VERSION ""

NS_ :

BS_:

BU_: WCM4 WCM3 WCM2 WCM VPM VLM VKM VICM VECM VDM VCU_RTOS_ETH VCU_ENTRY_ETH VCU_AGVM_ETH VCU UVM UPM TIM TEST_TOOL_1 TCP_ETH TCP TCM TCCM SRR_SRR_ETH SRR_SRR SRR_SLR_ETH SRR_SLR SRR_RR SRR_RF_ETH SRR_RF SRR_LR_CR SRR_LF_ETH SRR_LF SIB SDM SCL SBZA_R SBZA_L SBM SAM_RR SAM_RF SAM_LR SAM_LF SAM_BH SADS RadioLow_ETH RadioLow RSI_RTOS_ETH RSI RDCM PTM PLCM PFCM PDR_ETH PDR PCM PA ODS2 ODS NVM MTCM_R MTCM_L MSM_RR MSM_P MSM_LR MSM_D MSB2 MSB1 MRCM_R MRCM_L MFC LRR_RR_ETH LRR_LR_ETH LRR_CF_ETH LRR LRL_CF_ETH LIB_48V LIB1 IPC_INT IPC_GP IPC ICS_Info ICCM HVAC_FP_R HVAC_FP_F HUD_CAN HDLM FPI_RTOS_ETH FPI FOPM FCM_LC FCM EPSb EPS_1 EPSRAb EPSRAa EPS EOCM_HC_Superset EOCM_HCP2 EOCM ELM ECP_X1 ECP_S2 ECP_S ECP_MC ECP_H3 ECP_H2 ECP_H1 ECP_E ECM EBCM DMS DEFC DCM CSM_ETH CSM_AV CSM CGM_OTA_ETH CGM BSM_MH BSM_HEV BSM BCM ARS ARB APA AOS AMP ALC AHS AHL_AFL ADIMb ADIMa ACP2_MCU

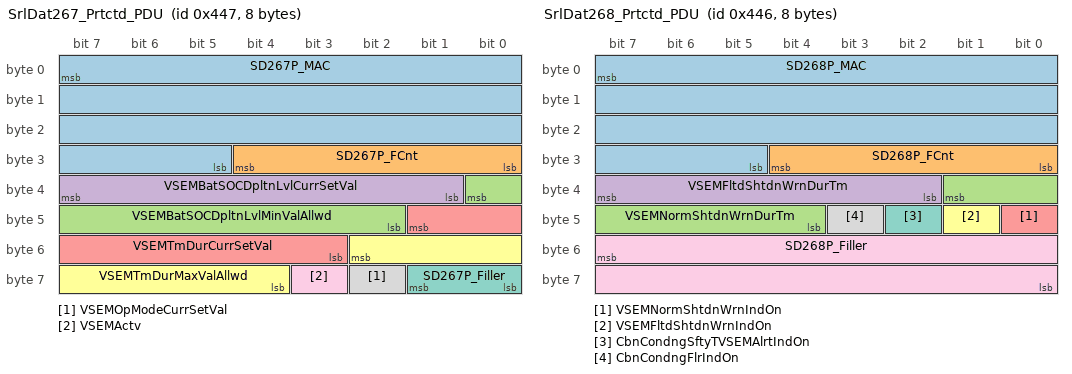
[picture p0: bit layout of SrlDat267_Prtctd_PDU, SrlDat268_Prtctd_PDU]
BO_ 1095 SrlDat267_Prtctd_PDU: 8 CGM
 SG_ SD267P_MAC : 7|27@0+ (1,0) [0|1.34218e+008] "" TCP
 SG_ SD267P_FCnt : 28|5@0+ (1,0) [0|31] "" TCP
 SG_ VSEMBatSOCDpltnLvlMinValAllwd : 32|7@0+ (1,0) [0|127] "%" TCP,VCU
 SG_ VSEMBatSOCDpltnLvlCurrSetVal : 39|7@0+ (1,0) [0|127] "%" TCP,VCU
 SG_ VSEMTmDurCurrSetVal : 41|7@0+ (15,0) [0|1905] "min" TCP,VCU
 SG_ VSEMTmDurMaxValAllwd : 50|7@0+ (15,0) [0|1905] "min" TCP,VCU
 SG_ SD267P_Filler : 57|2@0+ (1,0) [0|3] "" TCP
 SG_ VSEMOpModeCurrSetVal : 58|1@0+ (1,0) [0|1] "" TCP,VCU
 SG_ VSEMActv : 59|1@0+ (1,0) [0|1] "" TCP,VCU

BO_ 1092 SrlDat268_PCSM_PDU: 8 CGM
 SG_ SrlDat268_PCSM : 0|64@1+ (1,0) [0|1.84467e+019] "" TCP

BO_ 1094 SrlDat268_Prtctd_PDU: 8 CGM
 SG_ SD268P_MAC : 7|27@0+ (1,0) [0|1.34218e+008] "" TCP
 SG_ SD268P_FCnt : 28|5@0+ (1,0) [0|31] "" TCP
 SG_ VSEMNormShtdnWrnDurTm : 33|6@0+ (1,0) [0|63] "min" TCP,VCU
 SG_ VSEMFltdShtdnWrnDurTm : 39|6@0+ (1,0) [0|63] "min" TCP,VCU
 SG_ VSEMNormShtdnWrnIndOn : 40|1@0+ (1,0) [0|1] "" TCP,VCU
 SG_ VSEMFltdShtdnWrnIndOn : 41|1@0+ (1,0) [0|1] "" TCP,VCU
 SG_ CbnCondngSftyTVSEMAlrtIndOn : 42|1@0+ (1,0) [0|1] "" TCP,VCU
 SG_ CbnCondngFlrIndOn : 43|1@0+ (1,0) [0|1] "" TCP,VCU
 SG_ SD268P_Filler : 55|16@0+ (1,0) [0|65535] "" TCP

BO_ 1096 SrlDat269_PCSM_PDU: 8 VCU
 SG_ SrlDat269_PCSM : 0|64@1+ (1,0) [0|1.84467e+019] "" PLCM,TCP

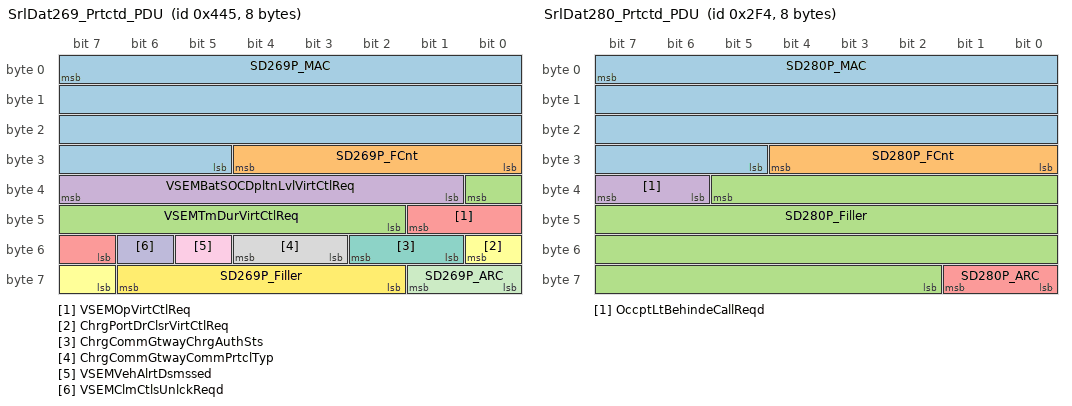
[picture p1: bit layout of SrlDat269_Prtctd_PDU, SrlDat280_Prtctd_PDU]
BO_ 1093 SrlDat269_Prtctd_PDU: 8 VCU
 SG_ SD269P_MAC : 7|27@0+ (1,0) [0|1.34218e+008] "" PLCM,TCP
 SG_ SD269P_FCnt : 28|5@0+ (1,0) [0|31] "" PLCM,TCP
 SG_ VSEMTmDurVirtCtlReq : 32|7@0+ (15,0) [0|1905] "min" PLCM,TCP
 SG_ VSEMBatSOCDpltnLvlVirtCtlReq : 39|7@0+ (1,0) [0|127] "%" PLCM,TCP
 SG_ VSEMOpVirtCtlReq : 41|3@0+ (1,0) [0|5] "" PLCM,TCP
 SG_ ChrgPortDrClsrVirtCtlReq : 48|2@0+ (1,0) [0|2] "" PLCM,TCP
 SG_ ChrgCommGtwayChrgAuthSts : 50|2@0+ (1,0) [0|3] "" PLCM,TCP
 SG_ ChrgCommGtwayCommPrtclTyp : 52|2@0+ (1,0) [0|3] "" PLCM,TCP
 SG_ VSEMVehAlrtDsmssed : 53|1@0+ (1,0) [0|1] "" PLCM,TCP
 SG_ VSEMClmCtlsUnlckReqd : 54|1@0+ (1,0) [0|1] "" PLCM,TCP
 SG_ SD269P_ARC : 57|2@0+ (1,0) [0|3] "" PLCM,TCP
 SG_ SD269P_Filler : 62|5@0+ (1,0) [0|31] "" PLCM,TCP

BO_ 976 SrlDat280_PCSM_PDU: 8 CGM
 SG_ SrlDat280_PCSM : 0|64@1+ (1,0) [0|1.84467e+019] "" TCP

BO_ 756 SrlDat280_Prtctd_PDU: 8 CGM
 SG_ SD280P_MAC : 7|27@0+ (1,0) [0|1.34218e+008] "" TCP
 SG_ SD280P_FCnt : 28|5@0+ (1,0) [0|31] "" TCP
 SG_ SD280P_Filler : 37|28@0+ (1,0) [0|2.68435e+008] "" TCP
 SG_ OccptLtBehindeCallReqd : 39|2@0+ (1,0) [0|3] "" TCP
 SG_ SD280P_ARC : 57|2@0+ (1,0) [0|3] "" TCP

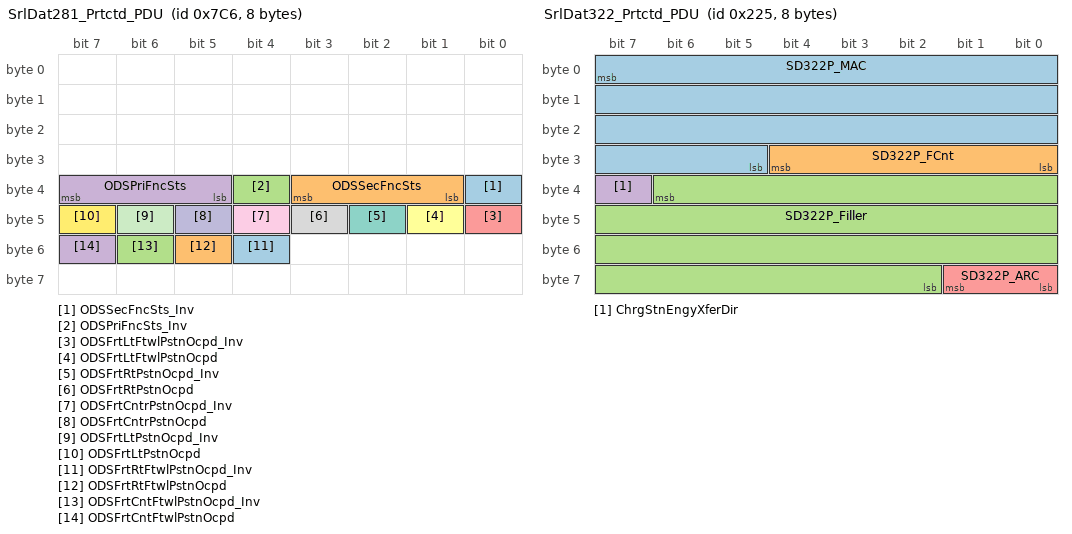
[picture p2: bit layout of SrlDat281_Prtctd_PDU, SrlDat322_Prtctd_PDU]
BO_ 1990 SrlDat281_Prtctd_PDU: 8 CGM
 SG_ ODSSecFncSts_Inv : 32|1@0+ (1,0) [0|1] "" TCP
 SG_ ODSSecFncSts : 35|3@0+ (1,0) [0|7] "" TCP
 SG_ ODSPriFncSts_Inv : 36|1@0+ (1,0) [0|1] "" TCP
 SG_ ODSPriFncSts : 39|3@0+ (1,0) [0|7] "" TCP
 SG_ ODSFrtLtFtwlPstnOcpd_Inv : 40|1@0+ (1,0) [0|1] "" TCP
 SG_ ODSFrtLtFtwlPstnOcpd : 41|1@0+ (1,0) [0|1] "" TCP
 SG_ ODSFrtRtPstnOcpd_Inv : 42|1@0+ (1,0) [0|1] "" TCP
 SG_ ODSFrtRtPstnOcpd : 43|1@0+ (1,0) [0|1] "" TCP
 SG_ ODSFrtCntrPstnOcpd_Inv : 44|1@0+ (1,0) [0|1] "" TCP
 SG_ ODSFrtCntrPstnOcpd : 45|1@0+ (1,0) [0|1] "" TCP
 SG_ ODSFrtLtPstnOcpd_Inv : 46|1@0+ (1,0) [0|1] "" TCP
 SG_ ODSFrtLtPstnOcpd : 47|1@0+ (1,0) [0|1] "" TCP
 SG_ ODSFrtRtFtwlPstnOcpd_Inv : 52|1@0+ (1,0) [0|1] "" TCP
 SG_ ODSFrtRtFtwlPstnOcpd : 53|1@0+ (1,0) [0|1] "" TCP
 SG_ ODSFrtCntFtwlPstnOcpd_Inv : 54|1@0+ (1,0) [0|1] "" TCP
 SG_ ODSFrtCntFtwlPstnOcpd : 55|1@0+ (1,0) [0|1] "" TCP

BO_ 1081 SrlDat282_Prtctd_PDU: 8 CGM
 SG_ ODSSecRwLtFtwlPstOcpd_Inv : 32|1@0+ (1,0) [0|1] "" TCP
 SG_ ODSSecRwLtFtwlPstOcpd : 33|1@0+ (1,0) [0|1] "" TCP
 SG_ ODSSecRowRtPstnOcpd_Inv : 34|1@0+ (1,0) [0|1] "" TCP
 SG_ ODSSecRowRtPstnOcpd : 35|1@0+ (1,0) [0|1] "" TCP
 SG_ ODSSecRowCntPstnOcpd_Inv : 36|1@0+ (1,0) [0|1] "" TCP
 SG_ ODSSecRowCntPstnOcpd : 37|1@0+ (1,0) [0|1] "" TCP
 SG_ ODSSecRowLtPstnOcpd_Inv : 38|1@0+ (1,0) [0|1] "" TCP
 SG_ ODSSecRowLtPstnOcpd : 39|1@0+ (1,0) [0|1] "" TCP
 SG_ ODSThrdRwCntrPstnOcpd_Inv : 40|1@0+ (1,0) [0|1] "" TCP
 SG_ ODSThrdRwCntrPstnOcpd : 41|1@0+ (1,0) [0|1] "" TCP
 SG_ ODSThrdRowLtPstnOcpd_Inv : 42|1@0+ (1,0) [0|1] "" TCP
 SG_ ODSThrdRowLtPstnOcpd : 43|1@0+ (1,0) [0|1] "" TCP
 SG_ ODSSecRwRtFtwlPstOcpd_Inv : 44|1@0+ (1,0) [0|1] "" TCP
 SG_ ODSSecRwRtFtwlPstOcpd : 45|1@0+ (1,0) [0|1] "" TCP
 SG_ ODSSecRwCntFtwlPstOcpd_Inv : 46|1@0+ (1,0) [0|1] "" TCP
 SG_ ODSSecRwCntFtwlPstOcpd : 47|1@0+ (1,0) [0|1] "" TCP
 SG_ ODSThrdRwRtFtwlPstOcpd_Inv : 48|1@0+ (1,0) [0|1] "" TCP
 SG_ ODSThrdRwRtFtwlPstOcpd : 49|1@0+ (1,0) [0|1] "" TCP
 SG_ ODSThrdRwCntFtlPstOcpd_Inv : 50|1@0+ (1,0) [0|1] "" TCP
 SG_ ODSThrdRwCntFtlPstOcpd : 51|1@0+ (1,0) [0|1] "" TCP
 SG_ ODSThrdRwLtFtwlPstOcpd_Inv : 52|1@0+ (1,0) [0|1] "" TCP
 SG_ ODSThrdRwLtFtwlPstOcpd : 53|1@0+ (1,0) [0|1] "" TCP
 SG_ ODSThrdRowRtPstnOcpd_Inv : 54|1@0+ (1,0) [0|1] "" TCP
 SG_ ODSThrdRowRtPstnOcpd : 55|1@0+ (1,0) [0|1] "" TCP
 SG_ ODSCrgRtPstnOcpd_Inv : 58|1@0+ (1,0) [0|1] "" TCP
 SG_ ODSCrgRtPstnOcpd : 59|1@0+ (1,0) [0|1] "" TCP
 SG_ ODSCrgCntrPstnOcpd_Inv : 60|1@0+ (1,0) [0|1] "" TCP
 SG_ ODSCrgCntrPstnOcpd : 61|1@0+ (1,0) [0|1] "" TCP
 SG_ ODSCrgLtPstnOcpd_Inv : 62|1@0+ (1,0) [0|1] "" TCP
 SG_ ODSCrgLtPstnOcpd : 63|1@0+ (1,0) [0|1] "" TCP

BO_ 981 SrlDat322_PCSM_PDU: 8 VCU
 SG_ SrlDat322_PCSM : 0|64@1+ (1,0) [0|1.84467e+019] "" Vector__XXX

BO_ 549 SrlDat322_Prtctd_PDU: 8 VCU
 SG_ SD322P_MAC : 7|27@0+ (1,0) [0|1.34218e+008] "" Vector__XXX
 SG_ SD322P_FCnt : 28|5@0+ (1,0) [0|31] "" Vector__XXX
 SG_ SD322P_Filler : 38|29@0+ (1,0) [0|5.36871e+008] "" Vector__XXX
 SG_ ChrgStnEngyXferDir : 39|1@0+ (1,0) [0|1] "" Vector__XXX
 SG_ SD322P_ARC : 57|2@0+ (1,0) [0|3] "" Vector__XXX

BO_ 1397 SrlDat34_PCSM_PDU: 8 CGM
 SG_ SrlDat34_PCSM : 0|64@1+ (1,0) [0|1.84467e+019] "" TCP,IPC,IPC_INT,VCU

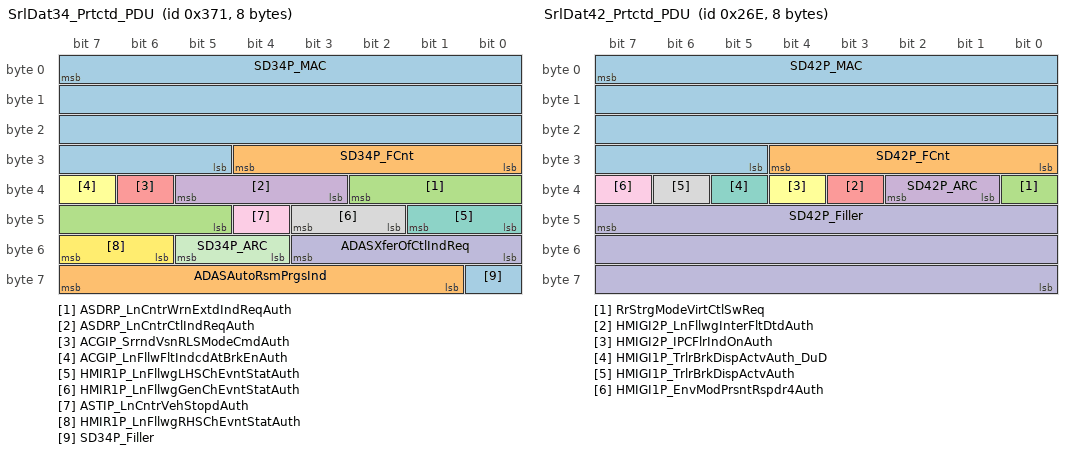
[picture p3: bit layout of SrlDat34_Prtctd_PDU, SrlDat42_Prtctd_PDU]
BO_ 881 SrlDat34_Prtctd_PDU: 8 CGM
 SG_ SD34P_MAC : 7|27@0+ (1,0) [0|1.34218e+008] "" TCP,IPC,IPC_INT,VCU
 SG_ SD34P_FCnt : 28|5@0+ (1,0) [0|31] "" TCP,IPC,IPC_INT,VCU
 SG_ ASDRP_LnCntrWrnExtdIndReqAuth : 34|6@0+ (1,0) [0|63] "" TCP,IPC,IPC_INT,VCU
 SG_ ASDRP_LnCntrCtlIndReqAuth : 37|3@0+ (1,0) [0|5] "" TCP,CSM,CSM_AV,IPC,IPC_INT,VCU
 SG_ ACGIP_SrrndVsnRLSModeCmdAuth : 38|1@0+ (1,0) [0|1] "" TCP,IPC,IPC_INT,VCU
 SG_ ACGIP_LnFllwFltIndcdAtBrkEnAuth : 39|1@0+ (1,0) [0|1] "" TCP,IPC,IPC_INT,VCU
 SG_ HMIR1P_LnFllwgLHSChEvntStatAuth : 41|2@0+ (1,0) [0|2] "" AMP,TCP,CSM,CSM_AV,IPC,IPC_INT,VCU
 SG_ HMIR1P_LnFllwgGenChEvntStatAuth : 43|2@0+ (1,0) [0|2] "" AMP,TCP,CSM,CSM_AV,IPC,IPC_INT,VCU
 SG_ ASTIP_LnCntrVehStopdAuth : 44|1@0+ (1,0) [0|1] "" TCP,IPC,IPC_INT,VCU
 SG_ ADASXferOfCtlIndReq : 51|4@0+ (1,0) [0|7] "" TCP,IPC,IPC_INT,VCU
 SG_ SD34P_ARC : 53|2@0+ (1,0) [0|3] "" TCP,IPC,IPC_INT,VCU
 SG_ HMIR1P_LnFllwgRHSChEvntStatAuth : 55|2@0+ (1,0) [0|2] "" AMP,TCP,CSM,CSM_AV,IPC,IPC_INT,VCU
 SG_ SD34P_Filler : 56|1@0+ (1,0) [0|1] "" TCP,IPC,IPC_INT,VCU
 SG_ ADASAutoRsmPrgsInd : 63|7@0+ (1,0) [0|127] "%" TCP,IPC,IPC_INT,VCU

BO_ 898 SrlDat42_PCSM_PDU: 8 IPC
 SG_ SrlDat42_PCSM : 0|64@1+ (1,0) [0|1.84467e+019] "" Vector__XXX

BO_ 622 SrlDat42_Prtctd_PDU: 8 IPC
 SG_ SD42P_MAC : 7|27@0+ (1,0) [0|1.34218e+008] "" Vector__XXX
 SG_ SD42P_FCnt : 28|5@0+ (1,0) [0|31] "" Vector__XXX
 SG_ RrStrgModeVirtCtlSwReq : 32|1@0+ (1,0) [0|1] "" Vector__XXX
 SG_ SD42P_ARC : 34|2@0+ (1,0) [0|3] "" Vector__XXX
 SG_ HMIGI2P_LnFllwgInterFltDtdAuth : 35|1@0+ (1,0) [0|1] "" Vector__XXX
 SG_ HMIGI2P_IPCFlrIndOnAuth : 36|1@0+ (1,0) [0|1] "" Vector__XXX
 SG_ HMIGI1P_TrlrBrkDispActvAuth_DuD : 37|1@0+ (1,0) [0|1] "" Vector__XXX
 SG_ HMIGI1P_TrlrBrkDispActvAuth : 38|1@0+ (1,0) [0|1] "" Vector__XXX
 SG_ HMIGI1P_EnvModPrsntRspdr4Auth : 39|1@0+ (1,0) [0|1] "" Vector__XXX
 SG_ SD42P_Filler : 47|24@0+ (1,0) [0|1.67772e+007] "" Vector__XXX

BO_ 1359 SrlDat49_PCSM_PDU: 8 TCP
 SG_ SrlDat49_PCSM : 0|64@1+ (1,0) [0|1.84467e+019] "" VKM,VCU

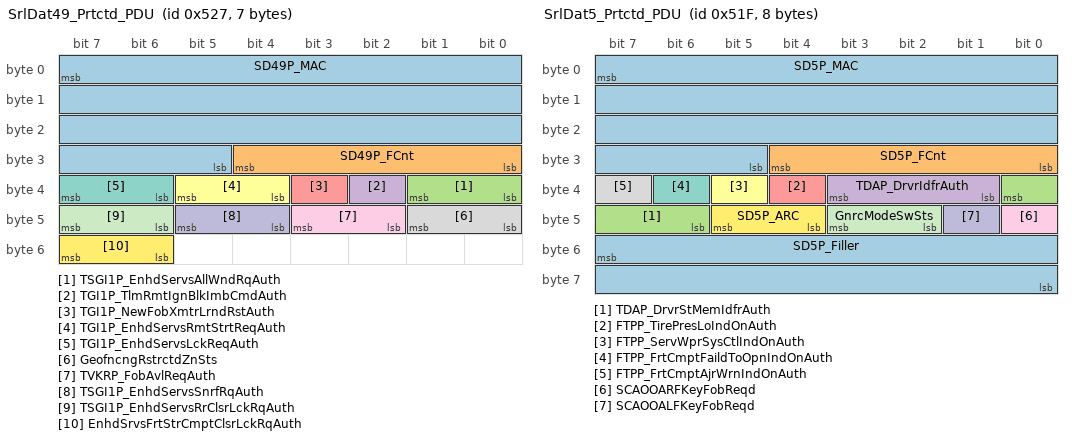
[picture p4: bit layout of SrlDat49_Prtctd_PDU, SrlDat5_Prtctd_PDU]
BO_ 1319 SrlDat49_Prtctd_PDU: 7 TCP
 SG_ SD49P_MAC : 7|27@0+ (1,0) [0|1.34218e+008] "" VKM,VCU
 SG_ SD49P_FCnt : 28|5@0+ (1,0) [0|31] "" VKM,VCU
 SG_ TSGI1P_EnhdServsAllWndRqAuth : 33|2@0+ (1,0) [0|3] "" VKM,VCU
 SG_ TGI1P_TlmRmtIgnBlkImbCmdAuth : 34|1@0+ (1,0) [0|1] "" VKM,VCU
 SG_ TGI1P_NewFobXmtrLrndRstAuth : 35|1@0+ (1,0) [0|1] "" VKM,VCU
 SG_ TGI1P_EnhdServsRmtStrtReqAuth : 37|2@0+ (1,0) [0|2] "" RadioLow,VKM,CSM,CSM_AV,VCU
 SG_ TGI1P_EnhdServsLckReqAuth : 39|2@0+ (1,0) [0|2] "" VKM,VCU
 SG_ GeofncngRstrctdZnSts : 41|2@0+ (1,0) [0|2] "" VKM,VCU
 SG_ TVKRP_FobAvlReqAuth : 43|2@0+ (1,0) [0|3] "" VKM,VCU
 SG_ TSGI1P_EnhdServsSnrfRqAuth : 45|2@0+ (1,0) [0|3] "" VKM,VCU
 SG_ TSGI1P_EnhdServsRrClsrLckRqAuth : 47|2@0+ (1,0) [0|2] "" VKM,VCU
 SG_ EnhdSrvsFrtStrCmptClsrLckRqAuth : 55|2@0+ (1,0) [0|2] "" VKM,VCU

BO_ 1361 SrlDat5_PCSM_PDU: 8 CGM
 SG_ SrlDat5_PCSM : 0|64@1+ (1,0) [0|1.84467e+019] "" IPC,IPC_INT,VCU

BO_ 1311 SrlDat5_Prtctd_PDU: 8 CGM
 SG_ SD5P_MAC : 7|27@0+ (1,0) [0|1.34218e+008] "" IPC,IPC_INT,VCU
 SG_ SD5P_FCnt : 28|5@0+ (1,0) [0|31] "" IPC,IPC_INT,VCU
 SG_ TDAP_DrvrStMemIdfrAuth : 32|3@0+ (1,0) [0|7] "" CSM,CSM_AV,IPC,IPC_INT,VCU
 SG_ TDAP_DrvrIdfrAuth : 35|3@0+ (1,0) [0|7] "" TCP,CSM,CSM_AV,IPC,IPC_INT,VCU,WCM
 SG_ FTPP_TirePresLoIndOnAuth : 36|1@0+ (1,0) [0|1] "" VKM,CSM,CSM_AV,IPC,IPC_INT,VCU
 SG_ FTPP_ServWprSysCtlIndOnAuth : 37|1@0+ (1,0) [0|1] "" TCP,IPC,IPC_INT,VCU
 SG_ FTPP_FrtCmptFaildToOpnIndOnAuth : 38|1@0+ (1,0) [0|1] "" IPC,IPC_INT,VCU
 SG_ FTPP_FrtCmptAjrWrnIndOnAuth : 39|1@0+ (1,0) [0|1] "" IPC,IPC_INT,VCU
 SG_ SCAOOARFKeyFobReqd : 40|1@0+ (1,0) [0|1] "" IPC,IPC_INT,VCU
 SG_ SCAOOALFKeyFobReqd : 41|1@0+ (1,0) [0|1] "" IPC,IPC_INT,VCU
 SG_ GnrcModeSwSts : 43|2@0+ (1,0) [0|3] "" IPC,IPC_INT,VCU
 SG_ SD5P_ARC : 45|2@0+ (1,0) [0|3] "" IPC,IPC_INT,VCU
 SG_ SD5P_Filler : 55|16@0+ (1,0) [0|65535] "" IPC,IPC_INT,VCU

BO_ 1396 SrlDat6_PCSM_PDU: 8 CGM
 SG_ SrlDat6_PCSM : 0|64@1+ (1,0) [0|1.84467e+019] "" PLCM,TCP,VCU

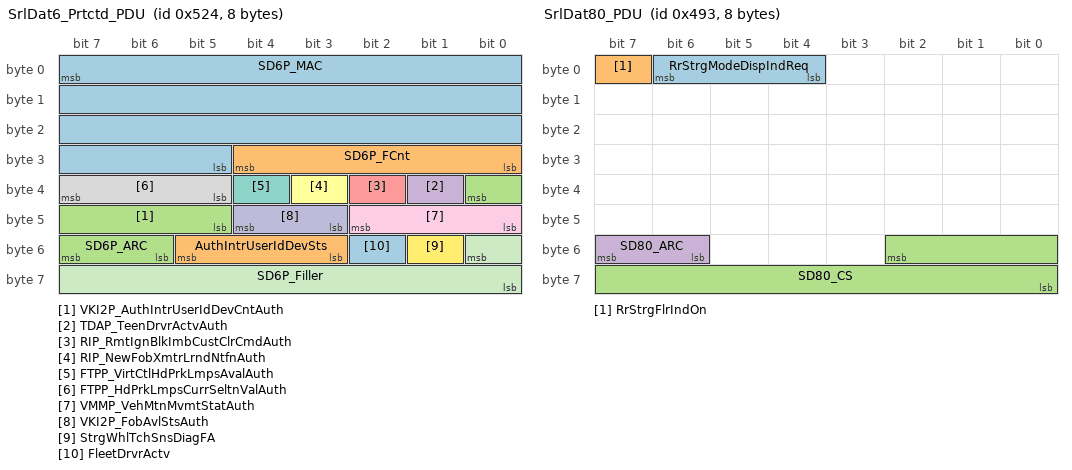
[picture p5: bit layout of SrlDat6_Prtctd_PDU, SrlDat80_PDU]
BO_ 1316 SrlDat6_Prtctd_PDU: 8 CGM
 SG_ SD6P_MAC : 7|27@0+ (1,0) [0|1.34218e+008] "" PLCM,TCP,VCU
 SG_ SD6P_FCnt : 28|5@0+ (1,0) [0|31] "" PLCM,TCP,VCU
 SG_ VKI2P_AuthIntrUserIdDevCntAuth : 32|4@0+ (1,0) [0|15] "Count" PLCM,TCP,VKM,VCU
 SG_ TDAP_TeenDrvrActvAuth : 33|1@0+ (1,0) [0|1] "" PDR,PLCM,RadioLow,TCP,CSM,CSM_AV,IPC,IPC_INT,VCU
 SG_ RIP_RmtIgnBlkImbCustClrCmdAuth : 34|1@0+ (1,0) [0|1] "" PLCM,TCP,VCU
 SG_ RIP_NewFobXmtrLrndNtfnAuth : 35|1@0+ (1,0) [0|1] "" PLCM,TCP,VCU
 SG_ FTPP_VirtCtlHdPrkLmpsAvalAuth : 36|1@0+ (1,0) [0|1] "" PLCM,TCP,VCU
 SG_ FTPP_HdPrkLmpsCurrSeltnValAuth : 39|3@0+ (1,0) [0|4] "" PLCM,TCP,VCU
 SG_ VMMP_VehMtnMvmtStatAuth : 42|3@0+ (1,0) [0|4] "" ICS_Info,PLCM,RadioLow,TCP,VKM,CSM,CSM_AV,VCU
 SG_ VKI2P_FobAvlStsAuth : 44|2@0+ (1,0) [0|3] "" PLCM,TCP,VKM,VCU
 SG_ SD6P_Filler : 48|9@0+ (1,0) [0|511] "" PLCM,TCP,VCU
 SG_ StrgWhlTchSnsDiagFA : 49|1@0+ (1,0) [0|1] "" PLCM,TCP,VCU
 SG_ FleetDrvrActv : 50|1@0+ (1,0) [0|1] "" PLCM,TCP,IPC,IPC_INT,VCU
 SG_ AuthIntrUserIdDevSts : 53|3@0+ (1,0) [0|5] "" PLCM,TCP,VKM,VCU
 SG_ SD6P_ARC : 55|2@0+ (1,0) [0|3] "" PLCM,TCP,VCU

BO_ 713 SrlDat7_PDU: 8 CGM
 SG_ KMORAI_AllwdTm : 7|8@0+ (1,0) [0|255] "Min" IPC,IPC_INT,VCU
 SG_ RestrtVehIndOn : 8|1@0+ (1,0) [0|1] "" IPC,IPC_INT,VCU
 SG_ PrtctdIdlUnvIndOn : 9|1@0+ (1,0) [0|1] "" IPC,IPC_INT,VCU
 SG_ PrtctdIdlIndOn : 10|1@0+ (1,0) [0|1] "" IPC,IPC_INT,VCU
 SG_ NoKeyFndTryAgnIndOn : 11|1@0+ (1,0) [0|1] "" IPC,IPC_INT,VCU
 SG_ NoKeyDtdMechShfDndIndOn : 12|1@0+ (1,0) [0|1] "" IPC,IPC_INT,VCU
 SG_ KyIdDevNotPrIO : 13|1@0+ (1,0) [0|1] "" VKM,IPC,IPC_INT,VCU
 SG_ KeyMisgCkForKeyIndOn : 14|1@0+ (1,0) [0|1] "" IPC,IPC_INT,VCU
 SG_ KMORAI_IndOn : 15|1@0+ (1,0) [0|1] "" IPC,IPC_INT,VCU
 SG_ SSVI_AutoShtdnTmr : 18|8@0+ (1,0) [0|255] "Min" IPC,IPC_INT,VCU
 SG_ SSVI_AutoShtdnIO : 19|1@0+ (1,0) [0|1] "" IPC,IPC_INT,VCU
 SG_ SSVI_AutoShtdnDsbldIO : 20|1@0+ (1,0) [0|1] "" IPC,IPC_INT,VCU
 SG_ SSVI_AppPrkBrkIO : 21|1@0+ (1,0) [0|1] "" IPC,IPC_INT,VCU
 SG_ SSVI_AppClchPedIO : 22|1@0+ (1,0) [0|1] "" TCP,IPC,IPC_INT,VCU
 SG_ SSVI_AppBrkPedIO : 23|1@0+ (1,0) [0|1] "" TCP,IPC,IPC_INT,VCU
 SG_ SSVI_KylsStrtUseXmtrPcktIO : 24|1@0+ (1,0) [0|1] "" IPC,IPC_INT,VCU
 SG_ SSVI_KeyMvmtRqrdIndOn : 25|1@0+ (1,0) [0|1] "" IPC,IPC_INT,VCU
 SG_ SSVI_ClsEngCmptToStrtVehIO : 26|1@0+ (1,0) [0|1] "" IPC,IPC_INT,VCU
 SG_ SSVI_ShfToNeutPrssStrtAgnIO : 32|1@0+ (1,0) [0|1] "" IPC,IPC_INT,VCU
 SG_ SSVI_PrssStrtAgnIO : 33|1@0+ (1,0) [0|1] "" IPC,IPC_INT,VCU
 SG_ SSVI_PrssClchPrssStrtAgnIO : 34|1@0+ (1,0) [0|1] "" IPC,IPC_INT,VCU
 SG_ SSVI_PrssClchBrkForStrtIO : 35|1@0+ (1,0) [0|1] "" IPC,IPC_INT,VCU
 SG_ SSVI_PrssBtnAgnToTrnEngOffIO : 36|1@0+ (1,0) [0|1] "" IPC,IPC_INT,VCU
 SG_ SSVI_NoRmtDtdPrssClchToRestrtIO : 37|1@0+ (1,0) [0|1] "" IPC,IPC_INT,VCU
 SG_ SSVI_NoRmtDtdPrssBrkToRestrtIO : 38|1@0+ (1,0) [0|1] "" IPC,IPC_INT,VCU
 SG_ SSVI_NoRmtDtdIO : 39|1@0+ (1,0) [0|1] "" TCP,IPC,IPC_INT,VCU
 SG_ VhOpgStatUIDDtdPrssBrkToStrtIO : 40|1@0+ (1,0) [0|1] "" IPC,IPC_INT,VCU
 SG_ VhOpgStatClsDrOrPrssBrkToStrtIO : 41|1@0+ (1,0) [0|1] "" IPC,IPC_INT,VCU
 SG_ PPMVehOnExtModeActv : 42|1@0+ (1,0) [0|1] "" IPC,IPC_INT,VCU
 SG_ XmtrSecurConfRqrdIO : 43|1@0+ (1,0) [0|1] "" CSM,CSM_AV,IPC,IPC_INT,VCU
 SG_ VehLoBatIndOn : 44|1@0+ (1,0) [0|1] "" IPC,IPC_INT,VCU
 SG_ VehInNeutShfToDrvIndOn : 45|1@0+ (1,0) [0|1] "" IPC,IPC_INT,VCU
 SG_ ShfToNeutRestrtVehIndOn : 46|1@0+ (1,0) [0|1] "" IPC,IPC_INT,VCU
 SG_ SSVI_ShfToPrkIO : 47|1@0+ (1,0) [0|1] "" IPC,IPC_INT,VCU
 SG_ SD7_CS : 50|11@0+ (1,0) [0|2047] "" IPC,IPC_INT,VCU
 SG_ PPMExtModeActvEnsBatChrgLvlIO : 53|1@0+ (1,0) [0|1] "" IPC,IPC_INT,VCU
 SG_ SD7_ARC : 55|2@0+ (1,0) [0|3] "" IPC,IPC_INT,VCU

BO_ 1171 SrlDat80_PDU: 8 CGM
 SG_ RrStrgModeDispIndReq : 6|3@0+ (1,0) [0|5] "" CSM,CSM_AV,IPC,IPC_INT,VCU
 SG_ RrStrgFlrIndOn : 7|1@0+ (1,0) [0|1] "" IPC,IPC_INT,VCU
 SG_ SD80_CS : 50|11@0+ (1,0) [0|2047] "" IPC,IPC_INT,VCU
 SG_ SD80_ARC : 55|2@0+ (1,0) [0|3] "" IPC,IPC_INT,VCU

BO_ 1336 SrlDat86_PCSM_PDU: 8 CGM
 SG_ SrlDat86_PCSM : 0|64@1+ (1,0) [0|1.84467e+019] "" VCU

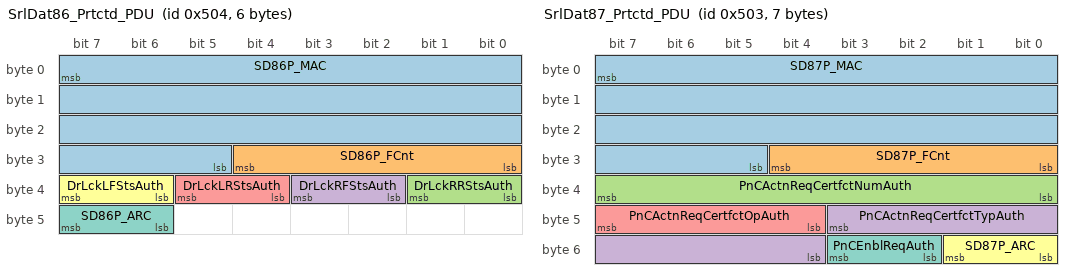
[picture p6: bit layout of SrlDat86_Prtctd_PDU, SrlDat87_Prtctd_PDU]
BO_ 1284 SrlDat86_Prtctd_PDU: 6 CGM
 SG_ SD86P_MAC : 7|27@0+ (1,0) [0|1.34218e+008] "" VCU
 SG_ SD86P_FCnt : 28|5@0+ (1,0) [0|31] "" VCU
 SG_ DrLckRRStsAuth : 33|2@0+ (1,0) [0|2] "" VKM,VCU
 SG_ DrLckRFStsAuth : 35|2@0+ (1,0) [0|2] "" VKM,VCU
 SG_ DrLckLRStsAuth : 37|2@0+ (1,0) [0|2] "" VKM,VCU
 SG_ DrLckLFStsAuth : 39|2@0+ (1,0) [0|2] "" VKM,VCU
 SG_ SD86P_ARC : 47|2@0+ (1,0) [0|3] "" VCU

BO_ 1335 SrlDat87_PCSM_PDU: 8 VCU
 SG_ SrlDat87_PCSM : 0|64@1+ (1,0) [0|1.84467e+019] "" Vector__XXX

BO_ 1283 SrlDat87_Prtctd_PDU: 7 VCU
 SG_ SD87P_MAC : 7|27@0+ (1,0) [0|1.34218e+008] "" Vector__XXX
 SG_ SD87P_FCnt : 28|5@0+ (1,0) [0|31] "" Vector__XXX
 SG_ PnCActnReqCertfctNumAuth : 39|8@0+ (1,0) [0|255] "" Vector__XXX
 SG_ PnCActnReqCertfctTypAuth : 43|8@0+ (1,0) [0|14] "" Vector__XXX
 SG_ PnCActnReqCertfctOpAuth : 47|4@0+ (1,0) [0|4] "" Vector__XXX
 SG_ SD87P_ARC : 49|2@0+ (1,0) [0|3] "" Vector__XXX
 SG_ PnCEnblReqAuth : 51|2@0+ (1,0) [0|3] "" Vector__XXX

BO_ 640 SrlDat92_PCSM_PDU: 8 VKM
 SG_ SrlDat92_PCSM : 0|64@1+ (1,0) [0|1.84467e+019] "" Vector__XXX

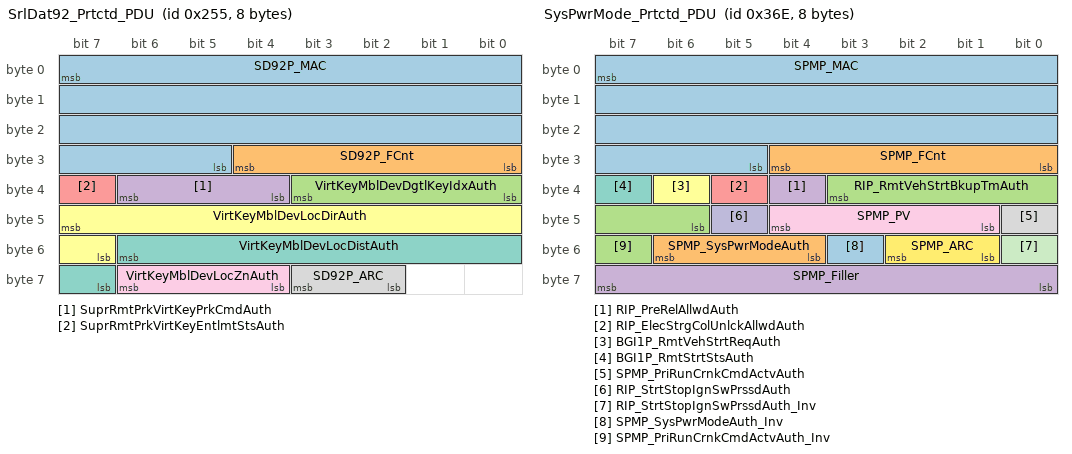
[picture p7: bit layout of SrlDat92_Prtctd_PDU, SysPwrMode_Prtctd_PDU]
BO_ 597 SrlDat92_Prtctd_PDU: 8 VKM
 SG_ SD92P_MAC : 7|27@0+ (1,0) [0|1.34218e+008] "" Vector__XXX
 SG_ SD92P_FCnt : 28|5@0+ (1,0) [0|31] "" Vector__XXX
 SG_ VirtKeyMblDevDgtlKeyIdxAuth : 35|4@0+ (1,0) [0|15] "" Vector__XXX
 SG_ SuprRmtPrkVirtKeyPrkCmdAuth : 38|3@0+ (1,0) [0|7] "" Vector__XXX
 SG_ SuprRmtPrkVirtKeyEntlmtStsAuth : 39|1@0+ (1,0) [0|1] "" Vector__XXX
 SG_ VirtKeyMblDevLocDirAuth : 47|9@0+ (1,0) [0|511] "Deg" Vector__XXX
 SG_ VirtKeyMblDevLocDistAuth : 54|8@0+ (0.2,0) [0|51] "m" Vector__XXX
 SG_ SD92P_ARC : 59|2@0+ (1,0) [0|3] "" Vector__XXX
 SG_ VirtKeyMblDevLocZnAuth : 62|3@0+ (1,0) [0|4] "" Vector__XXX

BO_ 1403 SysPwrMode_PCSM_PDU: 8 CGM
 SG_ SysPwrMode_PCSM : 0|64@1+ (1,0) [0|1.84467e+019] "" VKM

BO_ 878 SysPwrMode_Prtctd_PDU: 8 CGM
 SG_ SPMP_MAC : 7|27@0+ (1,0) [0|1.34218e+008] "" VKM
 SG_ SPMP_FCnt : 28|5@0+ (1,0) [0|31] "" VKM
 SG_ RIP_RmtVehStrtBkupTmAuth : 35|6@0+ (1,0) [0|63] "min" TCP,VKM
 SG_ RIP_PreRelAllwdAuth : 36|1@0+ (1,0) [0|1] "" TCP,VKM
 SG_ RIP_ElecStrgColUnlckAllwdAuth : 37|1@0+ (1,0) [0|1] "" TCP,VKM
 SG_ BGI1P_RmtVehStrtReqAuth : 38|1@0+ (1,0) [0|1] "" VKM,CSM,CSM_AV,IPC,IPC_INT,VCU
 SG_ BGI1P_RmtStrtStsAuth : 39|1@0+ (1,0) [0|1] "" RadioLow,TCP,VKM,CSM,CSM_AV,IPC,IPC_INT,VCU
 SG_ SPMP_PriRunCrnkCmdActvAuth : 40|1@0+ (1,0) [0|1] "" VKM,IPC,IPC_INT,VCU
 SG_ SPMP_PV : 44|4@0+ (1,0) [0|15] "" HVAC_FP_R,VKM,IPC,IPC_INT,VCU
 SG_ RIP_StrtStopIgnSwPrssdAuth : 45|1@0+ (1,0) [0|1] "" RadioLow,TCP,VKM,CSM,CSM_AV,VCU
 SG_ RIP_StrtStopIgnSwPrssdAuth_Inv : 48|1@0+ (1,0) [0|1] "" RadioLow,TCP,VKM,CSM,CSM_AV,VCU
 SG_ SPMP_ARC : 50|2@0+ (1,0) [0|3] "" HVAC_FP_R,VKM,IPC,IPC_INT,VCU
 SG_ SPMP_SysPwrModeAuth_Inv : 51|1@0+ (1,0) [0|1] "" AMP,FPI,HVAC_FP_F,HVAC_FP_R,ICS_Info,PDR,MFC,PLCM,RSI,RadioLow,TCP,VKM,CSM,CSM_AV,IPC,IPC_INT,VCU,WCM,WCM2,WCM3,WCM4
 SG_ SPMP_SysPwrModeAuth : 54|3@0+ (1,0) [0|4] "" AMP,FPI,HVAC_FP_F,HVAC_FP_R,ICS_Info,PDR,MFC,PLCM,RSI,RadioLow,TCP,VKM,CSM,CSM_AV,IPC,IPC_INT,VCU,WCM,WCM2,WCM3,WCM4
 SG_ SPMP_PriRunCrnkCmdActvAuth_Inv : 55|1@0+ (1,0) [0|1] "" VKM,IPC,IPC_INT,VCU
 SG_ SPMP_Filler : 63|8@0+ (1,0) [0|255] "" VKM

BO_ 407 TCP_NM_PDU_On_CAN_5_Cluster: 8 TCP
 SG_ ISignal_TCP_CAN_5_Cluster : 23|48@0+ (1,0) [0|281474976710655] "" AMP,CGM,FPI,HVAC_FP_F,HVAC_FP_R,ICS_Info,PDR,MFC,PLCM,RSI,RadioLow,VKM,CSM,CSM_AV,IPC,IPC_INT,VCU,WCM,WCM2,WCM3,WCM4

BO_ 1358 TlmGPSDateSrc_PCSM_PDU: 8 TCP
 SG_ TlmGPSDateSrc_PCSM : 0|64@1+ (1,0) [0|1.84467e+019] "" CGM,VKM

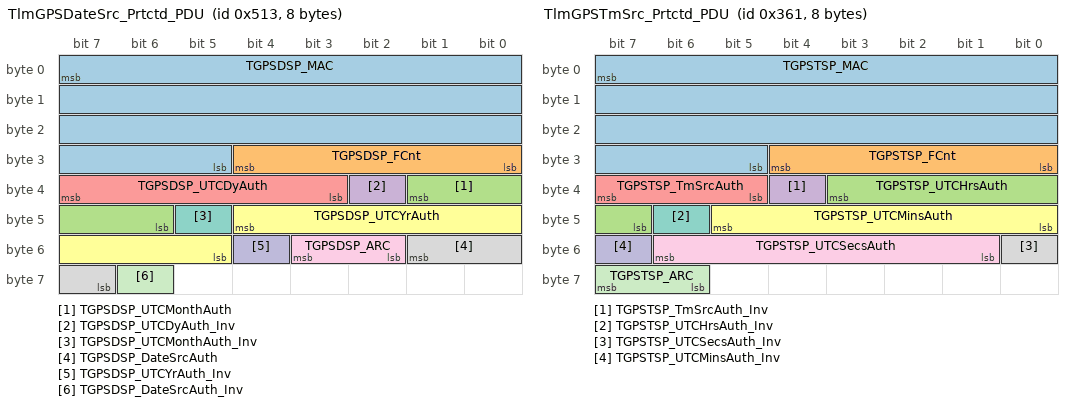
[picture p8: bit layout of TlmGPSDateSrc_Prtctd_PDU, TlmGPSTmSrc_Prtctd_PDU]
BO_ 1299 TlmGPSDateSrc_Prtctd_PDU: 8 TCP
 SG_ TGPSDSP_MAC : 7|27@0+ (1,0) [0|1.34218e+008] "" CGM,VKM
 SG_ TGPSDSP_FCnt : 28|5@0+ (1,0) [0|31] "" CGM,VKM
 SG_ TGPSDSP_UTCMonthAuth : 33|4@0+ (1,0) [0|12] "" CGM,VKM
 SG_ TGPSDSP_UTCDyAuth_Inv : 34|1@0+ (1,0) [0|1] "" CGM,VKM
 SG_ TGPSDSP_UTCDyAuth : 39|5@0+ (1,0) [0|31] "day" CGM,VKM
 SG_ TGPSDSP_UTCYrAuth : 44|8@0+ (1,2000) [2000|2255] "year" CGM,VKM
 SG_ TGPSDSP_UTCMonthAuth_Inv : 45|1@0+ (1,0) [0|1] "" CGM,VKM
 SG_ TGPSDSP_DateSrcAuth : 49|3@0+ (1,0) [0|3] "" CGM,VKM
 SG_ TGPSDSP_ARC : 51|2@0+ (1,0) [0|3] "" CGM,VKM
 SG_ TGPSDSP_UTCYrAuth_Inv : 52|1@0+ (1,0) [0|1] "" CGM,VKM
 SG_ TGPSDSP_DateSrcAuth_Inv : 62|1@0+ (1,0) [0|1] "" CGM,VKM

BO_ 1357 TlmGPSTmSrc_PCSM_PDU: 8 TCP
 SG_ TlmGPSTmSrc_PCSM : 0|64@1+ (1,0) [0|1.84467e+019] "" CGM,VKM

BO_ 865 TlmGPSTmSrc_Prtctd_PDU: 8 TCP
 SG_ TGPSTSP_MAC : 7|27@0+ (1,0) [0|1.34218e+008] "" CGM,VKM
 SG_ TGPSTSP_FCnt : 28|5@0+ (1,0) [0|31] "" CGM,VKM
 SG_ TGPSTSP_UTCHrsAuth : 35|5@0+ (1,0) [0|31] "hour" CGM,VKM
 SG_ TGPSTSP_TmSrcAuth_Inv : 36|1@0+ (1,0) [0|1] "" CGM,VKM
 SG_ TGPSTSP_TmSrcAuth : 39|3@0+ (1,0) [0|3] "" CGM,VKM
 SG_ TGPSTSP_UTCMinsAuth : 45|6@0+ (1,0) [0|63] "minutes" CGM,VKM
 SG_ TGPSTSP_UTCHrsAuth_Inv : 46|1@0+ (1,0) [0|1] "" CGM,VKM
 SG_ TGPSTSP_UTCSecsAuth_Inv : 48|1@0+ (1,0) [0|1] "" CGM,VKM
 SG_ TGPSTSP_UTCSecsAuth : 54|6@0+ (1,0) [0|63] "seconds" CGM,VKM
 SG_ TGPSTSP_UTCMinsAuth_Inv : 55|1@0+ (1,0) [0|1] "" CGM,VKM
 SG_ TGPSTSP_ARC : 63|2@0+ (1,0) [0|3] "" CGM,VKM

BO_ 601 Data_SrlDat72_Prtctd_PDU: 33 TCP
 SG_ SD72P_MAC : 7|32@0+ (1,0) [0|4.29497e+009] "" VKM
 SG_ SD72P_FCnt : 39|64@0+ (1,0) [0|1.84467e+019] "" VKM
 SG_ DgtlKeyReqIdfrAuth : 103|160@0+ (1,0) [0|0] "" VKM
 SG_ DgtlKeyMgmtReqAuth : 263|4@0+ (1,0) [0|6] "" VKM

BO_ 592 Data_SrlDat73_Prtctd_PDU: 33 VKM
 SG_ SD73P_MAC : 7|32@0+ (1,0) [0|4.29497e+009] "" TCP
 SG_ SD73P_FCnt : 39|64@0+ (1,0) [0|1.84467e+019] "" TCP
 SG_ DgtlKeyRespIdfrAuth : 103|160@0+ (1,0) [0|0] "" TCP
 SG_ DgtlKeyMgmtRespAuth : 263|4@0+ (1,0) [0|9] "" TCP

BO_ 599 Data_SrlDat74_Prtctd_PDU: 124 TCP
 SG_ SD74P_MAC : 7|32@0+ (1,0) [0|4.29497e+009] "" VKM
 SG_ SD74P_FCnt : 39|64@0+ (1,0) [0|1.84467e+019] "" VKM
 SG_ DgtlKeyPwVrfrAuth : 103|896@0+ (1,0) [0|0] "" VKM

BO_ 600 FlwCtrl_SrlDat72_Prtctd_PDU: 8 VKM

BO_ 595 FlwCtrl_SrlDat73_Prtctd_PDU: 8 TCP

BO_ 598 FlwCtrl_SrlDat74_Prtctd_PDU: 8 VKM

BO_ 1909 IPC_LCMFileDat_Data_CAN5_PDU: 4095 IPC
 SG_ IPC_LCMFileDat : 7|32760@0+ (1,0) [0|0] "" RadioLow,CSM,CSM_AV

BO_ 1156 IPC_LCMFileDat_FlwCtrl_PDU: 8 RadioLow

BO_ 42 Tp_MFC_LCMFileDat_Data_PDU: 4095 MFC
 SG_ MFC_LCMFileDat : 7|32760@0+ (1,0) [0|0] "" VCU

BO_ 116 Tp_MFC_LCMFileDat_FlwCtrl_PDU: 3 VCU

BO_ 1971 Tp_PLCM_LCMFileDat_Data_PDU: 4095 PLCM
 SG_ PLCM_LCMFileDat : 7|32760@0+ (1,0) [0|0] "" VCU

BO_ 1207 Tp_PLCM_LCMFileDat_FlwCtrl_PDU: 8 VCU

BO_ 1920 Tp_SrlDat136_Prtctd_Data_PDU: 20 VCU
 SG_ SD136P_MAC : 7|32@0+ (1,0) [0|4.29497e+009] "" VKM
 SG_ SD136P_FCnt : 39|64@0+ (1,0) [0|1.84467e+019] "" VKM
 SG_ VirtKeyCldUserAuthInfo : 103|64@0+ (1,0) [0|18446744073709551615] "" VKM

BO_ 1921 Tp_SrlDat136_Prtctd_FlwCtrl_PDU: 8 VKM

BO_ 1922 Tp_SrlDat137_Prtctd_Data_PDU: 172 VKM
 SG_ SD137P_MAC : 7|32@0+ (1,0) [0|4.29497e+009] "" VCU
 SG_ SD137P_FCnt : 39|64@0+ (1,0) [0|1.84467e+019] "" VCU
 SG_ VirtKeyCldUserIdDat1 : 103|64@0+ (1,0) [0|18446744073709551615] "" VCU
 SG_ VirtKeyCldUserIdDat2 : 167|64@0+ (1,0) [0|18446744073709551615] "" VCU
 SG_ VirtKeyCldUserIdDat3 : 231|64@0+ (1,0) [0|18446744073709551615] "" VCU
 SG_ VirtKeyCldUserIdDat4 : 295|64@0+ (1,0) [0|18446744073709551615] "" VCU
 SG_ VirtKeyCldUserIdDat5 : 359|64@0+ (1,0) [0|18446744073709551615] "" VCU
 SG_ VirtKeyCldUserIdDat6 : 423|64@0+ (1,0) [0|18446744073709551615] "" VCU
 SG_ VirtKeyCldUserIdDat7 : 487|64@0+ (1,0) [0|18446744073709551615] "" VCU
 SG_ VirtKeyCldUserIdDat8 : 551|64@0+ (1,0) [0|18446744073709551615] "" VCU
 SG_ VirtKeyUserInfo1 : 615|64@0+ (1,0) [0|18446744073709551615] "" VCU
 SG_ VirtKeyUserInfo2 : 679|64@0+ (1,0) [0|18446744073709551615] "" VCU
 SG_ VirtKeyUserInfo3 : 743|384@0+ (1,0) [0|0] "" VCU
 SG_ VirtKeyUserInfo4 : 1127|64@0+ (1,0) [0|18446744073709551615] "" VCU
 SG_ VirtKeyUserInfo5 : 1191|64@0+ (1,0) [0|18446744073709551615] "" VCU
 SG_ VirtKeyUserInfo6 : 1255|64@0+ (1,0) [0|18446744073709551615] "" VCU
 SG_ VirtKeyUserInfo7 : 1319|64@0+ (1,0) [0|18446744073709551615] "" VCU

BO_ 1923 Tp_SrlDat137_Prtctd_FlwCtrl_PDU: 8 VCU

BO_ 1928 Tp_SrlDat275_Prtctd_Data_PDU: 19 VCU
 SG_ SD275P_MAC : 7|32@0+ (1,0) [0|4.29497e+009] "" PLCM
 SG_ SD275P_FCnt : 39|64@0+ (1,0) [0|1.84467e+019] "" PLCM
 SG_ ChrgCommCtlrMACAddr : 103|48@0+ (1,0) [0|281474976710655] "" PLCM
 SG_ ChrgCommCtlrMACAddr_DuD : 151|1@0+ (1,0) [0|1] "" PLCM

BO_ 1929 Tp_SrlDat275_Prtctd_FlwCtrl_PDU: 8 PLCM

BO_ 125 Tp_SrlDat321_Prtctd_Data_PDU: 3024 PLCM
 SG_ SD321P_MAC : 7|128@0+ (1,0) [0|340282366920938463463374607431768211455] "" VCU
 SG_ SD321P_FCnt : 135|64@0+ (1,0) [0|1.84467e+019] "" VCU
 SG_ FlxblChrgBrdgItrsnDtnSysNtfn : 199|24000@0+ (1,0) [0|0] "" VCU

BO_ 126 Tp_SrlDat321_Prtctd_FlwCtrl_PDU: 3 VCU

BO_ 948 TCP_LCMFileDat_Data_CAN5_PDU: 4095 TCP
 SG_ TCP_LCMFileDat : 7|32760@0+ (1,0) [0|0] "" RadioLow,CSM,CSM_AV,VCU

BO_ 949 TCP_LCMFileDat_FlwCtrl_PDU: 8 RadioLow

BO_ 717 VirtKeyLngTrmKeyAtstn_Data_PDU: 4095 TCP
 SG_ VirtKeyLngTrmKeyAtstn : 7|32760@0+ (1,0) [0|0] "" VKM

BO_ 682 VirtKeyLngTrmKeyAtstn_FlwCtrl_PD: 3 VKM

BO_ 715 VirtKeyLngTrmKey_Data_PDU: 4095 VKM
 SG_ VirtKeyLngTrmKey : 7|32760@0+ (1,0) [0|0] "" TCP

BO_ 716 VirtKeyLngTrmKey_FlwCtrl_PDU: 8 TCP

BO_ 950 WCM_LCMFileDat_Data_CAN5_PDU: 4095 WCM
 SG_ WCM_LCMFileDat : 7|32760@0+ (1,0) [0|0] "" RadioLow,CSM,CSM_AV,VCU

BO_ 951 WCM_LCMFileDat_FlwCtrl_PDU: 8 RadioLow

BO_ 1545 USDT_Req_BootMode_To_ADIMa_CAN_2: 8 TCP

BO_ 1544 USDT_Req_BootMode_To_ADIMb_CAN_2: 8 TCP

BO_ 1650 USDT_Req_BootMode_To_AHL_AFL_CAN: 8 TCP

BO_ 1585 USDT_Req_BootMode_To_AHS_CAN_2_c: 8 TCP

BO_ 1594 USDT_Req_BootMode_To_ALC_CAN_3_c: 8 TCP

BO_ 1665 USDT_Req_BootMode_To_AMP_CAN_5_c: 8 CGM

BO_ 1625 USDT_Req_BootMode_To_AOS_CAN_1_c: 8 TCP

BO_ 1723 USDT_Req_BootMode_To_APA_CAN_2_c: 8 TCP

BO_ 1714 USDT_Req_BootMode_To_ARB_CAN_1_c: 8 TCP

BO_ 1586 USDT_Req_BootMode_To_ARS_CAN_2_c: 8 TCP

BO_ 1600 USDT_Req_BootMode_To_BCM_CAN_9_c: 8 TCP

BO_ 1739 USDT_Req_BootMode_To_BSM_CAN_2_c: 8 TCP

BO_ 1664 USDT_Req_BootMode_To_CSM_AV_CAN_: 8 CGM

BO_ 1563 USDT_Req_BootMode_To_DCM_CAN_2_c: 8 TCP

BO_ 1556 USDT_Req_BootMode_To_DEFC_CAN_1_: 8 TCP

BO_ 1642 USDT_Req_BootMode_To_DMS_CAN_2_c: 8 TCP

BO_ 1576 USDT_Req_BootMode_To_EBCM_CAN_2_: 8 TCP

BO_ 1553 USDT_Req_BootMode_To_ECM_CAN_2_c: 8 TCP

BO_ 1559 USDT_Req_BootMode_To_ECP_E_CAN_2: 8 TCP

BO_ 1565 USDT_Req_BootMode_To_ECP_H2_CAN_: 8 TCP

BO_ 1566 USDT_Req_BootMode_To_ECP_H3_CAN_: 8 TCP

BO_ 1601 USDT_Req_BootMode_To_ELM_CAN_9_c: 8 TCP

BO_ 1644 USDT_Req_BootMode_To_EOCM_CAN_8_: 8 TCP

BO_ 1755 USDT_Req_BootMode_To_EOCM_HCP2_C: 8 TCP

BO_ 1636 USDT_Req_BootMode_To_EOCM_HC_Sup: 8 TCP

BO_ 1584 USDT_Req_BootMode_To_EPSRAb_CAN_: 8 TCP

BO_ 1588 USDT_Req_BootMode_To_EPS_1_CAN_1: 8 TCP

BO_ 1589 USDT_Req_BootMode_To_EPSb_CAN_2_: 8 TCP

BO_ 1725 USDT_Req_BootMode_To_FCM_CAN_2_c: 8 TCP

BO_ 1724 USDT_Req_BootMode_To_FCM_LC_CAN_: 8 TCP

BO_ 1765 USDT_Req_BootMode_To_FOPM_CAN_2_: 8 TCP

BO_ 1632 USDT_Req_BootMode_To_FPI_CAN_5_c: 8 CGM

BO_ 1646 USDT_Req_BootMode_To_HDLM_CAN_8_: 8 TCP

BO_ 1634 USDT_Req_BootMode_To_HUD_CAN_CAN: 8 TCP

BO_ 1640 USDT_Req_BootMode_To_HVAC_FP_F_C: 8 CGM

BO_ 1690 USDT_Req_BootMode_To_HVAC_FP_R_C: 8 CGM

BO_ 1555 USDT_Req_BootMode_To_ICCM_CAN_3_: 8 TCP

BO_ 1638 USDT_Req_BootMode_To_ICS_Info_CA: 8 CGM

BO_ 1766 USDT_Req_BootMode_To_LIB1_CAN_2_: 8 TCP

BO_ 1772 USDT_Req_BootMode_To_LIB_48V_CAN: 8 TCP

BO_ 1746 USDT_Req_BootMode_To_LRR_CAN_8_c: 8 TCP

BO_ 1677 USDT_Req_BootMode_To_MFC_CAN_5_c: 8 CGM

BO_ 1707 USDT_Req_BootMode_To_MRCM_L_CAN_: 8 TCP

BO_ 1708 USDT_Req_BootMode_To_MRCM_R_CAN_: 8 TCP

BO_ 1628 USDT_Req_BootMode_To_MSB1_CAN_1_: 8 TCP

BO_ 1630 USDT_Req_BootMode_To_MSB2_CAN_1_: 8 TCP

BO_ 1704 USDT_Req_BootMode_To_MSM_D_CAN_4: 8 TCP

BO_ 1706 USDT_Req_BootMode_To_MSM_LR_CAN_: 8 TCP

BO_ 1702 USDT_Req_BootMode_To_MSM_P_CAN_4: 8 TCP

BO_ 1703 USDT_Req_BootMode_To_MSM_RR_CAN_: 8 TCP

BO_ 1713 USDT_Req_BootMode_To_MTCM_L_CAN_: 8 TCP

BO_ 1720 USDT_Req_BootMode_To_MTCM_R_CAN_: 8 TCP

BO_ 1637 USDT_Req_BootMode_To_NVM_CAN_2_c: 8 TCP

BO_ 1719 USDT_Req_BootMode_To_ODS2_CAN_9_: 8 TCP

BO_ 1718 USDT_Req_BootMode_To_ODS_CAN_9_c: 8 TCP

BO_ 1727 USDT_Req_BootMode_To_PA_CAN_1_co: 8 TCP

BO_ 1552 USDT_Req_BootMode_To_PCM_CAN_2_c: 8 TCP

BO_ 1641 USDT_Req_BootMode_To_PDR_CAN_5_c: 8 CGM

BO_ 1715 USDT_Req_BootMode_To_PFCM_CAN_4_: 8 TCP

BO_ 1773 USDT_Req_BootMode_To_PLCM_CAN_5_: 8 CGM

BO_ 1700 USDT_Req_BootMode_To_PTM_CAN_4_c: 8 TCP

BO_ 1562 USDT_Req_BootMode_To_RDCM_CAN_2_: 8 TCP

BO_ 1669 USDT_Req_BootMode_To_RSI_CAN_5_c: 8 CGM

BO_ 1592 USDT_Req_BootMode_To_SADS_CAN_3_: 8 TCP

BO_ 1696 USDT_Req_BootMode_To_SAM_LF_CAN_: 8 TCP

BO_ 1698 USDT_Req_BootMode_To_SAM_LR_CAN_: 8 TCP

BO_ 1697 USDT_Req_BootMode_To_SAM_RF_CAN_: 8 TCP

BO_ 1699 USDT_Req_BootMode_To_SAM_RR_CAN_: 8 TCP

BO_ 1579 USDT_Req_BootMode_To_SBM_CAN_3_c: 8 TCP

BO_ 1721 USDT_Req_BootMode_To_SBZA_L_CAN_: 8 TCP

BO_ 1722 USDT_Req_BootMode_To_SBZA_R_CAN_: 8 TCP

BO_ 1730 USDT_Req_BootMode_To_SCL_CAN_1_c: 8 TCP

BO_ 1624 USDT_Req_BootMode_To_SDM_CAN_9_c: 8 TCP

BO_ 1606 USDT_Req_BootMode_To_SIB_CAN_1_c: 8 TCP

BO_ 1747 USDT_Req_BootMode_To_SRR_LF_CAN_: 8 TCP

BO_ 1751 USDT_Req_BootMode_To_SRR_LR_CR_C: 8 TCP

BO_ 1750 USDT_Req_BootMode_To_SRR_RF_CAN_: 8 TCP

BO_ 1752 USDT_Req_BootMode_To_SRR_RR_CAN_: 8 TCP

BO_ 1753 USDT_Req_BootMode_To_SRR_SLR_CAN: 8 TCP

BO_ 1754 USDT_Req_BootMode_To_SRR_SRR_CAN: 8 TCP

BO_ 1560 USDT_Req_BootMode_To_TCM_CAN_2_c: 8 TCP

BO_ 1687 USDT_Req_BootMode_To_TCP_CAN_5_c: 8 CGM

BO_ 1653 USDT_Req_BootMode_To_TIM_CAN_4_c: 8 TCP

BO_ 1770 USDT_Req_BootMode_To_UPM_CAN_8_c: 8 TCP

BO_ 1616 USDT_Req_BootMode_To_UVM_CAN_1_c: 8 TCP

BO_ 1612 USDT_Req_BootMode_To_VDM_CAN_2_c: 8 TCP

BO_ 1741 USDT_Req_BootMode_To_VECM_CAN_2_: 8 TCP

BO_ 1684 USDT_Req_BootMode_To_VKM_CAN_5_c: 8 CGM

BO_ 1593 USDT_Req_BootMode_To_VLM_CAN_3_c: 8 TCP

BO_ 1645 USDT_Req_BootMode_To_VPM_CAN_1_c: 8 TCP

BO_ 1731 USDT_Req_BootMode_To_WCM2_CAN_5_: 8 CGM

BO_ 1732 USDT_Req_BootMode_To_WCM3_CAN_5_: 8 CGM

BO_ 1733 USDT_Req_BootMode_To_WCM4_CAN_5_: 8 CGM

BO_ 1726 USDT_Req_BootMode_To_WCM_CAN_5_c: 8 CGM

BO_ 2497348081 USDT_Req_From_TEST_TOOL_1_To_AMP: 8 CGM

BO_ 2430336753 USDT_Req_From_TEST_TOOL_1_To_All: 7 CGM

BO_ 2431385329 USDT_Req_From_TEST_TOOL_1_To_CAN: 7 CGM

BO_ 2497347825 USDT_Req_From_TEST_TOOL_1_To_CSM: 8 CGM

BO_ 2565832945 USDT_Req_From_TEST_TOOL_1_To_C01: 8 CGM

BO_ 2497339633 USDT_Req_From_TEST_TOOL_1_To_FPI: 8 CGM

BO_ 2497341681 USDT_Req_From_TEST_TOOL_1_To_HVA: 8 CGM

BO_ 2497354481 USDT_Req_From_TEST_TOOL_1_To_H01: 8 CGM

BO_ 2497341169 USDT_Req_From_TEST_TOOL_1_To_ICS: 8 CGM

BO_ 2497351153 USDT_Req_From_TEST_TOOL_1_To_MFC: 8 CGM

BO_ 2497341937 USDT_Req_From_TEST_TOOL_1_To_PDR: 8 CGM

BO_ 2497375729 USDT_Req_From_TEST_TOOL_1_To_PLC: 8 CGM

BO_ 2497349105 USDT_Req_From_TEST_TOOL_1_To_RSI: 8 CGM

BO_ 2497353713 USDT_Req_From_TEST_TOOL_1_To_TCP: 8 CGM

BO_ 2497352945 USDT_Req_From_TEST_TOOL_1_To_VKM: 8 CGM

BO_ 2497364977 USDT_Req_From_TEST_TOOL_1_To_WCM: 8 CGM

BO_ 2497365233 USDT_Req_From_TEST_TOOL_1_To_W01: 8 CGM

BO_ 2497365489 USDT_Req_From_TEST_TOOL_1_To_W02: 8 CGM

BO_ 2497363697 USDT_Req_From_TEST_TOOL_1_To_W03: 8 CGM

BO_ 2497348082 USDT_Req_From_TEST_TOOL_2_To_AMP: 8 CGM

BO_ 2430336754 USDT_Req_From_TEST_TOOL_2_To_All: 7 CGM

BO_ 2431385330 USDT_Req_From_TEST_TOOL_2_To_CAN: 7 CGM

BO_ 2497347826 USDT_Req_From_TEST_TOOL_2_To_CSM: 8 CGM

BO_ 2497339634 USDT_Req_From_TEST_TOOL_2_To_FPI: 8 CGM

BO_ 2497341682 USDT_Req_From_TEST_TOOL_2_To_HVA: 8 CGM

BO_ 2497354482 USDT_Req_From_TEST_TOOL_2_To_H01: 8 CGM

BO_ 2497341170 USDT_Req_From_TEST_TOOL_2_To_ICS: 8 CGM

BO_ 2497351154 USDT_Req_From_TEST_TOOL_2_To_MFC: 8 CGM

BO_ 2497341938 USDT_Req_From_TEST_TOOL_2_To_PDR: 8 CGM

BO_ 2497375730 USDT_Req_From_TEST_TOOL_2_To_PLC: 8 CGM

BO_ 2497349106 USDT_Req_From_TEST_TOOL_2_To_RSI: 8 CGM

BO_ 2497353714 USDT_Req_From_TEST_TOOL_2_To_TCP: 8 CGM

BO_ 2497352946 USDT_Req_From_TEST_TOOL_2_To_VKM: 8 CGM

BO_ 2497364978 USDT_Req_From_TEST_TOOL_2_To_WCM: 8 CGM

BO_ 2497365234 USDT_Req_From_TEST_TOOL_2_To_W01: 8 CGM

BO_ 2497365490 USDT_Req_From_TEST_TOOL_2_To_W02: 8 CGM

BO_ 2497363698 USDT_Req_From_TEST_TOOL_2_To_W03: 8 CGM

BO_ 2485808371 USDT_Req_From_TEST_TOOL_3_To_ACP: 8 TCP

BO_ 2492099827 USDT_Req_From_TEST_TOOL_3_To_A01: 8 TCP

BO_ 2494171635 USDT_Req_From_TEST_TOOL_3_To_ADI: 8 TCP

BO_ 2497317363 USDT_Req_From_TEST_TOOL_3_To_A02: 8 TCP

BO_ 2486831603 USDT_Req_From_TEST_TOOL_3_To_A03: 8 TCP

BO_ 2493123059 USDT_Req_From_TEST_TOOL_3_To_A04: 8 TCP

BO_ 2494171379 USDT_Req_From_TEST_TOOL_3_To_A05: 8 TCP

BO_ 2497317107 USDT_Req_From_TEST_TOOL_3_To_A06: 8 TCP

BO_ 2486831347 USDT_Req_From_TEST_TOOL_3_To_A07: 8 TCP

BO_ 2493122803 USDT_Req_From_TEST_TOOL_3_To_A08: 8 TCP

BO_ 2497344243 USDT_Req_From_TEST_TOOL_3_To_AHL: 8 TCP

BO_ 2497327603 USDT_Req_From_TEST_TOOL_3_To_AHS: 8 TCP

BO_ 2497329907 USDT_Req_From_TEST_TOOL_3_To_ALC: 8 TCP

BO_ 2497348083 USDT_Req_From_TEST_TOOL_3_To_AMP: 8 TCP

BO_ 2497337843 USDT_Req_From_TEST_TOOL_3_To_AOS: 8 TCP

BO_ 2484780019 USDT_Req_From_TEST_TOOL_3_To_APA: 8 TCP

BO_ 2497362931 USDT_Req_From_TEST_TOOL_3_To_A09: 8 TCP

BO_ 2497360627 USDT_Req_From_TEST_TOOL_3_To_ARB: 8 TCP

BO_ 2497327859 USDT_Req_From_TEST_TOOL_3_To_ARS: 8 TCP

BO_ 2430336755 USDT_Req_From_TEST_TOOL_3_To_All: 7 TCP

BO_ 2497331443 USDT_Req_From_TEST_TOOL_3_To_BCM: 8 TCP

BO_ 2497367027 USDT_Req_From_TEST_TOOL_3_To_BSM: 8 TCP

BO_ 2486881267 USDT_Req_From_TEST_TOOL_3_To_B01: 8 TCP

BO_ 2493172723 USDT_Req_From_TEST_TOOL_3_To_B02: 8 TCP

BO_ 2429288179 USDT_Req_From_TEST_TOOL_3_To_CAN: 7 TCP

BO_ 2417753843 USDT_Req_From_TEST_TOOL_3_To_C01: 7 TCP

BO_ 2418802419 USDT_Req_From_TEST_TOOL_3_To_C02: 7 TCP

BO_ 2419850995 USDT_Req_From_TEST_TOOL_3_To_C03: 7 TCP

BO_ 2420899571 USDT_Req_From_TEST_TOOL_3_To_C04: 7 TCP

BO_ 2431385331 USDT_Req_From_TEST_TOOL_3_To_C05: 7 TCP

BO_ 2425093875 USDT_Req_From_TEST_TOOL_3_To_C06: 7 TCP

BO_ 2426142451 USDT_Req_From_TEST_TOOL_3_To_C07: 7 TCP

BO_ 2497332723 USDT_Req_From_TEST_TOOL_3_To_CGM: 8 TCP

BO_ 2497347827 USDT_Req_From_TEST_TOOL_3_To_CSM: 8 TCP

BO_ 2497321971 USDT_Req_From_TEST_TOOL_3_To_DCM: 8 TCP

BO_ 2497320179 USDT_Req_From_TEST_TOOL_3_To_DEF: 8 TCP

BO_ 2497342195 USDT_Req_From_TEST_TOOL_3_To_DMS: 8 TCP

BO_ 2497325299 USDT_Req_From_TEST_TOOL_3_To_EBC: 8 TCP

BO_ 2486839539 USDT_Req_From_TEST_TOOL_3_To_E01: 8 TCP

BO_ 2497319411 USDT_Req_From_TEST_TOOL_3_To_ECM: 8 TCP

BO_ 2486833651 USDT_Req_From_TEST_TOOL_3_To_E02: 8 TCP

BO_ 2497320947 USDT_Req_From_TEST_TOOL_3_To_ECP: 8 TCP

BO_ 2493126643 USDT_Req_From_TEST_TOOL_3_To_E03: 8 TCP

BO_ 2497322483 USDT_Req_From_TEST_TOOL_3_To_E04: 8 TCP

BO_ 2493128179 USDT_Req_From_TEST_TOOL_3_To_E05: 8 TCP

BO_ 2497322739 USDT_Req_From_TEST_TOOL_3_To_E06: 8 TCP

BO_ 2493128435 USDT_Req_From_TEST_TOOL_3_To_E07: 8 TCP

BO_ 2486835187 USDT_Req_From_TEST_TOOL_3_To_E08: 8 TCP

BO_ 2497331699 USDT_Req_From_TEST_TOOL_3_To_ELM: 8 TCP

BO_ 2486856947 USDT_Req_From_TEST_TOOL_3_To_EOC: 8 TCP

BO_ 2497342707 USDT_Req_From_TEST_TOOL_3_To_E09: 8 TCP

BO_ 2497371123 USDT_Req_From_TEST_TOOL_3_To_E10: 8 TCP

BO_ 2485806323 USDT_Req_From_TEST_TOOL_3_To_E11: 8 TCP

BO_ 2486854899 USDT_Req_From_TEST_TOOL_3_To_E12: 8 TCP

BO_ 2497340659 USDT_Req_From_TEST_TOOL_3_To_E13: 8 TCP

BO_ 2497327347 USDT_Req_From_TEST_TOOL_3_To_EPS: 8 TCP

BO_ 2497328371 USDT_Req_From_TEST_TOOL_3_To_E14: 8 TCP

BO_ 2497328627 USDT_Req_From_TEST_TOOL_3_To_E15: 8 TCP

BO_ 2497363443 USDT_Req_From_TEST_TOOL_3_To_FCM: 8 TCP

BO_ 2497363187 USDT_Req_From_TEST_TOOL_3_To_F01: 8 TCP

BO_ 2497373683 USDT_Req_From_TEST_TOOL_3_To_FOP: 8 TCP

BO_ 2486887923 USDT_Req_From_TEST_TOOL_3_To_F02: 8 TCP

BO_ 2497339635 USDT_Req_From_TEST_TOOL_3_To_FPI: 8 TCP

BO_ 2497343219 USDT_Req_From_TEST_TOOL_3_To_HDL: 8 TCP

BO_ 2497340147 USDT_Req_From_TEST_TOOL_3_To_HUD: 8 TCP

BO_ 2497341683 USDT_Req_From_TEST_TOOL_3_To_HVA: 8 TCP

BO_ 2497354483 USDT_Req_From_TEST_TOOL_3_To_H01: 8 TCP

BO_ 2497319923 USDT_Req_From_TEST_TOOL_3_To_ICC: 8 TCP

BO_ 2497341171 USDT_Req_From_TEST_TOOL_3_To_ICS: 8 TCP

BO_ 2497373939 USDT_Req_From_TEST_TOOL_3_To_LIB: 8 TCP

BO_ 2497375475 USDT_Req_From_TEST_TOOL_3_To_L01: 8 TCP

BO_ 2497368819 USDT_Req_From_TEST_TOOL_3_To_LRR: 8 TCP

BO_ 2497351155 USDT_Req_From_TEST_TOOL_3_To_MFC: 8 TCP

BO_ 2497358835 USDT_Req_From_TEST_TOOL_3_To_MRC: 8 TCP

BO_ 2497359091 USDT_Req_From_TEST_TOOL_3_To_M01: 8 TCP

BO_ 2497338611 USDT_Req_From_TEST_TOOL_3_To_MSB: 8 TCP

BO_ 2497339123 USDT_Req_From_TEST_TOOL_3_To_M02: 8 TCP

BO_ 2497358067 USDT_Req_From_TEST_TOOL_3_To_MSM: 8 TCP

BO_ 2497358579 USDT_Req_From_TEST_TOOL_3_To_M03: 8 TCP

BO_ 2497357555 USDT_Req_From_TEST_TOOL_3_To_M04: 8 TCP

BO_ 2497357811 USDT_Req_From_TEST_TOOL_3_To_M05: 8 TCP

BO_ 2497360371 USDT_Req_From_TEST_TOOL_3_To_MTC: 8 TCP

BO_ 2497362163 USDT_Req_From_TEST_TOOL_3_To_M06: 8 TCP

BO_ 2497340915 USDT_Req_From_TEST_TOOL_3_To_NVM: 8 TCP

BO_ 2497361907 USDT_Req_From_TEST_TOOL_3_To_ODS: 8 TCP

BO_ 2497361651 USDT_Req_From_TEST_TOOL_3_To_O01: 8 TCP

BO_ 2497363955 USDT_Req_From_TEST_TOOL_3_To_PA_: 8 TCP

BO_ 2497319155 USDT_Req_From_TEST_TOOL_3_To_PCM: 8 TCP

BO_ 2486833395 USDT_Req_From_TEST_TOOL_3_To_P01: 8 TCP

BO_ 2497341939 USDT_Req_From_TEST_TOOL_3_To_PDR: 8 TCP

BO_ 2497360883 USDT_Req_From_TEST_TOOL_3_To_PFC: 8 TCP

BO_ 2497375731 USDT_Req_From_TEST_TOOL_3_To_PLC: 8 TCP

BO_ 2497357043 USDT_Req_From_TEST_TOOL_3_To_PTM: 8 TCP

BO_ 2497321715 USDT_Req_From_TEST_TOOL_3_To_RDC: 8 TCP

BO_ 2497349107 USDT_Req_From_TEST_TOOL_3_To_RSI: 8 TCP

BO_ 2497329395 USDT_Req_From_TEST_TOOL_3_To_SAD: 8 TCP

BO_ 2497356019 USDT_Req_From_TEST_TOOL_3_To_SAM: 8 TCP

BO_ 2497356531 USDT_Req_From_TEST_TOOL_3_To_S01: 8 TCP

BO_ 2497356275 USDT_Req_From_TEST_TOOL_3_To_S02: 8 TCP

BO_ 2497356787 USDT_Req_From_TEST_TOOL_3_To_S03: 8 TCP

BO_ 2494180339 USDT_Req_From_TEST_TOOL_3_To_SBM: 8 TCP

BO_ 2497326067 USDT_Req_From_TEST_TOOL_3_To_S04: 8 TCP

BO_ 2497362419 USDT_Req_From_TEST_TOOL_3_To_SBZ: 8 TCP

BO_ 2497362675 USDT_Req_From_TEST_TOOL_3_To_S05: 8 TCP

BO_ 2497364723 USDT_Req_From_TEST_TOOL_3_To_SCL: 8 TCP

BO_ 2497337587 USDT_Req_From_TEST_TOOL_3_To_SDM: 8 TCP

BO_ 2497332979 USDT_Req_From_TEST_TOOL_3_To_SIB: 8 TCP

BO_ 2497369075 USDT_Req_From_TEST_TOOL_3_To_SRR: 8 TCP

BO_ 2497370099 USDT_Req_From_TEST_TOOL_3_To_S06: 8 TCP

BO_ 2497369843 USDT_Req_From_TEST_TOOL_3_To_S07: 8 TCP

BO_ 2497370355 USDT_Req_From_TEST_TOOL_3_To_S08: 8 TCP

BO_ 2497370611 USDT_Req_From_TEST_TOOL_3_To_S09: 8 TCP

BO_ 2497370867 USDT_Req_From_TEST_TOOL_3_To_S10: 8 TCP

BO_ 2497321203 USDT_Req_From_TEST_TOOL_3_To_TCM: 8 TCP

BO_ 2497345011 USDT_Req_From_TEST_TOOL_3_To_TIM: 8 TCP

BO_ 2497374963 USDT_Req_From_TEST_TOOL_3_To_UPM: 8 TCP

BO_ 2497335539 USDT_Req_From_TEST_TOOL_3_To_UVM: 8 TCP

BO_ 2497334515 USDT_Req_From_TEST_TOOL_3_To_VDM: 8 TCP

BO_ 2493140211 USDT_Req_From_TEST_TOOL_3_To_V01: 8 TCP

BO_ 2497367539 USDT_Req_From_TEST_TOOL_3_To_VEC: 8 TCP

BO_ 2493173235 USDT_Req_From_TEST_TOOL_3_To_V02: 8 TCP

BO_ 2497352947 USDT_Req_From_TEST_TOOL_3_To_VKM: 8 TCP

BO_ 2497329651 USDT_Req_From_TEST_TOOL_3_To_VLM: 8 TCP

BO_ 2497342963 USDT_Req_From_TEST_TOOL_3_To_VPM: 8 TCP

BO_ 2497364979 USDT_Req_From_TEST_TOOL_3_To_WCM: 8 TCP

BO_ 2497365235 USDT_Req_From_TEST_TOOL_3_To_W01: 8 TCP

BO_ 2497365491 USDT_Req_From_TEST_TOOL_3_To_W02: 8 TCP

BO_ 2497363699 USDT_Req_From_TEST_TOOL_3_To_W03: 8 TCP

BO_ 2497348084 USDT_Req_From_TEST_TOOL_4_To_AMP: 8 CGM

BO_ 2430336756 USDT_Req_From_TEST_TOOL_4_To_All: 7 CGM

BO_ 2431385332 USDT_Req_From_TEST_TOOL_4_To_CAN: 7 CGM

BO_ 2497347828 USDT_Req_From_TEST_TOOL_4_To_CSM: 8 CGM

BO_ 2497339636 USDT_Req_From_TEST_TOOL_4_To_FPI: 8 CGM

BO_ 2497341684 USDT_Req_From_TEST_TOOL_4_To_HVA: 8 CGM

BO_ 2497354484 USDT_Req_From_TEST_TOOL_4_To_H01: 8 CGM

BO_ 2497341172 USDT_Req_From_TEST_TOOL_4_To_ICS: 8 CGM

BO_ 2497351156 USDT_Req_From_TEST_TOOL_4_To_MFC: 8 CGM

BO_ 2497341940 USDT_Req_From_TEST_TOOL_4_To_PDR: 8 CGM

BO_ 2497375732 USDT_Req_From_TEST_TOOL_4_To_PLC: 8 CGM

BO_ 2497349108 USDT_Req_From_TEST_TOOL_4_To_RSI: 8 CGM

BO_ 2497353716 USDT_Req_From_TEST_TOOL_4_To_TCP: 8 CGM

BO_ 2497352948 USDT_Req_From_TEST_TOOL_4_To_VKM: 8 CGM

BO_ 2497364980 USDT_Req_From_TEST_TOOL_4_To_WCM: 8 CGM

BO_ 2497365236 USDT_Req_From_TEST_TOOL_4_To_W01: 8 CGM

BO_ 2497365492 USDT_Req_From_TEST_TOOL_4_To_W02: 8 CGM

BO_ 2497363700 USDT_Req_From_TEST_TOOL_4_To_W03: 8 CGM

BO_ 2497348085 USDT_Req_From_TEST_TOOL_5_To_AMP: 8 CGM

BO_ 2430336757 USDT_Req_From_TEST_TOOL_5_To_All: 7 CGM

BO_ 2431385333 USDT_Req_From_TEST_TOOL_5_To_CAN: 7 CGM

BO_ 2497347829 USDT_Req_From_TEST_TOOL_5_To_CSM: 8 CGM

BO_ 2497339637 USDT_Req_From_TEST_TOOL_5_To_FPI: 8 CGM

BO_ 2497341685 USDT_Req_From_TEST_TOOL_5_To_HVA: 8 CGM

BO_ 2497354485 USDT_Req_From_TEST_TOOL_5_To_H01: 8 CGM

BO_ 2497341173 USDT_Req_From_TEST_TOOL_5_To_ICS: 8 CGM

BO_ 2497351157 USDT_Req_From_TEST_TOOL_5_To_MFC: 8 CGM

BO_ 2497341941 USDT_Req_From_TEST_TOOL_5_To_PDR: 8 CGM

BO_ 2497375733 USDT_Req_From_TEST_TOOL_5_To_PLC: 8 CGM

BO_ 2497349109 USDT_Req_From_TEST_TOOL_5_To_RSI: 8 CGM

BO_ 2497353717 USDT_Req_From_TEST_TOOL_5_To_TCP: 8 CGM

BO_ 2497352949 USDT_Req_From_TEST_TOOL_5_To_VKM: 8 CGM

BO_ 2497364981 USDT_Req_From_TEST_TOOL_5_To_WCM: 8 CGM

BO_ 2497365237 USDT_Req_From_TEST_TOOL_5_To_W01: 8 CGM

BO_ 2497365493 USDT_Req_From_TEST_TOOL_5_To_W02: 8 CGM

BO_ 2497363701 USDT_Req_From_TEST_TOOL_5_To_W03: 8 CGM

BO_ 2485808374 USDT_Req_From_TEST_TOOL_6_To_ACP: 8 RadioLow

BO_ 2492099830 USDT_Req_From_TEST_TOOL_6_To_A01: 8 RadioLow

BO_ 2494171638 USDT_Req_From_TEST_TOOL_6_To_ADI: 8 RadioLow

BO_ 2497317366 USDT_Req_From_TEST_TOOL_6_To_A02: 8 RadioLow

BO_ 2486831606 USDT_Req_From_TEST_TOOL_6_To_A03: 8 RadioLow

BO_ 2493123062 USDT_Req_From_TEST_TOOL_6_To_A04: 8 RadioLow

BO_ 2494171382 USDT_Req_From_TEST_TOOL_6_To_A05: 8 RadioLow

BO_ 2497317110 USDT_Req_From_TEST_TOOL_6_To_A06: 8 RadioLow

BO_ 2486831350 USDT_Req_From_TEST_TOOL_6_To_A07: 8 RadioLow

BO_ 2493122806 USDT_Req_From_TEST_TOOL_6_To_A08: 8 RadioLow

BO_ 2497344246 USDT_Req_From_TEST_TOOL_6_To_AHL: 8 RadioLow

BO_ 2497327606 USDT_Req_From_TEST_TOOL_6_To_AHS: 8 RadioLow

BO_ 2497329910 USDT_Req_From_TEST_TOOL_6_To_ALC: 8 RadioLow

BO_ 2497348086 USDT_Req_From_TEST_TOOL_6_To_AMP: 8 RadioLow

BO_ 2497337846 USDT_Req_From_TEST_TOOL_6_To_AOS: 8 RadioLow

BO_ 2484780022 USDT_Req_From_TEST_TOOL_6_To_APA: 8 RadioLow

BO_ 2497362934 USDT_Req_From_TEST_TOOL_6_To_A09: 8 RadioLow

BO_ 2497360630 USDT_Req_From_TEST_TOOL_6_To_ARB: 8 RadioLow

BO_ 2497327862 USDT_Req_From_TEST_TOOL_6_To_ARS: 8 RadioLow

BO_ 2430336758 USDT_Req_From_TEST_TOOL_6_To_All: 7 RadioLow

BO_ 2497331446 USDT_Req_From_TEST_TOOL_6_To_BCM: 8 RadioLow

BO_ 2497367030 USDT_Req_From_TEST_TOOL_6_To_BSM: 8 RadioLow

BO_ 2486881270 USDT_Req_From_TEST_TOOL_6_To_B01: 8 RadioLow

BO_ 2493172726 USDT_Req_From_TEST_TOOL_6_To_B02: 8 RadioLow

BO_ 2429288182 USDT_Req_From_TEST_TOOL_6_To_CAN: 7 RadioLow

BO_ 2417753846 USDT_Req_From_TEST_TOOL_6_To_C01: 7 RadioLow

BO_ 2418802422 USDT_Req_From_TEST_TOOL_6_To_C02: 7 RadioLow

BO_ 2419850998 USDT_Req_From_TEST_TOOL_6_To_C03: 7 RadioLow

BO_ 2420899574 USDT_Req_From_TEST_TOOL_6_To_C04: 7 RadioLow

BO_ 2431385334 USDT_Req_From_TEST_TOOL_6_To_C05: 7 RadioLow

BO_ 2425093878 USDT_Req_From_TEST_TOOL_6_To_C06: 7 RadioLow

BO_ 2426142454 USDT_Req_From_TEST_TOOL_6_To_C07: 7 RadioLow

BO_ 2497332726 USDT_Req_From_TEST_TOOL_6_To_CGM: 8 RadioLow

BO_ 2497321974 USDT_Req_From_TEST_TOOL_6_To_DCM: 8 RadioLow

BO_ 2497320182 USDT_Req_From_TEST_TOOL_6_To_DEF: 8 RadioLow

BO_ 2497342198 USDT_Req_From_TEST_TOOL_6_To_DMS: 8 RadioLow

BO_ 2497325302 USDT_Req_From_TEST_TOOL_6_To_EBC: 8 RadioLow

BO_ 2486839542 USDT_Req_From_TEST_TOOL_6_To_E01: 8 RadioLow

BO_ 2497319414 USDT_Req_From_TEST_TOOL_6_To_ECM: 8 RadioLow

BO_ 2486833654 USDT_Req_From_TEST_TOOL_6_To_E02: 8 RadioLow

BO_ 2497320950 USDT_Req_From_TEST_TOOL_6_To_ECP: 8 RadioLow

BO_ 2493126646 USDT_Req_From_TEST_TOOL_6_To_E03: 8 RadioLow

BO_ 2497322486 USDT_Req_From_TEST_TOOL_6_To_E04: 8 RadioLow

BO_ 2493128182 USDT_Req_From_TEST_TOOL_6_To_E05: 8 RadioLow

BO_ 2497322742 USDT_Req_From_TEST_TOOL_6_To_E06: 8 RadioLow

BO_ 2493128438 USDT_Req_From_TEST_TOOL_6_To_E07: 8 RadioLow

BO_ 2486835190 USDT_Req_From_TEST_TOOL_6_To_E08: 8 RadioLow

BO_ 2497331702 USDT_Req_From_TEST_TOOL_6_To_ELM: 8 RadioLow

BO_ 2486856950 USDT_Req_From_TEST_TOOL_6_To_EOC: 8 RadioLow

BO_ 2497342710 USDT_Req_From_TEST_TOOL_6_To_E09: 8 RadioLow

BO_ 2497371126 USDT_Req_From_TEST_TOOL_6_To_E10: 8 RadioLow

BO_ 2485806326 USDT_Req_From_TEST_TOOL_6_To_E11: 8 RadioLow

BO_ 2486854902 USDT_Req_From_TEST_TOOL_6_To_E12: 8 RadioLow

BO_ 2497340662 USDT_Req_From_TEST_TOOL_6_To_E13: 8 RadioLow

BO_ 2497327350 USDT_Req_From_TEST_TOOL_6_To_EPS: 8 RadioLow

BO_ 2497328374 USDT_Req_From_TEST_TOOL_6_To_E14: 8 RadioLow

BO_ 2497328630 USDT_Req_From_TEST_TOOL_6_To_E15: 8 RadioLow

BO_ 2497363446 USDT_Req_From_TEST_TOOL_6_To_FCM: 8 RadioLow

BO_ 2497363190 USDT_Req_From_TEST_TOOL_6_To_F01: 8 RadioLow

BO_ 2497373686 USDT_Req_From_TEST_TOOL_6_To_FOP: 8 RadioLow

BO_ 2486887926 USDT_Req_From_TEST_TOOL_6_To_F02: 8 RadioLow

BO_ 2497339638 USDT_Req_From_TEST_TOOL_6_To_FPI: 8 RadioLow

BO_ 2497343222 USDT_Req_From_TEST_TOOL_6_To_HDL: 8 RadioLow

BO_ 2497340150 USDT_Req_From_TEST_TOOL_6_To_HUD: 8 RadioLow

BO_ 2497341686 USDT_Req_From_TEST_TOOL_6_To_HVA: 8 RadioLow

BO_ 2497354486 USDT_Req_From_TEST_TOOL_6_To_H01: 8 RadioLow

BO_ 2497319926 USDT_Req_From_TEST_TOOL_6_To_ICC: 8 RadioLow

BO_ 2497341174 USDT_Req_From_TEST_TOOL_6_To_ICS: 8 RadioLow

BO_ 2497373942 USDT_Req_From_TEST_TOOL_6_To_LIB: 8 RadioLow

BO_ 2497375478 USDT_Req_From_TEST_TOOL_6_To_L01: 8 RadioLow

BO_ 2497368822 USDT_Req_From_TEST_TOOL_6_To_LRR: 8 RadioLow

BO_ 2497351158 USDT_Req_From_TEST_TOOL_6_To_MFC: 8 RadioLow

BO_ 2497358838 USDT_Req_From_TEST_TOOL_6_To_MRC: 8 RadioLow

BO_ 2497359094 USDT_Req_From_TEST_TOOL_6_To_M01: 8 RadioLow

BO_ 2497338614 USDT_Req_From_TEST_TOOL_6_To_MSB: 8 RadioLow

BO_ 2497339126 USDT_Req_From_TEST_TOOL_6_To_M02: 8 RadioLow

BO_ 2497358070 USDT_Req_From_TEST_TOOL_6_To_MSM: 8 RadioLow

BO_ 2497358582 USDT_Req_From_TEST_TOOL_6_To_M03: 8 RadioLow

BO_ 2497357558 USDT_Req_From_TEST_TOOL_6_To_M04: 8 RadioLow

BO_ 2497357814 USDT_Req_From_TEST_TOOL_6_To_M05: 8 RadioLow

BO_ 2497360374 USDT_Req_From_TEST_TOOL_6_To_MTC: 8 RadioLow

BO_ 2497362166 USDT_Req_From_TEST_TOOL_6_To_M06: 8 RadioLow

BO_ 2497340918 USDT_Req_From_TEST_TOOL_6_To_NVM: 8 RadioLow

BO_ 2497361910 USDT_Req_From_TEST_TOOL_6_To_ODS: 8 RadioLow

BO_ 2497361654 USDT_Req_From_TEST_TOOL_6_To_O01: 8 RadioLow

BO_ 2497363958 USDT_Req_From_TEST_TOOL_6_To_PA_: 8 RadioLow

BO_ 2497319158 USDT_Req_From_TEST_TOOL_6_To_PCM: 8 RadioLow

BO_ 2486833398 USDT_Req_From_TEST_TOOL_6_To_P01: 8 RadioLow

BO_ 2497341942 USDT_Req_From_TEST_TOOL_6_To_PDR: 8 RadioLow

BO_ 2497360886 USDT_Req_From_TEST_TOOL_6_To_PFC: 8 RadioLow

BO_ 2497375734 USDT_Req_From_TEST_TOOL_6_To_PLC: 8 RadioLow

BO_ 2497357046 USDT_Req_From_TEST_TOOL_6_To_PTM: 8 RadioLow

BO_ 2497321718 USDT_Req_From_TEST_TOOL_6_To_RDC: 8 RadioLow

BO_ 2497349110 USDT_Req_From_TEST_TOOL_6_To_RSI: 8 RadioLow

BO_ 2497329398 USDT_Req_From_TEST_TOOL_6_To_SAD: 8 RadioLow

BO_ 2497356022 USDT_Req_From_TEST_TOOL_6_To_SAM: 8 RadioLow

BO_ 2497356534 USDT_Req_From_TEST_TOOL_6_To_S01: 8 RadioLow

BO_ 2497356278 USDT_Req_From_TEST_TOOL_6_To_S02: 8 RadioLow

BO_ 2497356790 USDT_Req_From_TEST_TOOL_6_To_S03: 8 RadioLow

BO_ 2494180342 USDT_Req_From_TEST_TOOL_6_To_SBM: 8 RadioLow

BO_ 2497326070 USDT_Req_From_TEST_TOOL_6_To_S04: 8 RadioLow

BO_ 2497362422 USDT_Req_From_TEST_TOOL_6_To_SBZ: 8 RadioLow

BO_ 2497362678 USDT_Req_From_TEST_TOOL_6_To_S05: 8 RadioLow

BO_ 2497364726 USDT_Req_From_TEST_TOOL_6_To_SCL: 8 RadioLow

BO_ 2497337590 USDT_Req_From_TEST_TOOL_6_To_SDM: 8 RadioLow

BO_ 2497332982 USDT_Req_From_TEST_TOOL_6_To_SIB: 8 RadioLow

BO_ 2497369078 USDT_Req_From_TEST_TOOL_6_To_SRR: 8 RadioLow

BO_ 2497370102 USDT_Req_From_TEST_TOOL_6_To_S06: 8 RadioLow

BO_ 2497369846 USDT_Req_From_TEST_TOOL_6_To_S07: 8 RadioLow

BO_ 2497370358 USDT_Req_From_TEST_TOOL_6_To_S08: 8 RadioLow

BO_ 2497370614 USDT_Req_From_TEST_TOOL_6_To_S09: 8 RadioLow

BO_ 2497370870 USDT_Req_From_TEST_TOOL_6_To_S10: 8 RadioLow

BO_ 2497321206 USDT_Req_From_TEST_TOOL_6_To_TCM: 8 RadioLow

BO_ 2497353718 USDT_Req_From_TEST_TOOL_6_To_TCP: 8 RadioLow

BO_ 2497345014 USDT_Req_From_TEST_TOOL_6_To_TIM: 8 RadioLow

BO_ 2497374966 USDT_Req_From_TEST_TOOL_6_To_UPM: 8 RadioLow

BO_ 2497335542 USDT_Req_From_TEST_TOOL_6_To_UVM: 8 RadioLow

BO_ 2497334518 USDT_Req_From_TEST_TOOL_6_To_VDM: 8 RadioLow

BO_ 2493140214 USDT_Req_From_TEST_TOOL_6_To_V01: 8 RadioLow

BO_ 2497367542 USDT_Req_From_TEST_TOOL_6_To_VEC: 8 RadioLow

BO_ 2493173238 USDT_Req_From_TEST_TOOL_6_To_V02: 8 RadioLow

BO_ 2497352950 USDT_Req_From_TEST_TOOL_6_To_VKM: 8 RadioLow

BO_ 2497329654 USDT_Req_From_TEST_TOOL_6_To_VLM: 8 RadioLow

BO_ 2497342966 USDT_Req_From_TEST_TOOL_6_To_VPM: 8 RadioLow

BO_ 2497364982 USDT_Req_From_TEST_TOOL_6_To_WCM: 8 RadioLow

BO_ 2497365238 USDT_Req_From_TEST_TOOL_6_To_W01: 8 RadioLow

BO_ 2497365494 USDT_Req_From_TEST_TOOL_6_To_W02: 8 RadioLow

BO_ 2497363702 USDT_Req_From_TEST_TOOL_6_To_W03: 8 RadioLow

BO_ 2497379337 USDT_Rsp_BootMode_From_ADIMa_CAN: 8 CGM

BO_ 2497379336 USDT_Rsp_BootMode_From_ADIMb_CAN: 8 CGM

BO_ 2497379442 USDT_Rsp_BootMode_From_AHL_AFL_C: 8 CGM

BO_ 2497379377 USDT_Rsp_BootMode_From_AHS_CAN_2: 8 CGM

BO_ 2497379386 USDT_Rsp_BootMode_From_ALC_CAN_3: 8 CGM

BO_ 2497379457 USDT_Rsp_BootMode_From_AMP_CAN_5: 8 AMP

BO_ 2497379417 USDT_Rsp_BootMode_From_AOS_CAN_1: 8 CGM

BO_ 2497379515 USDT_Rsp_BootMode_From_APA_CAN_2: 8 CGM

BO_ 2497379506 USDT_Rsp_BootMode_From_ARB_CAN_1: 8 CGM

BO_ 2497379378 USDT_Rsp_BootMode_From_ARS_CAN_2: 8 CGM

BO_ 2497379392 USDT_Rsp_BootMode_From_BCM_CAN_9: 8 CGM

BO_ 2497379531 USDT_Rsp_BootMode_From_BSM_CAN_2: 8 CGM

BO_ 2497379456 USDT_Rsp_BootMode_From_CSM_AV_CA: 8 CSM_AV

BO_ 2497379355 USDT_Rsp_BootMode_From_DCM_CAN_2: 8 CGM

BO_ 2497379348 USDT_Rsp_BootMode_From_DEFC_CAN_: 8 CGM

BO_ 2497379434 USDT_Rsp_BootMode_From_DMS_CAN_2: 8 CGM

BO_ 2497379368 USDT_Rsp_BootMode_From_EBCM_CAN_: 8 CGM

BO_ 2497379345 USDT_Rsp_BootMode_From_ECM_CAN_2: 8 CGM

BO_ 2497379351 USDT_Rsp_BootMode_From_ECP_E_CAN: 8 CGM

BO_ 2497379357 USDT_Rsp_BootMode_From_ECP_H2_CA: 8 CGM

BO_ 2497379358 USDT_Rsp_BootMode_From_ECP_H3_CA: 8 CGM

BO_ 2497379393 USDT_Rsp_BootMode_From_ELM_CAN_9: 8 CGM

BO_ 2497379436 USDT_Rsp_BootMode_From_EOCM_CAN_: 8 CGM

BO_ 2497379547 USDT_Rsp_BootMode_From_EOCM_HCP2: 8 CGM

BO_ 2497379428 USDT_Rsp_BootMode_From_EOCM_HC_S: 8 CGM

BO_ 2497379376 USDT_Rsp_BootMode_From_EPSRAb_CA: 8 CGM

BO_ 2497379380 USDT_Rsp_BootMode_From_EPS_1_CAN: 8 CGM

BO_ 2497379381 USDT_Rsp_BootMode_From_EPSb_CAN_: 8 CGM

BO_ 2497379517 USDT_Rsp_BootMode_From_FCM_CAN_2: 8 CGM

BO_ 2497379516 USDT_Rsp_BootMode_From_FCM_LC_CA: 8 CGM

BO_ 2497379557 USDT_Rsp_BootMode_From_FOPM_CAN_: 8 CGM

BO_ 2497379424 USDT_Rsp_BootMode_From_FPI_CAN_5: 8 FPI

BO_ 2497379438 USDT_Rsp_BootMode_From_HDLM_CAN_: 8 CGM

BO_ 2497379426 USDT_Rsp_BootMode_From_HUD_CAN_C: 8 CGM

BO_ 2497379432 USDT_Rsp_BootMode_From_HVAC_FP_F: 8 HVAC_FP_F

BO_ 2497379482 USDT_Rsp_BootMode_From_HVAC_FP_R: 8 HVAC_FP_R

BO_ 2497379347 USDT_Rsp_BootMode_From_ICCM_CAN_: 8 CGM

BO_ 2497379430 USDT_Rsp_BootMode_From_ICS_Info_: 8 ICS_Info

BO_ 2497379558 USDT_Rsp_BootMode_From_LIB1_CAN_: 8 CGM

BO_ 2497379564 USDT_Rsp_BootMode_From_LIB_48V_C: 8 CGM

BO_ 2497379538 USDT_Rsp_BootMode_From_LRR_CAN_8: 8 CGM

BO_ 2497379469 USDT_Rsp_BootMode_From_MFC_CAN_5: 8 MFC

BO_ 2497379499 USDT_Rsp_BootMode_From_MRCM_L_CA: 8 CGM

BO_ 2497379500 USDT_Rsp_BootMode_From_MRCM_R_CA: 8 CGM

BO_ 2497379420 USDT_Rsp_BootMode_From_MSB1_CAN_: 8 CGM

BO_ 2497379422 USDT_Rsp_BootMode_From_MSB2_CAN_: 8 CGM

BO_ 2497379496 USDT_Rsp_BootMode_From_MSM_D_CAN: 8 CGM

BO_ 2497379498 USDT_Rsp_BootMode_From_MSM_LR_CA: 8 CGM

BO_ 2497379494 USDT_Rsp_BootMode_From_MSM_P_CAN: 8 CGM

BO_ 2497379495 USDT_Rsp_BootMode_From_MSM_RR_CA: 8 CGM

BO_ 2497379505 USDT_Rsp_BootMode_From_MTCM_L_CA: 8 CGM

BO_ 2497379512 USDT_Rsp_BootMode_From_MTCM_R_CA: 8 CGM

BO_ 2497379429 USDT_Rsp_BootMode_From_NVM_CAN_2: 8 CGM

BO_ 2497379511 USDT_Rsp_BootMode_From_ODS2_CAN_: 8 CGM

BO_ 2497379510 USDT_Rsp_BootMode_From_ODS_CAN_9: 8 CGM

BO_ 2497379519 USDT_Rsp_BootMode_From_PA_CAN_1_: 8 CGM

BO_ 2497379344 USDT_Rsp_BootMode_From_PCM_CAN_2: 8 CGM

BO_ 2497379433 USDT_Rsp_BootMode_From_PDR_CAN_5: 8 PDR

BO_ 2497379507 USDT_Rsp_BootMode_From_PFCM_CAN_: 8 CGM

BO_ 2497379565 USDT_Rsp_BootMode_From_PLCM_CAN_: 8 PLCM

BO_ 2497379492 USDT_Rsp_BootMode_From_PTM_CAN_4: 8 CGM

BO_ 2497379354 USDT_Rsp_BootMode_From_RDCM_CAN_: 8 CGM

BO_ 2497379461 USDT_Rsp_BootMode_From_RSI_CAN_5: 8 RSI

BO_ 2497379384 USDT_Rsp_BootMode_From_SADS_CAN_: 8 CGM

BO_ 2497379488 USDT_Rsp_BootMode_From_SAM_LF_CA: 8 CGM

BO_ 2497379490 USDT_Rsp_BootMode_From_SAM_LR_CA: 8 CGM

BO_ 2497379489 USDT_Rsp_BootMode_From_SAM_RF_CA: 8 CGM

BO_ 2497379491 USDT_Rsp_BootMode_From_SAM_RR_CA: 8 CGM

BO_ 2497379371 USDT_Rsp_BootMode_From_SBM_CAN_3: 8 CGM

BO_ 2497379513 USDT_Rsp_BootMode_From_SBZA_L_CA: 8 CGM

BO_ 2497379514 USDT_Rsp_BootMode_From_SBZA_R_CA: 8 CGM

BO_ 2497379522 USDT_Rsp_BootMode_From_SCL_CAN_1: 8 CGM

BO_ 2497379416 USDT_Rsp_BootMode_From_SDM_CAN_9: 8 CGM

BO_ 2497379398 USDT_Rsp_BootMode_From_SIB_CAN_1: 8 CGM

BO_ 2497379539 USDT_Rsp_BootMode_From_SRR_LF_CA: 8 CGM

BO_ 2497379543 USDT_Rsp_BootMode_From_SRR_LR_CR: 8 CGM

BO_ 2497379542 USDT_Rsp_BootMode_From_SRR_RF_CA: 8 CGM

BO_ 2497379544 USDT_Rsp_BootMode_From_SRR_RR_CA: 8 CGM

BO_ 2497379545 USDT_Rsp_BootMode_From_SRR_SLR_C: 8 CGM

BO_ 2497379546 USDT_Rsp_BootMode_From_SRR_SRR_C: 8 CGM

BO_ 2497379352 USDT_Rsp_BootMode_From_TCM_CAN_2: 8 CGM

BO_ 2497379479 USDT_Rsp_BootMode_From_TCP_CAN_5: 8 TCP

BO_ 2497379445 USDT_Rsp_BootMode_From_TIM_CAN_4: 8 CGM

BO_ 2497379562 USDT_Rsp_BootMode_From_UPM_CAN_8: 8 CGM

BO_ 2497379408 USDT_Rsp_BootMode_From_UVM_CAN_1: 8 CGM

BO_ 2497379404 USDT_Rsp_BootMode_From_VDM_CAN_2: 8 CGM

BO_ 2497379533 USDT_Rsp_BootMode_From_VECM_CAN_: 8 CGM

BO_ 2497379476 USDT_Rsp_BootMode_From_VKM_CAN_5: 8 VKM

BO_ 2497379385 USDT_Rsp_BootMode_From_VLM_CAN_3: 8 CGM

BO_ 2497379437 USDT_Rsp_BootMode_From_VPM_CAN_1: 8 CGM

BO_ 2497379523 USDT_Rsp_BootMode_From_WCM2_CAN_: 8 WCM2

BO_ 2497379524 USDT_Rsp_BootMode_From_WCM3_CAN_: 8 WCM3

BO_ 2497379525 USDT_Rsp_BootMode_From_WCM4_CAN_: 8 WCM4

BO_ 2497379518 USDT_Rsp_BootMode_From_WCM_CAN_5: 8 WCM

BO_ 2485842796 USDT_Rsp_From_ACP2_MCU_CAN_2_con: 8 CGM

BO_ 2485843564 USDT_Rsp_From_ACP2_MCU_CAN_2_c01: 8 CGM

BO_ 2492134252 USDT_Rsp_From_ACP2_MCU_CAN_8_con: 8 CGM

BO_ 2492135020 USDT_Rsp_From_ACP2_MCU_CAN_8_c01: 8 CGM

BO_ 2494231305 USDT_Rsp_From_ADIMa_CAN_10_conne: 8 CGM

BO_ 2494232073 USDT_Rsp_From_ADIMa_CAN_10_con01: 8 CGM

BO_ 2485842697 USDT_Rsp_From_ADIMa_CAN_2_connec: 8 CGM

BO_ 2485843465 USDT_Rsp_From_ADIMa_CAN_2_conn01: 8 CGM

BO_ 2486891273 USDT_Rsp_From_ADIMa_CAN_3_connec: 8 CGM

BO_ 2486892041 USDT_Rsp_From_ADIMa_CAN_3_conn01: 8 CGM

BO_ 2493182729 USDT_Rsp_From_ADIMa_CAN_9_connec: 8 CGM

BO_ 2493183497 USDT_Rsp_From_ADIMa_CAN_9_conn01: 8 CGM

BO_ 2494231304 USDT_Rsp_From_ADIMb_CAN_10_conne: 8 CGM

BO_ 2494232072 USDT_Rsp_From_ADIMb_CAN_10_con01: 8 CGM

BO_ 2485842696 USDT_Rsp_From_ADIMb_CAN_2_connec: 8 CGM

BO_ 2485843464 USDT_Rsp_From_ADIMb_CAN_2_conn01: 8 CGM

BO_ 2486891272 USDT_Rsp_From_ADIMb_CAN_3_connec: 8 CGM

BO_ 2486892040 USDT_Rsp_From_ADIMb_CAN_3_conn01: 8 CGM

BO_ 2493182728 USDT_Rsp_From_ADIMb_CAN_9_connec: 8 CGM

BO_ 2493183496 USDT_Rsp_From_ADIMb_CAN_9_conn01: 8 CGM

BO_ 2485842802 USDT_Rsp_From_AHL_AFL_CAN_2_conn: 8 CGM

BO_ 2485843570 USDT_Rsp_From_AHL_AFL_CAN_2_co01: 8 CGM

BO_ 2485842737 USDT_Rsp_From_AHS_CAN_2_connecto: 8 CGM

BO_ 2485843505 USDT_Rsp_From_AHS_CAN_2_connec01: 8 CGM

BO_ 2486891322 USDT_Rsp_From_ALC_CAN_3_connecto: 8 CGM

BO_ 2486892090 USDT_Rsp_From_ALC_CAN_3_connec01: 8 CGM

BO_ 2497376641 USDT_Rsp_From_AMP_CAN_5_connecto: 8 AMP

BO_ 2497376897 USDT_Rsp_From_AMP_CAN_5_connec01: 8 AMP

BO_ 2497377153 USDT_Rsp_From_AMP_CAN_5_connec02: 8 AMP

BO_ 2497377409 USDT_Rsp_From_AMP_CAN_5_connec03: 8 AMP

BO_ 2497377665 USDT_Rsp_From_AMP_CAN_5_connec04: 8 AMP

BO_ 2497377921 USDT_Rsp_From_AMP_CAN_5_connec05: 8 AMP

BO_ 2484794201 USDT_Rsp_From_AOS_CAN_1_connecto: 8 CGM

BO_ 2484794969 USDT_Rsp_From_AOS_CAN_1_connec01: 8 CGM

BO_ 2484794299 USDT_Rsp_From_APA_CAN_1_connecto: 8 CGM

BO_ 2484795067 USDT_Rsp_From_APA_CAN_1_connec01: 8 CGM

BO_ 2485842875 USDT_Rsp_From_APA_CAN_2_connecto: 8 CGM

BO_ 2485843643 USDT_Rsp_From_APA_CAN_2_connec01: 8 CGM

BO_ 2484794290 USDT_Rsp_From_ARB_CAN_1_connecto: 8 CGM

BO_ 2484795058 USDT_Rsp_From_ARB_CAN_1_connec01: 8 CGM

BO_ 2485842738 USDT_Rsp_From_ARS_CAN_2_connecto: 8 CGM

BO_ 2485843506 USDT_Rsp_From_ARS_CAN_2_connec01: 8 CGM

BO_ 2493182784 USDT_Rsp_From_BCM_CAN_9_connecto: 8 CGM

BO_ 2493183552 USDT_Rsp_From_BCM_CAN_9_connec01: 8 CGM

BO_ 2485842891 USDT_Rsp_From_BSM_CAN_2_connecto: 8 CGM

BO_ 2485843659 USDT_Rsp_From_BSM_CAN_2_connec01: 8 CGM

BO_ 2486891467 USDT_Rsp_From_BSM_CAN_3_connecto: 8 CGM

BO_ 2486892235 USDT_Rsp_From_BSM_CAN_3_connec01: 8 CGM

BO_ 2493182923 USDT_Rsp_From_BSM_HEV_CAN_9_conn: 8 CGM

BO_ 2493183691 USDT_Rsp_From_BSM_HEV_CAN_9_co01: 8 CGM

BO_ 2497377093 USDT_Rsp_From_CGM_CAN_5_connecto: 8 CGM

BO_ 2497377861 USDT_Rsp_From_CGM_CAN_5_connec01: 8 CGM

BO_ 2497376640 USDT_Rsp_From_CSM_AV_CAN_5_conne: 8 CSM_AV

BO_ 2497377152 USDT_Rsp_From_CSM_AV_CAN_5_con01: 8 CSM_AV

BO_ 2497377408 USDT_Rsp_From_CSM_AV_CAN_5_con02: 8 CSM_AV

BO_ 2497377664 USDT_Rsp_From_CSM_AV_CAN_5_con03: 8 CSM_AV

BO_ 2565861760 USDT_Rsp_From_CSM_AV_XCP_CAN_5_c: 8 CSM_AV

BO_ 2497376896 USDT_Rsp_From_CSM_CAN_5_connecto: 8 CSM

BO_ 2485842715 USDT_Rsp_From_DCM_CAN_2_connecto: 8 CGM

BO_ 2485843483 USDT_Rsp_From_DCM_CAN_2_connec01: 8 CGM

BO_ 2484794132 USDT_Rsp_From_DEFC_CAN_1_connect: 8 CGM

BO_ 2484794900 USDT_Rsp_From_DEFC_CAN_1_conne01: 8 CGM

BO_ 2485842794 USDT_Rsp_From_DMS_CAN_2_connecto: 8 CGM

BO_ 2485843562 USDT_Rsp_From_DMS_CAN_2_connec01: 8 CGM

BO_ 2485842728 USDT_Rsp_From_EBCM_CAN_2_connect: 8 CGM

BO_ 2485843496 USDT_Rsp_From_EBCM_CAN_2_conne01: 8 CGM

BO_ 2486891304 USDT_Rsp_From_EBCM_CAN_3_connect: 8 CGM

BO_ 2486892072 USDT_Rsp_From_EBCM_CAN_3_conne01: 8 CGM

BO_ 2485842705 USDT_Rsp_From_ECM_CAN_2_connecto: 8 CGM

BO_ 2485843473 USDT_Rsp_From_ECM_CAN_2_connec01: 8 CGM

BO_ 2486891281 USDT_Rsp_From_ECM_CAN_3_connecto: 8 CGM

BO_ 2486892049 USDT_Rsp_From_ECM_CAN_3_connec01: 8 CGM

BO_ 2485842711 USDT_Rsp_From_ECP_E_CAN_2_connec: 8 CGM

BO_ 2485843479 USDT_Rsp_From_ECP_E_CAN_2_conn01: 8 CGM

BO_ 2493182743 USDT_Rsp_From_ECP_E_CAN_9_connec: 8 CGM

BO_ 2493183511 USDT_Rsp_From_ECP_E_CAN_9_conn01: 8 CGM

BO_ 2485842717 USDT_Rsp_From_ECP_H2_CAN_2_conne: 8 CGM

BO_ 2485843485 USDT_Rsp_From_ECP_H2_CAN_2_con01: 8 CGM

BO_ 2493182749 USDT_Rsp_From_ECP_H2_CAN_9_conne: 8 CGM

BO_ 2493183517 USDT_Rsp_From_ECP_H2_CAN_9_con01: 8 CGM

BO_ 2485842718 USDT_Rsp_From_ECP_H3_CAN_2_conne: 8 CGM

BO_ 2485843486 USDT_Rsp_From_ECP_H3_CAN_2_con01: 8 CGM

BO_ 2493182750 USDT_Rsp_From_ECP_H3_CAN_9_conne: 8 CGM

BO_ 2493183518 USDT_Rsp_From_ECP_H3_CAN_9_con01: 8 CGM

BO_ 2486891287 USDT_Rsp_From_ECP_X1_CAN_3_conne: 8 CGM

BO_ 2486892055 USDT_Rsp_From_ECP_X1_CAN_3_con01: 8 CGM

BO_ 2493182785 USDT_Rsp_From_ELM_CAN_9_connecto: 8 CGM

BO_ 2493183553 USDT_Rsp_From_ELM_CAN_9_connec01: 8 CGM

BO_ 2486891372 USDT_Rsp_From_EOCM_CAN_3_connect: 8 CGM

BO_ 2486892140 USDT_Rsp_From_EOCM_CAN_3_conne01: 8 CGM

BO_ 2492134363 USDT_Rsp_From_EOCM_HCP2_CAN_8_co: 8 CGM

BO_ 2492135131 USDT_Rsp_From_EOCM_HCP2_CAN_8_01: 8 CGM

BO_ 2485842788 USDT_Rsp_From_EOCM_HC_Superset_C: 8 CGM

BO_ 2485843556 USDT_Rsp_From_EOCM_HC_Superset01: 8 CGM

BO_ 2486891364 USDT_Rsp_From_EOCM_HC_Superset02: 8 CGM

BO_ 2486892132 USDT_Rsp_From_EOCM_HC_Superset03: 8 CGM

BO_ 2492134244 USDT_Rsp_From_EOCM_HC_Superset04: 8 CGM

BO_ 2492135012 USDT_Rsp_From_EOCM_HC_Superset05: 8 CGM

BO_ 2494231344 USDT_Rsp_From_EPSRAb_CAN_10_conn: 8 CGM

BO_ 2494232112 USDT_Rsp_From_EPSRAb_CAN_10_co01: 8 CGM

BO_ 2484794164 USDT_Rsp_From_EPS_1_CAN_1_connec: 8 CGM

BO_ 2484794932 USDT_Rsp_From_EPS_1_CAN_1_conn01: 8 CGM

BO_ 2485842741 USDT_Rsp_From_EPSb_CAN_2_connect: 8 CGM

BO_ 2485843509 USDT_Rsp_From_EPSb_CAN_2_conne01: 8 CGM

BO_ 2485842877 USDT_Rsp_From_FCM_CAN_2_connecto: 8 CGM

BO_ 2485843645 USDT_Rsp_From_FCM_CAN_2_connec01: 8 CGM

BO_ 2492134332 USDT_Rsp_From_FCM_LC_CAN_8_conne: 8 CGM

BO_ 2492135100 USDT_Rsp_From_FCM_LC_CAN_8_con01: 8 CGM

BO_ 2485842917 USDT_Rsp_From_FOPM_CAN_2_connect: 8 CGM

BO_ 2485843685 USDT_Rsp_From_FOPM_CAN_2_conne01: 8 CGM

BO_ 2486891493 USDT_Rsp_From_FOPM_CAN_3_connect: 8 CGM

BO_ 2486892261 USDT_Rsp_From_FOPM_CAN_3_conne01: 8 CGM

BO_ 2497376608 USDT_Rsp_From_FPI_CAN_5_connecto: 8 FPI

BO_ 2497376864 USDT_Rsp_From_FPI_CAN_5_connec01: 8 FPI

BO_ 2497377120 USDT_Rsp_From_FPI_CAN_5_connec02: 8 FPI

BO_ 2497377376 USDT_Rsp_From_FPI_CAN_5_connec03: 8 FPI

BO_ 2497377632 USDT_Rsp_From_FPI_CAN_5_connec04: 8 FPI

BO_ 2497377888 USDT_Rsp_From_FPI_CAN_5_connec05: 8 FPI

BO_ 2492134254 USDT_Rsp_From_HDLM_CAN_8_connect: 8 CGM

BO_ 2492135022 USDT_Rsp_From_HDLM_CAN_8_conne01: 8 CGM

BO_ 2485842786 USDT_Rsp_From_HUD_CAN_CAN_2_conn: 8 CGM

BO_ 2485843554 USDT_Rsp_From_HUD_CAN_CAN_2_co01: 8 CGM

BO_ 2497376616 USDT_Rsp_From_HVAC_FP_F_CAN_5_co: 8 HVAC_FP_F

BO_ 2497376872 USDT_Rsp_From_HVAC_FP_F_CAN_5_01: 8 HVAC_FP_F

BO_ 2497377128 USDT_Rsp_From_HVAC_FP_F_CAN_5_02: 8 HVAC_FP_F

BO_ 2497377384 USDT_Rsp_From_HVAC_FP_F_CAN_5_03: 8 HVAC_FP_F

BO_ 2497377640 USDT_Rsp_From_HVAC_FP_F_CAN_5_04: 8 HVAC_FP_F

BO_ 2497377896 USDT_Rsp_From_HVAC_FP_F_CAN_5_05: 8 HVAC_FP_F

BO_ 2497376666 USDT_Rsp_From_HVAC_FP_R_CAN_5_co: 8 HVAC_FP_R

BO_ 2497376922 USDT_Rsp_From_HVAC_FP_R_CAN_5_01: 8 HVAC_FP_R

BO_ 2497377178 USDT_Rsp_From_HVAC_FP_R_CAN_5_02: 8 HVAC_FP_R

BO_ 2497377434 USDT_Rsp_From_HVAC_FP_R_CAN_5_03: 8 HVAC_FP_R

BO_ 2497377690 USDT_Rsp_From_HVAC_FP_R_CAN_5_04: 8 HVAC_FP_R

BO_ 2497377946 USDT_Rsp_From_HVAC_FP_R_CAN_5_05: 8 HVAC_FP_R

BO_ 2486891283 USDT_Rsp_From_ICCM_CAN_3_connect: 8 CGM

BO_ 2486892051 USDT_Rsp_From_ICCM_CAN_3_conne01: 8 CGM

BO_ 2497376614 USDT_Rsp_From_ICS_Info_CAN_5_con: 8 ICS_Info

BO_ 2497376870 USDT_Rsp_From_ICS_Info_CAN_5_c01: 8 ICS_Info

BO_ 2497377126 USDT_Rsp_From_ICS_Info_CAN_5_c02: 8 ICS_Info

BO_ 2497377382 USDT_Rsp_From_ICS_Info_CAN_5_c03: 8 ICS_Info

BO_ 2497377638 USDT_Rsp_From_ICS_Info_CAN_5_c04: 8 ICS_Info

BO_ 2497377894 USDT_Rsp_From_ICS_Info_CAN_5_c05: 8 ICS_Info

BO_ 2485842918 USDT_Rsp_From_LIB1_CAN_2_connect: 8 CGM

BO_ 2485843686 USDT_Rsp_From_LIB1_CAN_2_conne01: 8 CGM

BO_ 2486891500 USDT_Rsp_From_LIB_48V_CAN_3_conn: 8 CGM

BO_ 2486892268 USDT_Rsp_From_LIB_48V_CAN_3_co01: 8 CGM

BO_ 2492134354 USDT_Rsp_From_LRR_CAN_8_connecto: 8 CGM

BO_ 2492135122 USDT_Rsp_From_LRR_CAN_8_connec01: 8 CGM

BO_ 2497376653 USDT_Rsp_From_MFC_CAN_5_connecto: 8 MFC

BO_ 2497376909 USDT_Rsp_From_MFC_CAN_5_connec01: 8 MFC

BO_ 2497377165 USDT_Rsp_From_MFC_CAN_5_connec02: 8 MFC

BO_ 2497377421 USDT_Rsp_From_MFC_CAN_5_connec03: 8 MFC

BO_ 2497377677 USDT_Rsp_From_MFC_CAN_5_connec04: 8 MFC

BO_ 2497377933 USDT_Rsp_From_MFC_CAN_5_connec05: 8 MFC

BO_ 2487940011 USDT_Rsp_From_MRCM_L_CAN_4_conne: 8 CGM

BO_ 2487940779 USDT_Rsp_From_MRCM_L_CAN_4_con01: 8 CGM

BO_ 2487940012 USDT_Rsp_From_MRCM_R_CAN_4_conne: 8 CGM

BO_ 2487940780 USDT_Rsp_From_MRCM_R_CAN_4_con01: 8 CGM

BO_ 2484794204 USDT_Rsp_From_MSB1_CAN_1_connect: 8 CGM

BO_ 2484794972 USDT_Rsp_From_MSB1_CAN_1_conne01: 8 CGM

BO_ 2484794206 USDT_Rsp_From_MSB2_CAN_1_connect: 8 CGM

BO_ 2484794974 USDT_Rsp_From_MSB2_CAN_1_conne01: 8 CGM

BO_ 2487940008 USDT_Rsp_From_MSM_D_CAN_4_connec: 8 CGM

BO_ 2487940776 USDT_Rsp_From_MSM_D_CAN_4_conn01: 8 CGM

BO_ 2487940010 USDT_Rsp_From_MSM_LR_CAN_4_conne: 8 CGM

BO_ 2487940778 USDT_Rsp_From_MSM_LR_CAN_4_con01: 8 CGM

BO_ 2487940006 USDT_Rsp_From_MSM_P_CAN_4_connec: 8 CGM

BO_ 2487940774 USDT_Rsp_From_MSM_P_CAN_4_conn01: 8 CGM

BO_ 2487940007 USDT_Rsp_From_MSM_RR_CAN_4_conne: 8 CGM

BO_ 2487940775 USDT_Rsp_From_MSM_RR_CAN_4_con01: 8 CGM

BO_ 2487940017 USDT_Rsp_From_MTCM_L_CAN_4_conne: 8 CGM

BO_ 2487940785 USDT_Rsp_From_MTCM_L_CAN_4_con01: 8 CGM

BO_ 2487940024 USDT_Rsp_From_MTCM_R_CAN_4_conne: 8 CGM

BO_ 2487940792 USDT_Rsp_From_MTCM_R_CAN_4_con01: 8 CGM

BO_ 2485842789 USDT_Rsp_From_NVM_CAN_2_connecto: 8 CGM

BO_ 2485843557 USDT_Rsp_From_NVM_CAN_2_connec01: 8 CGM

BO_ 2493182903 USDT_Rsp_From_ODS2_CAN_9_connect: 8 CGM

BO_ 2493183671 USDT_Rsp_From_ODS2_CAN_9_conne01: 8 CGM

BO_ 2493182902 USDT_Rsp_From_ODS_CAN_9_connecto: 8 CGM

BO_ 2493183670 USDT_Rsp_From_ODS_CAN_9_connec01: 8 CGM

BO_ 2484794303 USDT_Rsp_From_PA_CAN_1_connector: 8 CGM

BO_ 2484795071 USDT_Rsp_From_PA_CAN_1_connect01: 8 CGM

BO_ 2485842704 USDT_Rsp_From_PCM_CAN_2_connecto: 8 CGM

BO_ 2485843472 USDT_Rsp_From_PCM_CAN_2_connec01: 8 CGM

BO_ 2486891280 USDT_Rsp_From_PCM_CAN_3_connecto: 8 CGM

BO_ 2486892048 USDT_Rsp_From_PCM_CAN_3_connec01: 8 CGM

BO_ 2497376617 USDT_Rsp_From_PDR_CAN_5_connecto: 8 PDR

BO_ 2497376873 USDT_Rsp_From_PDR_CAN_5_connec01: 8 PDR

BO_ 2497377129 USDT_Rsp_From_PDR_CAN_5_connec02: 8 PDR

BO_ 2497377385 USDT_Rsp_From_PDR_CAN_5_connec03: 8 PDR

BO_ 2497377641 USDT_Rsp_From_PDR_CAN_5_connec04: 8 PDR

BO_ 2497377897 USDT_Rsp_From_PDR_CAN_5_connec05: 8 PDR

BO_ 2487940019 USDT_Rsp_From_PFCM_CAN_4_connect: 8 CGM

BO_ 2487940787 USDT_Rsp_From_PFCM_CAN_4_conne01: 8 CGM

BO_ 2497376749 USDT_Rsp_From_PLCM_CAN_5_connect: 8 PLCM

BO_ 2497377005 USDT_Rsp_From_PLCM_CAN_5_conne01: 8 PLCM

BO_ 2497377261 USDT_Rsp_From_PLCM_CAN_5_conne02: 8 PLCM

BO_ 2497377517 USDT_Rsp_From_PLCM_CAN_5_conne03: 8 PLCM

BO_ 2497377773 USDT_Rsp_From_PLCM_CAN_5_conne04: 8 PLCM

BO_ 2497378029 USDT_Rsp_From_PLCM_CAN_5_conne05: 8 PLCM

BO_ 2487940004 USDT_Rsp_From_PTM_CAN_4_connecto: 8 CGM

BO_ 2487940772 USDT_Rsp_From_PTM_CAN_4_connec01: 8 CGM

BO_ 2485842714 USDT_Rsp_From_RDCM_CAN_2_connect: 8 CGM

BO_ 2485843482 USDT_Rsp_From_RDCM_CAN_2_conne01: 8 CGM

BO_ 2497376645 USDT_Rsp_From_RSI_CAN_5_connecto: 8 RSI

BO_ 2497376901 USDT_Rsp_From_RSI_CAN_5_connec01: 8 RSI

BO_ 2497377157 USDT_Rsp_From_RSI_CAN_5_connec02: 8 RSI

BO_ 2497377413 USDT_Rsp_From_RSI_CAN_5_connec03: 8 RSI

BO_ 2497377669 USDT_Rsp_From_RSI_CAN_5_connec04: 8 RSI

BO_ 2497377925 USDT_Rsp_From_RSI_CAN_5_connec05: 8 RSI

BO_ 2486891320 USDT_Rsp_From_SADS_CAN_3_connect: 8 CGM

BO_ 2486892088 USDT_Rsp_From_SADS_CAN_3_conne01: 8 CGM

BO_ 2484794272 USDT_Rsp_From_SAM_LF_CAN_1_conne: 8 CGM

BO_ 2484795040 USDT_Rsp_From_SAM_LF_CAN_1_con01: 8 CGM

BO_ 2484794274 USDT_Rsp_From_SAM_LR_CAN_1_conne: 8 CGM

BO_ 2484795042 USDT_Rsp_From_SAM_LR_CAN_1_con01: 8 CGM

BO_ 2487940001 USDT_Rsp_From_SAM_RF_CAN_4_conne: 8 CGM

BO_ 2487940769 USDT_Rsp_From_SAM_RF_CAN_4_con01: 8 CGM

BO_ 2487940003 USDT_Rsp_From_SAM_RR_CAN_4_conne: 8 CGM

BO_ 2487940771 USDT_Rsp_From_SAM_RR_CAN_4_con01: 8 CGM

BO_ 2494231339 USDT_Rsp_From_SBM_CAN_10_connect: 8 CGM

BO_ 2494232107 USDT_Rsp_From_SBM_CAN_10_conne01: 8 CGM

BO_ 2486891307 USDT_Rsp_From_SBM_CAN_3_connecto: 8 CGM

BO_ 2486892075 USDT_Rsp_From_SBM_CAN_3_connec01: 8 CGM

BO_ 2487940025 USDT_Rsp_From_SBZA_L_CAN_4_conne: 8 CGM

BO_ 2487940793 USDT_Rsp_From_SBZA_L_CAN_4_con01: 8 CGM

BO_ 2487940026 USDT_Rsp_From_SBZA_R_CAN_4_conne: 8 CGM

BO_ 2487940794 USDT_Rsp_From_SBZA_R_CAN_4_con01: 8 CGM

BO_ 2484794306 USDT_Rsp_From_SCL_CAN_1_connecto: 8 CGM

BO_ 2484795074 USDT_Rsp_From_SCL_CAN_1_connec01: 8 CGM

BO_ 2493182808 USDT_Rsp_From_SDM_CAN_9_connecto: 8 CGM

BO_ 2493183576 USDT_Rsp_From_SDM_CAN_9_connec01: 8 CGM

BO_ 2484794182 USDT_Rsp_From_SIB_CAN_1_connecto: 8 CGM

BO_ 2484794950 USDT_Rsp_From_SIB_CAN_1_connec01: 8 CGM

BO_ 2492134355 USDT_Rsp_From_SRR_LF_CAN_8_conne: 8 CGM

BO_ 2492135123 USDT_Rsp_From_SRR_LF_CAN_8_con01: 8 CGM

BO_ 2492134359 USDT_Rsp_From_SRR_LR_CR_CAN_8_co: 8 CGM

BO_ 2492135127 USDT_Rsp_From_SRR_LR_CR_CAN_8_01: 8 CGM

BO_ 2492134358 USDT_Rsp_From_SRR_RF_CAN_8_conne: 8 CGM

BO_ 2492135126 USDT_Rsp_From_SRR_RF_CAN_8_con01: 8 CGM

BO_ 2492134360 USDT_Rsp_From_SRR_RR_CAN_8_conne: 8 CGM

BO_ 2492135128 USDT_Rsp_From_SRR_RR_CAN_8_con01: 8 CGM

BO_ 2492134361 USDT_Rsp_From_SRR_SLR_CAN_8_conn: 8 CGM

BO_ 2492135129 USDT_Rsp_From_SRR_SLR_CAN_8_co01: 8 CGM

BO_ 2492134362 USDT_Rsp_From_SRR_SRR_CAN_8_conn: 8 CGM

BO_ 2492135130 USDT_Rsp_From_SRR_SRR_CAN_8_co01: 8 CGM

BO_ 2485842712 USDT_Rsp_From_TCM_CAN_2_connecto: 8 CGM

BO_ 2485843480 USDT_Rsp_From_TCM_CAN_2_connec01: 8 CGM

BO_ 2497376663 USDT_Rsp_From_TCP_CAN_5_connecto: 8 TCP

BO_ 2497376919 USDT_Rsp_From_TCP_CAN_5_connec01: 8 TCP

BO_ 2497377431 USDT_Rsp_From_TCP_CAN_5_connec02: 8 TCP

BO_ 2497377687 USDT_Rsp_From_TCP_CAN_5_connec03: 8 TCP

BO_ 2497377943 USDT_Rsp_From_TCP_CAN_5_connec04: 8 TCP

BO_ 2487939957 USDT_Rsp_From_TIM_CAN_4_connecto: 8 CGM

BO_ 2487940725 USDT_Rsp_From_TIM_CAN_4_connec01: 8 CGM

BO_ 2492134378 USDT_Rsp_From_UPM_CAN_8_connecto: 8 CGM

BO_ 2492135146 USDT_Rsp_From_UPM_CAN_8_connec01: 8 CGM

BO_ 2484794192 USDT_Rsp_From_UVM_CAN_1_connecto: 8 CGM

BO_ 2484794960 USDT_Rsp_From_UVM_CAN_1_connec01: 8 CGM

BO_ 2485842764 USDT_Rsp_From_VDM_CAN_2_connecto: 8 CGM

BO_ 2485843532 USDT_Rsp_From_VDM_CAN_2_connec01: 8 CGM

BO_ 2493182796 USDT_Rsp_From_VDM_CAN_9_connecto: 8 CGM

BO_ 2493183564 USDT_Rsp_From_VDM_CAN_9_connec01: 8 CGM

BO_ 2485842893 USDT_Rsp_From_VECM_CAN_2_connect: 8 CGM

BO_ 2485843661 USDT_Rsp_From_VECM_CAN_2_conne01: 8 CGM

BO_ 2493182925 USDT_Rsp_From_VECM_CAN_9_connect: 8 CGM

BO_ 2493183693 USDT_Rsp_From_VECM_CAN_9_conne01: 8 CGM

BO_ 2497376660 USDT_Rsp_From_VKM_CAN_5_connecto: 8 VKM

BO_ 2497376916 USDT_Rsp_From_VKM_CAN_5_connec01: 8 VKM

BO_ 2497377172 USDT_Rsp_From_VKM_CAN_5_connec02: 8 VKM

BO_ 2497377428 USDT_Rsp_From_VKM_CAN_5_connec03: 8 VKM

BO_ 2497377684 USDT_Rsp_From_VKM_CAN_5_connec04: 8 VKM

BO_ 2497377940 USDT_Rsp_From_VKM_CAN_5_connec05: 8 VKM

BO_ 2486891321 USDT_Rsp_From_VLM_CAN_3_connecto: 8 CGM

BO_ 2486892089 USDT_Rsp_From_VLM_CAN_3_connec01: 8 CGM

BO_ 2484794221 USDT_Rsp_From_VPM_CAN_1_connecto: 8 CGM

BO_ 2484794989 USDT_Rsp_From_VPM_CAN_1_connec01: 8 CGM

BO_ 2497376707 USDT_Rsp_From_WCM2_CAN_5_connect: 8 WCM2

BO_ 2497376963 USDT_Rsp_From_WCM2_CAN_5_conne01: 8 WCM2

BO_ 2497377219 USDT_Rsp_From_WCM2_CAN_5_conne02: 8 WCM2

BO_ 2497377475 USDT_Rsp_From_WCM2_CAN_5_conne03: 8 WCM2

BO_ 2497377731 USDT_Rsp_From_WCM2_CAN_5_conne04: 8 WCM2

BO_ 2497377987 USDT_Rsp_From_WCM2_CAN_5_conne05: 8 WCM2

BO_ 2497376708 USDT_Rsp_From_WCM3_CAN_5_connect: 8 WCM3

BO_ 2497376964 USDT_Rsp_From_WCM3_CAN_5_conne01: 8 WCM3

BO_ 2497377220 USDT_Rsp_From_WCM3_CAN_5_conne02: 8 WCM3

BO_ 2497377476 USDT_Rsp_From_WCM3_CAN_5_conne03: 8 WCM3

BO_ 2497377732 USDT_Rsp_From_WCM3_CAN_5_conne04: 8 WCM3

BO_ 2497377988 USDT_Rsp_From_WCM3_CAN_5_conne05: 8 WCM3

BO_ 2497376709 USDT_Rsp_From_WCM4_CAN_5_connect: 8 WCM4

BO_ 2497376965 USDT_Rsp_From_WCM4_CAN_5_conne01: 8 WCM4

BO_ 2497377221 USDT_Rsp_From_WCM4_CAN_5_conne02: 8 WCM4

BO_ 2497377477 USDT_Rsp_From_WCM4_CAN_5_conne03: 8 WCM4

BO_ 2497377733 USDT_Rsp_From_WCM4_CAN_5_conne04: 8 WCM4

BO_ 2497377989 USDT_Rsp_From_WCM4_CAN_5_conne05: 8 WCM4

BO_ 2497376702 USDT_Rsp_From_WCM_CAN_5_connecto: 8 WCM

BO_ 2497376958 USDT_Rsp_From_WCM_CAN_5_connec01: 8 WCM

BO_ 2497377214 USDT_Rsp_From_WCM_CAN_5_connec02: 8 WCM

BO_ 2497377470 USDT_Rsp_From_WCM_CAN_5_connec03: 8 WCM

BO_ 2497377726 USDT_Rsp_From_WCM_CAN_5_connec04: 8 WCM

BO_ 2497377982 USDT_Rsp_From_WCM_CAN_5_connec05: 8 WCM

BO_ 2485973769 UUDT_Rsp_From_ADIMa_CAN_2_connec: 8 CGM

BO_ 2485974537 UUDT_Rsp_From_ADIMa_CAN_2_conn01: 8 CGM

BO_ 2485973768 UUDT_Rsp_From_ADIMb_CAN_2_connec: 8 CGM

BO_ 2485974536 UUDT_Rsp_From_ADIMb_CAN_2_conn01: 8 CGM

BO_ 2485973874 UUDT_Rsp_From_AHL_AFL_CAN_2_conn: 8 CGM

BO_ 2485974642 UUDT_Rsp_From_AHL_AFL_CAN_2_co01: 8 CGM

BO_ 2485973809 UUDT_Rsp_From_AHS_CAN_2_connecto: 8 CGM

BO_ 2485974577 UUDT_Rsp_From_AHS_CAN_2_connec01: 8 CGM

BO_ 2487022394 UUDT_Rsp_From_ALC_CAN_3_connecto: 8 CGM

BO_ 2487023162 UUDT_Rsp_From_ALC_CAN_3_connec01: 8 CGM

BO_ 2497507713 UUDT_Rsp_From_AMP_CAN_5_connecto: 8 AMP

BO_ 2497507969 UUDT_Rsp_From_AMP_CAN_5_connec01: 8 AMP

BO_ 2497508225 UUDT_Rsp_From_AMP_CAN_5_connec02: 8 AMP

BO_ 2497508481 UUDT_Rsp_From_AMP_CAN_5_connec03: 8 AMP

BO_ 2497508737 UUDT_Rsp_From_AMP_CAN_5_connec04: 8 AMP

BO_ 2497508993 UUDT_Rsp_From_AMP_CAN_5_connec05: 8 AMP

BO_ 2484925273 UUDT_Rsp_From_AOS_CAN_1_connecto: 8 CGM

BO_ 2484926041 UUDT_Rsp_From_AOS_CAN_1_connec01: 8 CGM

BO_ 2485973947 UUDT_Rsp_From_APA_CAN_2_connecto: 8 CGM

BO_ 2485974715 UUDT_Rsp_From_APA_CAN_2_connec01: 8 CGM

BO_ 2484925362 UUDT_Rsp_From_ARB_CAN_1_connecto: 8 CGM

BO_ 2484926130 UUDT_Rsp_From_ARB_CAN_1_connec01: 8 CGM

BO_ 2485973810 UUDT_Rsp_From_ARS_CAN_2_connecto: 8 CGM

BO_ 2485974578 UUDT_Rsp_From_ARS_CAN_2_connec01: 8 CGM

BO_ 2493313856 UUDT_Rsp_From_BCM_CAN_9_connecto: 8 CGM

BO_ 2493314624 UUDT_Rsp_From_BCM_CAN_9_connec01: 8 CGM

BO_ 2485973963 UUDT_Rsp_From_BSM_CAN_2_connecto: 8 CGM

BO_ 2485974731 UUDT_Rsp_From_BSM_CAN_2_connec01: 8 CGM

BO_ 2497508165 UUDT_Rsp_From_CGM_CAN_5_connecto: 8 CGM

BO_ 2497508933 UUDT_Rsp_From_CGM_CAN_5_connec01: 8 CGM

BO_ 2497507712 UUDT_Rsp_From_CSM_AV_CAN_5_conne: 8 CSM_AV

BO_ 2497508224 UUDT_Rsp_From_CSM_AV_CAN_5_con01: 8 CSM_AV

BO_ 2497508480 UUDT_Rsp_From_CSM_AV_CAN_5_con02: 8 CSM_AV

BO_ 2497508736 UUDT_Rsp_From_CSM_AV_CAN_5_con03: 8 CSM_AV

BO_ 2497507968 UUDT_Rsp_From_CSM_CAN_5_connecto: 8 CSM

BO_ 2485973787 UUDT_Rsp_From_DCM_CAN_2_connecto: 8 CGM

BO_ 2485974555 UUDT_Rsp_From_DCM_CAN_2_connec01: 8 CGM

BO_ 2484925204 UUDT_Rsp_From_DEFC_CAN_1_connect: 8 CGM

BO_ 2484925972 UUDT_Rsp_From_DEFC_CAN_1_conne01: 8 CGM

BO_ 2485973866 UUDT_Rsp_From_DMS_CAN_2_connecto: 8 CGM

BO_ 2485974634 UUDT_Rsp_From_DMS_CAN_2_connec01: 8 CGM

BO_ 2485973800 UUDT_Rsp_From_EBCM_CAN_2_connect: 8 CGM

BO_ 2485974568 UUDT_Rsp_From_EBCM_CAN_2_conne01: 8 CGM

BO_ 2485973777 UUDT_Rsp_From_ECM_CAN_2_connecto: 8 CGM

BO_ 2485974545 UUDT_Rsp_From_ECM_CAN_2_connec01: 8 CGM

BO_ 2485973783 UUDT_Rsp_From_ECP_E_CAN_2_connec: 8 CGM

BO_ 2485974551 UUDT_Rsp_From_ECP_E_CAN_2_conn01: 8 CGM

BO_ 2485973789 UUDT_Rsp_From_ECP_H2_CAN_2_conne: 8 CGM

BO_ 2485974557 UUDT_Rsp_From_ECP_H2_CAN_2_con01: 8 CGM

BO_ 2485973790 UUDT_Rsp_From_ECP_H3_CAN_2_conne: 8 CGM

BO_ 2485974558 UUDT_Rsp_From_ECP_H3_CAN_2_con01: 8 CGM

BO_ 2493313857 UUDT_Rsp_From_ELM_CAN_9_connecto: 8 CGM

BO_ 2493314625 UUDT_Rsp_From_ELM_CAN_9_connec01: 8 CGM

BO_ 2492265324 UUDT_Rsp_From_EOCM_CAN_8_connect: 8 CGM

BO_ 2492266092 UUDT_Rsp_From_EOCM_CAN_8_conne01: 8 CGM

BO_ 2492265435 UUDT_Rsp_From_EOCM_HCP2_CAN_8_co: 8 CGM

BO_ 2492266203 UUDT_Rsp_From_EOCM_HCP2_CAN_8_01: 8 CGM

BO_ 2492265316 UUDT_Rsp_From_EOCM_HC_Superset_C: 8 CGM

BO_ 2492266084 UUDT_Rsp_From_EOCM_HC_Superset01: 8 CGM

BO_ 2494362416 UUDT_Rsp_From_EPSRAb_CAN_10_conn: 8 CGM

BO_ 2494363184 UUDT_Rsp_From_EPSRAb_CAN_10_co01: 8 CGM

BO_ 2484925236 UUDT_Rsp_From_EPS_1_CAN_1_connec: 8 CGM

BO_ 2484926004 UUDT_Rsp_From_EPS_1_CAN_1_conn01: 8 CGM

BO_ 2485973813 UUDT_Rsp_From_EPSb_CAN_2_connect: 8 CGM

BO_ 2485974581 UUDT_Rsp_From_EPSb_CAN_2_conne01: 8 CGM

BO_ 2485973949 UUDT_Rsp_From_FCM_CAN_2_connecto: 8 CGM

BO_ 2485974717 UUDT_Rsp_From_FCM_CAN_2_connec01: 8 CGM

BO_ 2492265404 UUDT_Rsp_From_FCM_LC_CAN_8_conne: 8 CGM

BO_ 2492266172 UUDT_Rsp_From_FCM_LC_CAN_8_con01: 8 CGM

BO_ 2485973989 UUDT_Rsp_From_FOPM_CAN_2_connect: 8 CGM

BO_ 2485974757 UUDT_Rsp_From_FOPM_CAN_2_conne01: 8 CGM

BO_ 2497507680 UUDT_Rsp_From_FPI_CAN_5_connecto: 8 FPI

BO_ 2497507936 UUDT_Rsp_From_FPI_CAN_5_connec01: 8 FPI

BO_ 2497508192 UUDT_Rsp_From_FPI_CAN_5_connec02: 8 FPI

BO_ 2497508448 UUDT_Rsp_From_FPI_CAN_5_connec03: 8 FPI

BO_ 2497508704 UUDT_Rsp_From_FPI_CAN_5_connec04: 8 FPI

BO_ 2497508960 UUDT_Rsp_From_FPI_CAN_5_connec05: 8 FPI

BO_ 2492265326 UUDT_Rsp_From_HDLM_CAN_8_connect: 8 CGM

BO_ 2492266094 UUDT_Rsp_From_HDLM_CAN_8_conne01: 8 CGM

BO_ 2485973858 UUDT_Rsp_From_HUD_CAN_CAN_2_conn: 8 CGM

BO_ 2485974626 UUDT_Rsp_From_HUD_CAN_CAN_2_co01: 8 CGM

BO_ 2497507688 UUDT_Rsp_From_HVAC_FP_F_CAN_5_co: 8 HVAC_FP_F

BO_ 2497507944 UUDT_Rsp_From_HVAC_FP_F_CAN_5_01: 8 HVAC_FP_F

BO_ 2497508200 UUDT_Rsp_From_HVAC_FP_F_CAN_5_02: 8 HVAC_FP_F

BO_ 2497508456 UUDT_Rsp_From_HVAC_FP_F_CAN_5_03: 8 HVAC_FP_F

BO_ 2497508712 UUDT_Rsp_From_HVAC_FP_F_CAN_5_04: 8 HVAC_FP_F

BO_ 2497508968 UUDT_Rsp_From_HVAC_FP_F_CAN_5_05: 8 HVAC_FP_F

BO_ 2497507738 UUDT_Rsp_From_HVAC_FP_R_CAN_5_co: 8 HVAC_FP_R

BO_ 2497507994 UUDT_Rsp_From_HVAC_FP_R_CAN_5_01: 8 HVAC_FP_R

BO_ 2497508250 UUDT_Rsp_From_HVAC_FP_R_CAN_5_02: 8 HVAC_FP_R

BO_ 2497508506 UUDT_Rsp_From_HVAC_FP_R_CAN_5_03: 8 HVAC_FP_R

BO_ 2497508762 UUDT_Rsp_From_HVAC_FP_R_CAN_5_04: 8 HVAC_FP_R

BO_ 2497509018 UUDT_Rsp_From_HVAC_FP_R_CAN_5_05: 8 HVAC_FP_R

BO_ 2487022355 UUDT_Rsp_From_ICCM_CAN_3_connect: 8 CGM

BO_ 2487023123 UUDT_Rsp_From_ICCM_CAN_3_conne01: 8 CGM

BO_ 2497507686 UUDT_Rsp_From_ICS_Info_CAN_5_con: 8 ICS_Info

BO_ 2497507942 UUDT_Rsp_From_ICS_Info_CAN_5_c01: 8 ICS_Info

BO_ 2497508198 UUDT_Rsp_From_ICS_Info_CAN_5_c02: 8 ICS_Info

BO_ 2497508454 UUDT_Rsp_From_ICS_Info_CAN_5_c03: 8 ICS_Info

BO_ 2497508710 UUDT_Rsp_From_ICS_Info_CAN_5_c04: 8 ICS_Info

BO_ 2497508966 UUDT_Rsp_From_ICS_Info_CAN_5_c05: 8 ICS_Info

BO_ 2485973990 UUDT_Rsp_From_LIB1_CAN_2_connect: 8 CGM

BO_ 2485974758 UUDT_Rsp_From_LIB1_CAN_2_conne01: 8 CGM

BO_ 2487022572 UUDT_Rsp_From_LIB_48V_CAN_3_conn: 8 CGM

BO_ 2487023340 UUDT_Rsp_From_LIB_48V_CAN_3_co01: 8 CGM

BO_ 2492265426 UUDT_Rsp_From_LRR_CAN_8_connecto: 8 CGM

BO_ 2492266194 UUDT_Rsp_From_LRR_CAN_8_connec01: 8 CGM

BO_ 2497507725 UUDT_Rsp_From_MFC_CAN_5_connecto: 8 MFC

BO_ 2497507981 UUDT_Rsp_From_MFC_CAN_5_connec01: 8 MFC

BO_ 2497508237 UUDT_Rsp_From_MFC_CAN_5_connec02: 8 MFC

BO_ 2497508493 UUDT_Rsp_From_MFC_CAN_5_connec03: 8 MFC

BO_ 2497508749 UUDT_Rsp_From_MFC_CAN_5_connec04: 8 MFC

BO_ 2497509005 UUDT_Rsp_From_MFC_CAN_5_connec05: 8 MFC

BO_ 2488071083 UUDT_Rsp_From_MRCM_L_CAN_4_conne: 8 CGM

BO_ 2488071851 UUDT_Rsp_From_MRCM_L_CAN_4_con01: 8 CGM

BO_ 2488071084 UUDT_Rsp_From_MRCM_R_CAN_4_conne: 8 CGM

BO_ 2488071852 UUDT_Rsp_From_MRCM_R_CAN_4_con01: 8 CGM

BO_ 2484925276 UUDT_Rsp_From_MSB1_CAN_1_connect: 8 CGM

BO_ 2484926044 UUDT_Rsp_From_MSB1_CAN_1_conne01: 8 CGM

BO_ 2484925278 UUDT_Rsp_From_MSB2_CAN_1_connect: 8 CGM

BO_ 2484926046 UUDT_Rsp_From_MSB2_CAN_1_conne01: 8 CGM

BO_ 2488071080 UUDT_Rsp_From_MSM_D_CAN_4_connec: 8 CGM

BO_ 2488071848 UUDT_Rsp_From_MSM_D_CAN_4_conn01: 8 CGM

BO_ 2488071082 UUDT_Rsp_From_MSM_LR_CAN_4_conne: 8 CGM

BO_ 2488071850 UUDT_Rsp_From_MSM_LR_CAN_4_con01: 8 CGM

BO_ 2488071078 UUDT_Rsp_From_MSM_P_CAN_4_connec: 8 CGM

BO_ 2488071846 UUDT_Rsp_From_MSM_P_CAN_4_conn01: 8 CGM

BO_ 2488071079 UUDT_Rsp_From_MSM_RR_CAN_4_conne: 8 CGM

BO_ 2488071847 UUDT_Rsp_From_MSM_RR_CAN_4_con01: 8 CGM

BO_ 2488071089 UUDT_Rsp_From_MTCM_L_CAN_4_conne: 8 CGM

BO_ 2488071857 UUDT_Rsp_From_MTCM_L_CAN_4_con01: 8 CGM

BO_ 2488071096 UUDT_Rsp_From_MTCM_R_CAN_4_conne: 8 CGM

BO_ 2488071864 UUDT_Rsp_From_MTCM_R_CAN_4_con01: 8 CGM

BO_ 2485973861 UUDT_Rsp_From_NVM_CAN_2_connecto: 8 CGM

BO_ 2485974629 UUDT_Rsp_From_NVM_CAN_2_connec01: 8 CGM

BO_ 2493313975 UUDT_Rsp_From_ODS2_CAN_9_connect: 8 CGM

BO_ 2493314743 UUDT_Rsp_From_ODS2_CAN_9_conne01: 8 CGM

BO_ 2493313974 UUDT_Rsp_From_ODS_CAN_9_connecto: 8 CGM

BO_ 2493314742 UUDT_Rsp_From_ODS_CAN_9_connec01: 8 CGM

BO_ 2484925375 UUDT_Rsp_From_PA_CAN_1_connector: 8 CGM

BO_ 2484926143 UUDT_Rsp_From_PA_CAN_1_connect01: 8 CGM

BO_ 2485973776 UUDT_Rsp_From_PCM_CAN_2_connecto: 8 CGM

BO_ 2485974544 UUDT_Rsp_From_PCM_CAN_2_connec01: 8 CGM

BO_ 2497507689 UUDT_Rsp_From_PDR_CAN_5_connecto: 8 PDR

BO_ 2497507945 UUDT_Rsp_From_PDR_CAN_5_connec01: 8 PDR

BO_ 2497508201 UUDT_Rsp_From_PDR_CAN_5_connec02: 8 PDR

BO_ 2497508457 UUDT_Rsp_From_PDR_CAN_5_connec03: 8 PDR

BO_ 2497508713 UUDT_Rsp_From_PDR_CAN_5_connec04: 8 PDR

BO_ 2497508969 UUDT_Rsp_From_PDR_CAN_5_connec05: 8 PDR

BO_ 2488071091 UUDT_Rsp_From_PFCM_CAN_4_connect: 8 CGM

BO_ 2488071859 UUDT_Rsp_From_PFCM_CAN_4_conne01: 8 CGM

BO_ 2497507821 UUDT_Rsp_From_PLCM_CAN_5_connect: 8 PLCM

BO_ 2497508077 UUDT_Rsp_From_PLCM_CAN_5_conne01: 8 PLCM

BO_ 2497508333 UUDT_Rsp_From_PLCM_CAN_5_conne02: 8 PLCM

BO_ 2497508589 UUDT_Rsp_From_PLCM_CAN_5_conne03: 8 PLCM

BO_ 2497508845 UUDT_Rsp_From_PLCM_CAN_5_conne04: 8 PLCM

BO_ 2497509101 UUDT_Rsp_From_PLCM_CAN_5_conne05: 8 PLCM

BO_ 2488071076 UUDT_Rsp_From_PTM_CAN_4_connecto: 8 CGM

BO_ 2488071844 UUDT_Rsp_From_PTM_CAN_4_connec01: 8 CGM

BO_ 2485973786 UUDT_Rsp_From_RDCM_CAN_2_connect: 8 CGM

BO_ 2485974554 UUDT_Rsp_From_RDCM_CAN_2_conne01: 8 CGM

BO_ 2497507717 UUDT_Rsp_From_RSI_CAN_5_connecto: 8 RSI

BO_ 2497507973 UUDT_Rsp_From_RSI_CAN_5_connec01: 8 RSI

BO_ 2497508229 UUDT_Rsp_From_RSI_CAN_5_connec02: 8 RSI

BO_ 2497508485 UUDT_Rsp_From_RSI_CAN_5_connec03: 8 RSI

BO_ 2497508741 UUDT_Rsp_From_RSI_CAN_5_connec04: 8 RSI

BO_ 2497508997 UUDT_Rsp_From_RSI_CAN_5_connec05: 8 RSI

BO_ 2487022392 UUDT_Rsp_From_SADS_CAN_3_connect: 8 CGM

BO_ 2487023160 UUDT_Rsp_From_SADS_CAN_3_conne01: 8 CGM

BO_ 2484925344 UUDT_Rsp_From_SAM_LF_CAN_1_conne: 8 CGM

BO_ 2484926112 UUDT_Rsp_From_SAM_LF_CAN_1_con01: 8 CGM

BO_ 2484925346 UUDT_Rsp_From_SAM_LR_CAN_1_conne: 8 CGM

BO_ 2484926114 UUDT_Rsp_From_SAM_LR_CAN_1_con01: 8 CGM

BO_ 2488071073 UUDT_Rsp_From_SAM_RF_CAN_4_conne: 8 CGM

BO_ 2488071841 UUDT_Rsp_From_SAM_RF_CAN_4_con01: 8 CGM

BO_ 2488071075 UUDT_Rsp_From_SAM_RR_CAN_4_conne: 8 CGM

BO_ 2488071843 UUDT_Rsp_From_SAM_RR_CAN_4_con01: 8 CGM

BO_ 2487022379 UUDT_Rsp_From_SBM_CAN_3_connecto: 8 CGM

BO_ 2487023147 UUDT_Rsp_From_SBM_CAN_3_connec01: 8 CGM

BO_ 2488071097 UUDT_Rsp_From_SBZA_L_CAN_4_conne: 8 CGM

BO_ 2488071865 UUDT_Rsp_From_SBZA_L_CAN_4_con01: 8 CGM

BO_ 2488071098 UUDT_Rsp_From_SBZA_R_CAN_4_conne: 8 CGM

BO_ 2488071866 UUDT_Rsp_From_SBZA_R_CAN_4_con01: 8 CGM

BO_ 2484925378 UUDT_Rsp_From_SCL_CAN_1_connecto: 8 CGM

BO_ 2484926146 UUDT_Rsp_From_SCL_CAN_1_connec01: 8 CGM

BO_ 2493313880 UUDT_Rsp_From_SDM_CAN_9_connecto: 8 CGM

BO_ 2493314648 UUDT_Rsp_From_SDM_CAN_9_connec01: 8 CGM

BO_ 2484925254 UUDT_Rsp_From_SIB_CAN_1_connecto: 8 CGM

BO_ 2484926022 UUDT_Rsp_From_SIB_CAN_1_connec01: 8 CGM

BO_ 2492265427 UUDT_Rsp_From_SRR_LF_CAN_8_conne: 8 CGM

BO_ 2492266195 UUDT_Rsp_From_SRR_LF_CAN_8_con01: 8 CGM

BO_ 2492265431 UUDT_Rsp_From_SRR_LR_CR_CAN_8_co: 8 CGM

BO_ 2492266199 UUDT_Rsp_From_SRR_LR_CR_CAN_8_01: 8 CGM

BO_ 2492265430 UUDT_Rsp_From_SRR_RF_CAN_8_conne: 8 CGM

BO_ 2492266198 UUDT_Rsp_From_SRR_RF_CAN_8_con01: 8 CGM

BO_ 2492265432 UUDT_Rsp_From_SRR_RR_CAN_8_conne: 8 CGM

BO_ 2492266200 UUDT_Rsp_From_SRR_RR_CAN_8_con01: 8 CGM

BO_ 2492265433 UUDT_Rsp_From_SRR_SLR_CAN_8_conn: 8 CGM

BO_ 2492266201 UUDT_Rsp_From_SRR_SLR_CAN_8_co01: 8 CGM

BO_ 2492265434 UUDT_Rsp_From_SRR_SRR_CAN_8_conn: 8 CGM

BO_ 2492266202 UUDT_Rsp_From_SRR_SRR_CAN_8_co01: 8 CGM

BO_ 2485973784 UUDT_Rsp_From_TCM_CAN_2_connecto: 8 CGM

BO_ 2485974552 UUDT_Rsp_From_TCM_CAN_2_connec01: 8 CGM

BO_ 2497507735 UUDT_Rsp_From_TCP_CAN_5_connecto: 8 TCP

BO_ 2497507991 UUDT_Rsp_From_TCP_CAN_5_connec01: 8 TCP

BO_ 2497508503 UUDT_Rsp_From_TCP_CAN_5_connec02: 8 TCP

BO_ 2497508759 UUDT_Rsp_From_TCP_CAN_5_connec03: 8 TCP

BO_ 2497509015 UUDT_Rsp_From_TCP_CAN_5_connec04: 8 TCP

BO_ 2488071029 UUDT_Rsp_From_TIM_CAN_4_connecto: 8 CGM

BO_ 2488071797 UUDT_Rsp_From_TIM_CAN_4_connec01: 8 CGM

BO_ 2492265450 UUDT_Rsp_From_UPM_CAN_8_connecto: 8 CGM

BO_ 2492266218 UUDT_Rsp_From_UPM_CAN_8_connec01: 8 CGM

BO_ 2484925264 UUDT_Rsp_From_UVM_CAN_1_connecto: 8 CGM

BO_ 2484926032 UUDT_Rsp_From_UVM_CAN_1_connec01: 8 CGM

BO_ 2485973836 UUDT_Rsp_From_VDM_CAN_2_connecto: 8 CGM

BO_ 2485974604 UUDT_Rsp_From_VDM_CAN_2_connec01: 8 CGM

BO_ 2485973965 UUDT_Rsp_From_VECM_CAN_2_connect: 8 CGM

BO_ 2485974733 UUDT_Rsp_From_VECM_CAN_2_conne01: 8 CGM

BO_ 2497507732 UUDT_Rsp_From_VKM_CAN_5_connecto: 8 VKM

BO_ 2497507988 UUDT_Rsp_From_VKM_CAN_5_connec01: 8 VKM

BO_ 2497508244 UUDT_Rsp_From_VKM_CAN_5_connec02: 8 VKM

BO_ 2497508500 UUDT_Rsp_From_VKM_CAN_5_connec03: 8 VKM

BO_ 2497508756 UUDT_Rsp_From_VKM_CAN_5_connec04: 8 VKM

BO_ 2497509012 UUDT_Rsp_From_VKM_CAN_5_connec05: 8 VKM

BO_ 2487022393 UUDT_Rsp_From_VLM_CAN_3_connecto: 8 CGM

BO_ 2487023161 UUDT_Rsp_From_VLM_CAN_3_connec01: 8 CGM

BO_ 2484925293 UUDT_Rsp_From_VPM_CAN_1_connecto: 8 CGM

BO_ 2484926061 UUDT_Rsp_From_VPM_CAN_1_connec01: 8 CGM

BO_ 2497507779 UUDT_Rsp_From_WCM2_CAN_5_connect: 8 WCM2

BO_ 2497508035 UUDT_Rsp_From_WCM2_CAN_5_conne01: 8 WCM2

BO_ 2497508291 UUDT_Rsp_From_WCM2_CAN_5_conne02: 8 WCM2

BO_ 2497508547 UUDT_Rsp_From_WCM2_CAN_5_conne03: 8 WCM2

BO_ 2497508803 UUDT_Rsp_From_WCM2_CAN_5_conne04: 8 WCM2

BO_ 2497509059 UUDT_Rsp_From_WCM2_CAN_5_conne05: 8 WCM2

BO_ 2497507780 UUDT_Rsp_From_WCM3_CAN_5_connect: 8 WCM3

BO_ 2497508036 UUDT_Rsp_From_WCM3_CAN_5_conne01: 8 WCM3

BO_ 2497508292 UUDT_Rsp_From_WCM3_CAN_5_conne02: 8 WCM3

BO_ 2497508548 UUDT_Rsp_From_WCM3_CAN_5_conne03: 8 WCM3

BO_ 2497508804 UUDT_Rsp_From_WCM3_CAN_5_conne04: 8 WCM3

BO_ 2497509060 UUDT_Rsp_From_WCM3_CAN_5_conne05: 8 WCM3

BO_ 2497507781 UUDT_Rsp_From_WCM4_CAN_5_connect: 8 WCM4

BO_ 2497508037 UUDT_Rsp_From_WCM4_CAN_5_conne01: 8 WCM4

BO_ 2497508293 UUDT_Rsp_From_WCM4_CAN_5_conne02: 8 WCM4

BO_ 2497508549 UUDT_Rsp_From_WCM4_CAN_5_conne03: 8 WCM4

BO_ 2497508805 UUDT_Rsp_From_WCM4_CAN_5_conne04: 8 WCM4

BO_ 2497509061 UUDT_Rsp_From_WCM4_CAN_5_conne05: 8 WCM4

BO_ 2497507774 UUDT_Rsp_From_WCM_CAN_5_connecto: 8 WCM

BO_ 2497508030 UUDT_Rsp_From_WCM_CAN_5_connec01: 8 WCM

BO_ 2497508286 UUDT_Rsp_From_WCM_CAN_5_connec02: 8 WCM

BO_ 2497508542 UUDT_Rsp_From_WCM_CAN_5_connec03: 8 WCM

BO_ 2497508798 UUDT_Rsp_From_WCM_CAN_5_connec04: 8 WCM

BO_ 2497509054 UUDT_Rsp_From_WCM_CAN_5_connec05: 8 WCM

BO_ 1254 UnlckKeyStorCrptoDat1_PDU: 8 CGM
 SG_ UnlckKeyStorCrptoDat1 : 7|64@0+ (1,0) [0|1.84467e+019] "" RadioLow,CSM,CSM_AV,VCU

BO_ 1812 UnlckKeyStorCrptoDat2_PDU: 8 CGM
 SG_ UnlckKeyStorCrptoDat2 : 7|64@0+ (1,0) [0|1.84467e+019] "" RadioLow,CSM,CSM_AV,VCU

BO_ 404 VKM_NM_PDU_On_CAN_5_Cluster: 8 VKM
 SG_ ISignal_VKM_CAN_5_Cluster : 23|48@0+ (1,0) [0|281474976710655] "" AMP,CGM,FPI,HVAC_FP_F,HVAC_FP_R,ICS_Info,PDR,MFC,PLCM,RSI,RadioLow,TCP,CSM,CSM_AV,IPC,IPC_INT,VCU,WCM,WCM2,WCM3,WCM4

BO_ 1179 VehIdNmDig10_17_PDU: 8 CGM
 SG_ VehIdNmDig10_17 : 7|64@0+ (1,0) [0|18446744073709551615] "" FPI,PDR,RSI,RadioLow,TCP,VKM,CSM,CSM_AV,VCU

BO_ 1887 VehIdNmDig2_9_PDU: 8 CGM
 SG_ VehIdNmDig2_9 : 7|64@0+ (1,0) [0|18446744073709551615] "" FPI,PDR,RSI,RadioLow,TCP,VKM,CSM,CSM_AV,VCU

BO_ 890 VehIntgrtnCtlModInfo1_PCSM_PDU: 8 CGM
 SG_ VehIntgrtnCtlModInfo1_PCSM : 0|64@1+ (1,0) [0|1.84467e+019] "" PLCM

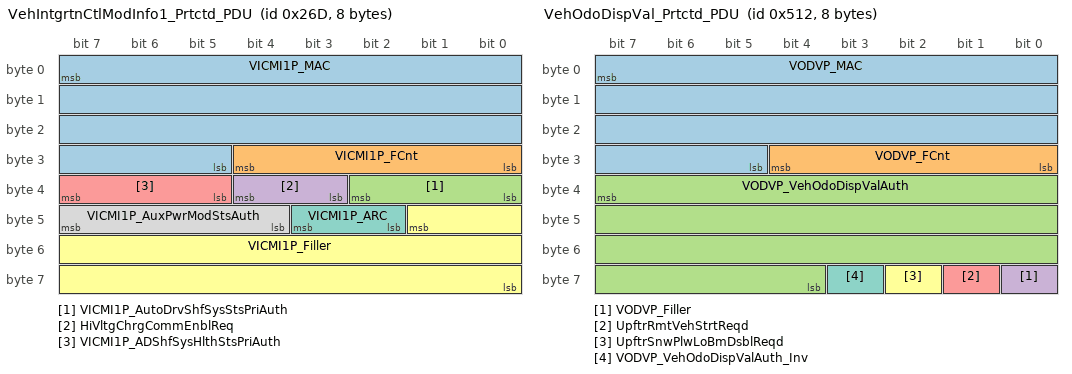
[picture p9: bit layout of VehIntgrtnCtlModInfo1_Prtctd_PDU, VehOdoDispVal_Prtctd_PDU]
BO_ 621 VehIntgrtnCtlModInfo1_Prtctd_PDU: 8 CGM
 SG_ VICMI1P_MAC : 7|27@0+ (1,0) [0|1.34218e+008] "" PLCM
 SG_ VICMI1P_FCnt : 28|5@0+ (1,0) [0|31] "" PLCM
 SG_ VICMI1P_AutoDrvShfSysStsPriAuth : 34|3@0+ (1,0) [0|4] "" PLCM
 SG_ HiVltgChrgCommEnblReq : 36|2@0+ (1,0) [0|2] "" PLCM,VCU
 SG_ VICMI1P_ADShfSysHlthStsPriAuth : 39|3@0+ (1,0) [0|4] "" PLCM
 SG_ VICMI1P_Filler : 41|18@0+ (1,0) [0|262143] "" PLCM
 SG_ VICMI1P_ARC : 43|2@0+ (1,0) [0|3] "" PLCM
 SG_ VICMI1P_AuxPwrModStsAuth : 47|4@0+ (1,0) [0|10] "" PLCM

BO_ 1370 VehOdoDispVal_PCSM_PDU: 8 CGM
 SG_ VehOdoDispVal_PCSM : 0|64@1+ (1,0) [0|1.84467e+019] "" IPC,IPC_INT,VCU

BO_ 1298 VehOdoDispVal_Prtctd_PDU: 8 CGM
 SG_ VODVP_MAC : 7|27@0+ (1,0) [0|1.34218e+008] "" IPC,IPC_INT,VCU
 SG_ VODVP_FCnt : 28|5@0+ (1,0) [0|31] "" IPC,IPC_INT,VCU
 SG_ VODVP_VehOdoDispValAuth : 39|28@0+ (0.015625,0) [0|4.1943e+006] "km" PDR,RadioLow,TCP,VKM,CSM,CSM_AV,IPC,IPC_INT,VCU
 SG_ VODVP_Filler : 56|1@0+ (1,0) [0|1] "" IPC,IPC_INT,VCU
 SG_ UpftrRmtVehStrtReqd : 57|1@0+ (1,0) [0|1] "" IPC,IPC_INT,VCU
 SG_ UpftrSnwPlwLoBmDsblReqd : 58|1@0+ (1,0) [0|1] "" IPC,IPC_INT,VCU
 SG_ VODVP_VehOdoDispValAuth_Inv : 59|1@0+ (1,0) [0|1] "" PDR,RadioLow,TCP,CSM,CSM_AV,IPC,IPC_INT,VCU

BO_ 1356 VehOdoStrdDispVal_PCSM_PDU: 8 IPC
 SG_ VehOdoStrdDispVal_PCSM : 0|64@1+ (1,0) [0|1.84467e+019] "" Vector__XXX

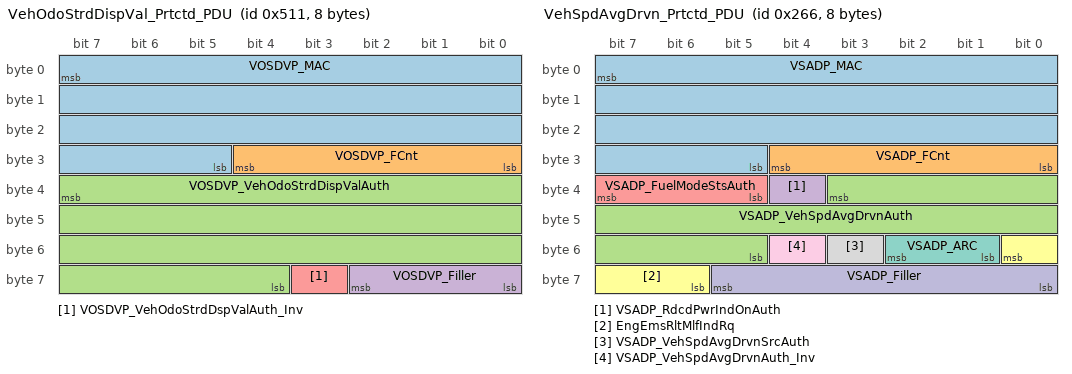
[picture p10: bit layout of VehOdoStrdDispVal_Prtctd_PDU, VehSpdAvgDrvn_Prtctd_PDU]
BO_ 1297 VehOdoStrdDispVal_Prtctd_PDU: 8 IPC
 SG_ VOSDVP_MAC : 7|27@0+ (1,0) [0|1.34218e+008] "" Vector__XXX
 SG_ VOSDVP_FCnt : 28|5@0+ (1,0) [0|31] "" Vector__XXX
 SG_ VOSDVP_VehOdoStrdDispValAuth : 39|28@0+ (0.015625,0) [0|4.1943e+006] "km" Vector__XXX
 SG_ VOSDVP_Filler : 58|3@0+ (1,0) [0|7] "" Vector__XXX
 SG_ VOSDVP_VehOdoStrdDspValAuth_Inv : 59|1@0+ (1,0) [0|1] "" Vector__XXX

BO_ 1402 VehSpdAvgDrvn_PCSM_PDU: 8 CGM
 SG_ VehSpdAvgDrvn_PCSM : 0|64@1+ (1,0) [0|1.84467e+019] "" PLCM,TCP,VKM,IPC,IPC_INT,VCU

BO_ 614 VehSpdAvgDrvn_Prtctd_PDU: 8 CGM
 SG_ VSADP_MAC : 7|27@0+ (1,0) [0|1.34218e+008] "" PLCM,TCP,VKM,IPC,IPC_INT,VCU
 SG_ VSADP_FCnt : 28|5@0+ (1,0) [0|31] "" PLCM,TCP,VKM,IPC,IPC_INT,VCU
 SG_ VSADP_VehSpdAvgDrvnAuth : 35|15@0+ (0.015625,0) [0|511.984] "km / h" AMP,FPI,HVAC_FP_F,HVAC_FP_R,ICS_Info,PDR,MFC,PLCM,RSI,RadioLow,TCP,VKM,CSM,CSM_AV,IPC,IPC_INT,VCU,WCM,WCM2,WCM3,WCM4
 SG_ VSADP_RdcdPwrIndOnAuth : 36|1@0+ (1,0) [0|1] "" AMP,PLCM,TCP,VKM,CSM,CSM_AV,IPC,IPC_INT,VCU
 SG_ VSADP_FuelModeStsAuth : 39|3@0+ (1,0) [0|4] "" PLCM,TCP,VKM,CSM,CSM_AV,IPC,IPC_INT,VCU
 SG_ EngEmsRltMlfIndRq : 48|3@0+ (1,0) [0|4] "" PLCM,TCP,VKM,CSM,CSM_AV,IPC,IPC_INT,VCU
 SG_ VSADP_ARC : 50|2@0+ (1,0) [0|3] "" PLCM,TCP,VKM,IPC,IPC_INT,VCU
 SG_ VSADP_VehSpdAvgDrvnSrcAuth : 51|1@0+ (1,0) [0|1] "" AMP,HVAC_FP_F,HVAC_FP_R,ICS_Info,PDR,PLCM,RadioLow,TCP,VKM,CSM,CSM_AV,IPC,IPC_INT,VCU
 SG_ VSADP_VehSpdAvgDrvnAuth_Inv : 52|1@0+ (1,0) [0|1] "" AMP,FPI,HVAC_FP_F,HVAC_FP_R,ICS_Info,PDR,PLCM,RSI,RadioLow,TCP,VKM,CSM,CSM_AV,IPC,IPC_INT,VCU,WCM,WCM2,WCM3,WCM4
 SG_ VSADP_Filler : 61|6@0+ (1,0) [0|63] "" PLCM,TCP,VKM,IPC,IPC_INT,VCU

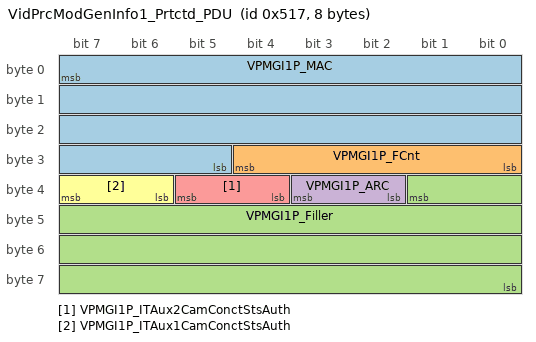
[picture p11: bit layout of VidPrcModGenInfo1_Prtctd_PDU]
BO_ 1303 VidPrcModGenInfo1_Prtctd_PDU: 8 CGM
 SG_ VPMGI1P_MAC : 7|27@0+ (1,0) [0|1.34218e+008] "" Vector__XXX
 SG_ VPMGI1P_FCnt : 28|5@0+ (1,0) [0|31] "" Vector__XXX
 SG_ VPMGI1P_Filler : 33|26@0+ (1,0) [0|6.71089e+007] "" Vector__XXX
 SG_ VPMGI1P_ARC : 35|2@0+ (1,0) [0|3] "" RadioLow,CSM,CSM_AV,VCU
 SG_ VPMGI1P_ITAux2CamConctStsAuth : 37|2@0+ (1,0) [0|2] "" RadioLow,CSM,CSM_AV,VCU
 SG_ VPMGI1P_ITAux1CamConctStsAuth : 39|2@0+ (1,0) [0|2] "" RadioLow,CSM,CSM_AV,VCU

BA_DEF_ SG_  "SignalType" STRING ;
BA_DEF_ SG_  "SignalLongName" STRING ;
BA_DEF_ BO_  "GenMsgCycleTime" INT 0 10000;
BA_DEF_ BO_  "GenMsgSendType" ENUM "cyclicX","spontanX","cyclicIfActiveX","spontanWithDelay","cyclicAndSpontanX","cyclicAndSpontanWithDelay","spontanWithRepetition","cyclicIfActiveAndSpontanWD";
BA_DEF_DEF_  "SignalType" "";
BA_DEF_DEF_  "SignalLongName" "";
BA_DEF_DEF_  "GenMsgCycleTime" 0;
BA_DEF_DEF_  "GenMsgSendType" "cyclicX";
BA_ "GenMsgCycleTime" BO_ 1095 1000;
BA_ "GenMsgCycleTime" BO_ 1092 3500;
BA_ "GenMsgCycleTime" BO_ 1094 1000;
BA_ "GenMsgCycleTime" BO_ 1096 3500;
BA_ "GenMsgCycleTime" BO_ 1093 1000;
BA_ "GenMsgCycleTime" BO_ 756 100;
BA_ "GenMsgCycleTime" BO_ 1990 1000;
BA_ "GenMsgCycleTime" BO_ 1081 1000;
BA_ "GenMsgCycleTime" BO_ 549 25;
BA_ "GenMsgCycleTime" BO_ 1397 1000;
BA_ "GenMsgCycleTime" BO_ 881 100;
BA_ "GenMsgCycleTime" BO_ 622 100;
BA_ "GenMsgCycleTime" BO_ 1359 3500;
BA_ "GenMsgCycleTime" BO_ 1319 1000;
BA_ "GenMsgCycleTime" BO_ 1361 3500;
BA_ "GenMsgCycleTime" BO_ 1311 1000;
BA_ "GenMsgCycleTime" BO_ 1396 3500;
BA_ "GenMsgCycleTime" BO_ 1316 1000;
BA_ "GenMsgCycleTime" BO_ 713 100;
BA_ "GenMsgCycleTime" BO_ 1171 1000;
BA_ "GenMsgCycleTime" BO_ 1284 1000;
BA_ "GenMsgCycleTime" BO_ 1283 1000;
BA_ "GenMsgCycleTime" BO_ 597 100;
BA_ "GenMsgCycleTime" BO_ 1403 1000;
BA_ "GenMsgCycleTime" BO_ 878 250;
BA_ "GenMsgCycleTime" BO_ 1358 3500;
BA_ "GenMsgCycleTime" BO_ 1299 1000;
BA_ "GenMsgCycleTime" BO_ 1357 2000;
BA_ "GenMsgCycleTime" BO_ 865 500;
BA_ "GenMsgCycleTime" BO_ 1254 1000;
BA_ "GenMsgCycleTime" BO_ 1812 1000;
BA_ "GenMsgCycleTime" BO_ 1179 1000;
BA_ "GenMsgCycleTime" BO_ 1887 1000;
BA_ "GenMsgCycleTime" BO_ 621 100;
BA_ "GenMsgCycleTime" BO_ 1370 3500;
BA_ "GenMsgCycleTime" BO_ 1298 1000;
BA_ "GenMsgCycleTime" BO_ 1356 3500;
BA_ "GenMsgCycleTime" BO_ 1297 1000;
BA_ "GenMsgCycleTime" BO_ 614 100;
BA_ "GenMsgCycleTime" BO_ 1303 1000;
BA_ "SignalLongName" SG_ 1095 SD267P_MAC "Serial Data 267 Protected : MAC";
BA_ "SignalLongName" SG_ 1095 SD267P_FCnt "Serial Data 267 Protected : Freshness Counter";
BA_ "SignalLongName" SG_ 1095 VSEMBatSOCDpltnLvlMinValAllwd "Serial Data 267 Protected : Vehicle State Extend Mode Battery State of Charge Depletion Level Minimum Value Allowed";
BA_ "SignalLongName" SG_ 1095 VSEMBatSOCDpltnLvlCurrSetVal "Serial Data 267 Protected : Vehicle State Extend Mode Battery State of Charge Depletion Level Current Setting Value";
BA_ "SignalLongName" SG_ 1095 VSEMTmDurCurrSetVal "Serial Data 267 Protected : Vehicle State Extend Mode Time Duration Current Setting Value";
BA_ "SignalLongName" SG_ 1095 VSEMTmDurMaxValAllwd "Serial Data 267 Protected : Vehicle State Extend Mode Time Duration Maximum Value Allowed";
BA_ "SignalLongName" SG_ 1095 SD267P_Filler "Serial Data 267 Protected : Filler";
BA_ "SignalType" SG_ 1095 VSEMOpModeCurrSetVal "ENM";
BA_ "SignalLongName" SG_ 1095 VSEMOpModeCurrSetVal "Serial Data 267 Protected : Vehicle State Extend Mode Operation Mode Current Setting Value";
BA_ "SignalType" SG_ 1095 VSEMActv "ENM";
BA_ "SignalLongName" SG_ 1095 VSEMActv "Serial Data 267 Protected : Vehicle State Extend Mode Active";
BA_ "SignalLongName" SG_ 1092 SrlDat268_PCSM "Serial Data 268 Protected Counter Sync Message";
BA_ "SignalLongName" SG_ 1094 SD268P_MAC "Serial Data 268 Protected : MAC";
BA_ "SignalLongName" SG_ 1094 SD268P_FCnt "Serial Data 268 Protected : Freshness Counter";
BA_ "SignalLongName" SG_ 1094 VSEMNormShtdnWrnDurTm "Serial Data 268 Protected : Vehicle State Extend Mode Normal Shutdown Warning Duration Time";
BA_ "SignalLongName" SG_ 1094 VSEMFltdShtdnWrnDurTm "Serial Data 268 Protected : Vehicle State Extend Mode Faulted Shutdown Warning Duration Time";
BA_ "SignalType" SG_ 1094 VSEMNormShtdnWrnIndOn "ENM";
BA_ "SignalLongName" SG_ 1094 VSEMNormShtdnWrnIndOn "Serial Data 268 Protected : Vehicle State Extend Mode Normal Shutdown Warning Indication On";
BA_ "SignalType" SG_ 1094 VSEMFltdShtdnWrnIndOn "ENM";
BA_ "SignalLongName" SG_ 1094 VSEMFltdShtdnWrnIndOn "Serial Data 268 Protected : Vehicle State Extend Mode Faulted Shutdown Warning Indication On";
BA_ "SignalType" SG_ 1094 CbnCondngSftyTVSEMAlrtIndOn "ENM";
BA_ "SignalLongName" SG_ 1094 CbnCondngSftyTVSEMAlrtIndOn "Serial Data 268 Protected : Cabin Conditioning Safety Temperature Alert Indication On";
BA_ "SignalType" SG_ 1094 CbnCondngFlrIndOn "ENM";
BA_ "SignalLongName" SG_ 1094 CbnCondngFlrIndOn "Serial Data 268 Protected : Cabin Conditioning Failure Indication On";
BA_ "SignalLongName" SG_ 1094 SD268P_Filler "Serial Data 268 Protected : Filler";
BA_ "SignalLongName" SG_ 1096 SrlDat269_PCSM "Serial Data 269 Protected Counter Sync Message";
BA_ "SignalLongName" SG_ 1093 SD269P_MAC "Serial Data 269 Protected : MAC";
BA_ "SignalLongName" SG_ 1093 SD269P_FCnt "Serial Data 269 Protected : Freshness Counter";
BA_ "SignalLongName" SG_ 1093 VSEMTmDurVirtCtlReq "Serial Data 269 Protected : Vehicle State Extend Mode Time Duration Virtual Control Request";
BA_ "SignalLongName" SG_ 1093 VSEMBatSOCDpltnLvlVirtCtlReq "Serial Data 269 Protected : Vehicle State Extend Mode Battery State of Charge Depletion Level Virtual Control Request";
BA_ "SignalType" SG_ 1093 VSEMOpVirtCtlReq "ENM";
BA_ "SignalLongName" SG_ 1093 VSEMOpVirtCtlReq "Serial Data 269 Protected : Vehicle State Extend Mode Operation Virtual Control Request";
BA_ "SignalType" SG_ 1093 ChrgPortDrClsrVirtCtlReq "ENM";
BA_ "SignalLongName" SG_ 1093 ChrgPortDrClsrVirtCtlReq "Serial Data 269 Protected : Charge Port Door Closure Virtual Control Request";
BA_ "SignalType" SG_ 1093 ChrgCommGtwayChrgAuthSts "ENM";
BA_ "SignalLongName" SG_ 1093 ChrgCommGtwayChrgAuthSts "Serial Data 269 Protected : Charging Communication Gateway Charge Authorization Status";
BA_ "SignalType" SG_ 1093 ChrgCommGtwayCommPrtclTyp "ENM";
BA_ "SignalLongName" SG_ 1093 ChrgCommGtwayCommPrtclTyp "Serial Data 269 Protected : Charging Communication Gateway Communication Protocol Type";
BA_ "SignalType" SG_ 1093 VSEMVehAlrtDsmssed "ENM";
BA_ "SignalLongName" SG_ 1093 VSEMVehAlrtDsmssed "Serial Data 269 Protected : Vehicle State Extend Mode Vehicle Alert Dismissed";
BA_ "SignalType" SG_ 1093 VSEMClmCtlsUnlckReqd "ENM";
BA_ "SignalLongName" SG_ 1093 VSEMClmCtlsUnlckReqd "Serial Data 269 Protected : Vehicle State Extend Mode Climate Controls Unlock Requested";
BA_ "SignalLongName" SG_ 1093 SD269P_ARC "Serial Data 269 Protected : Alive Rolling Count";
BA_ "SignalLongName" SG_ 1093 SD269P_Filler "Serial Data 269 Protected : Filler";
BA_ "SignalLongName" SG_ 976 SrlDat280_PCSM "Serial Data 280 Protected Counter Sync Message";
BA_ "SignalLongName" SG_ 756 SD280P_MAC "Serial Data 280 Protected : MAC";
BA_ "SignalLongName" SG_ 756 SD280P_FCnt "Serial Data 280 Protected : Freshness Counter";
BA_ "SignalLongName" SG_ 756 SD280P_Filler "Serial Data 280 Protected : Filler";
BA_ "SignalType" SG_ 756 OccptLtBehindeCallReqd "ENM";
BA_ "SignalLongName" SG_ 756 OccptLtBehindeCallReqd "Serial Data 280 Protected : Occupant Left Behind eCall Requested";
BA_ "SignalLongName" SG_ 756 SD280P_ARC "Serial Data 280 Protected : Alive Rolling Count";
BA_ "SignalType" SG_ 1990 ODSSecFncSts_Inv "ENM";
BA_ "SignalLongName" SG_ 1990 ODSSecFncSts_Inv "Serial Data 281 Protected : Occupant Detection Sensor Secondary Functional Status Invalid";
BA_ "SignalType" SG_ 1990 ODSSecFncSts "ENM";
BA_ "SignalLongName" SG_ 1990 ODSSecFncSts "Serial Data 281 Protected : Occupant Detection Sensor Secondary Functional Status";
BA_ "SignalType" SG_ 1990 ODSPriFncSts_Inv "ENM";
BA_ "SignalLongName" SG_ 1990 ODSPriFncSts_Inv "Serial Data 281 Protected : Occupant Detection Sensor Primary Functional Status Invalid";
BA_ "SignalType" SG_ 1990 ODSPriFncSts "ENM";
BA_ "SignalLongName" SG_ 1990 ODSPriFncSts "Serial Data 281 Protected : Occupant Detection Sensor Primary Functional Status";
BA_ "SignalType" SG_ 1990 ODSFrtLtFtwlPstnOcpd_Inv "ENM";
BA_ "SignalLongName" SG_ 1990 ODSFrtLtFtwlPstnOcpd_Inv "Serial Data 281 Protected : Occupant Detection Sensor Front Left Footwell Position Occupied Invalid";
BA_ "SignalType" SG_ 1990 ODSFrtLtFtwlPstnOcpd "ENM";
BA_ "SignalLongName" SG_ 1990 ODSFrtLtFtwlPstnOcpd "Serial Data 281 Protected : Occupant Detection Sensor Front Left Footwell Position Occupied";
BA_ "SignalType" SG_ 1990 ODSFrtRtPstnOcpd_Inv "ENM";
BA_ "SignalLongName" SG_ 1990 ODSFrtRtPstnOcpd_Inv "Serial Data 281 Protected : Occupant Detection Sensor Front Right Position Occupied Invalid";
BA_ "SignalType" SG_ 1990 ODSFrtRtPstnOcpd "ENM";
BA_ "SignalLongName" SG_ 1990 ODSFrtRtPstnOcpd "Serial Data 281 Protected : Occupant Detection Sensor Front Right Position Occupied";
BA_ "SignalType" SG_ 1990 ODSFrtCntrPstnOcpd_Inv "ENM";
BA_ "SignalLongName" SG_ 1990 ODSFrtCntrPstnOcpd_Inv "Serial Data 281 Protected : Occupant Detection Sensor Front Center Position Occupied Invalid";
BA_ "SignalType" SG_ 1990 ODSFrtCntrPstnOcpd "ENM";
BA_ "SignalLongName" SG_ 1990 ODSFrtCntrPstnOcpd "Serial Data 281 Protected : Occupant Detection Sensor Front Center Position Occupied";
BA_ "SignalType" SG_ 1990 ODSFrtLtPstnOcpd_Inv "ENM";
BA_ "SignalLongName" SG_ 1990 ODSFrtLtPstnOcpd_Inv "Serial Data 281 Protected : Occupant Detection Sensor Front Left Position Occupied Invalid";
BA_ "SignalType" SG_ 1990 ODSFrtLtPstnOcpd "ENM";
BA_ "SignalLongName" SG_ 1990 ODSFrtLtPstnOcpd "Serial Data 281 Protected : Occupant Detection Sensor Front Left Position Occupied";
BA_ "SignalType" SG_ 1990 ODSFrtRtFtwlPstnOcpd_Inv "ENM";
BA_ "SignalLongName" SG_ 1990 ODSFrtRtFtwlPstnOcpd_Inv "Serial Data 281 Protected : Occupant Detection Sensor Front Right Footwell Position Occupied Invalid";
BA_ "SignalType" SG_ 1990 ODSFrtRtFtwlPstnOcpd "ENM";
BA_ "SignalLongName" SG_ 1990 ODSFrtRtFtwlPstnOcpd "Serial Data 281 Protected : Occupant Detection Sensor Front Right Footwell Position Occupied";
BA_ "SignalType" SG_ 1990 ODSFrtCntFtwlPstnOcpd_Inv "ENM";
BA_ "SignalLongName" SG_ 1990 ODSFrtCntFtwlPstnOcpd_Inv "Serial Data 281 Protected : Occupant Detection Sensor Front Center Footwell Position Occupied Invalid";
BA_ "SignalType" SG_ 1990 ODSFrtCntFtwlPstnOcpd "ENM";
BA_ "SignalLongName" SG_ 1990 ODSFrtCntFtwlPstnOcpd "Serial Data 281 Protected : Occupant Detection Sensor Front Center Footwell Position Occupied";
BA_ "SignalType" SG_ 1081 ODSSecRwLtFtwlPstOcpd_Inv "ENM";
BA_ "SignalLongName" SG_ 1081 ODSSecRwLtFtwlPstOcpd_Inv "Serial Data 282 Protected : Occupant Detection Sensor Second Row Left Footwell Position Occupied Invalid";
BA_ "SignalType" SG_ 1081 ODSSecRwLtFtwlPstOcpd "ENM";
BA_ "SignalLongName" SG_ 1081 ODSSecRwLtFtwlPstOcpd "Serial Data 282 Protected : Occupant Detection Sensor Second Row Left Footwell Position Occupied";
BA_ "SignalType" SG_ 1081 ODSSecRowRtPstnOcpd_Inv "ENM";
BA_ "SignalLongName" SG_ 1081 ODSSecRowRtPstnOcpd_Inv "Serial Data 282 Protected : Occupant Detection Sensor Second Row Right Position Occupied Invalid";
BA_ "SignalType" SG_ 1081 ODSSecRowRtPstnOcpd "ENM";
BA_ "SignalLongName" SG_ 1081 ODSSecRowRtPstnOcpd "Serial Data 282 Protected : Occupant Detection Sensor Second Row Right Position Occupied";
BA_ "SignalType" SG_ 1081 ODSSecRowCntPstnOcpd_Inv "ENM";
BA_ "SignalLongName" SG_ 1081 ODSSecRowCntPstnOcpd_Inv "Serial Data 282 Protected : Occupant Detection Sensor Second Row Center Position Occupied Invalid";
BA_ "SignalType" SG_ 1081 ODSSecRowCntPstnOcpd "ENM";
BA_ "SignalLongName" SG_ 1081 ODSSecRowCntPstnOcpd "Serial Data 282 Protected : Occupant Detection Sensor Second Row Center Position Occupied";
BA_ "SignalType" SG_ 1081 ODSSecRowLtPstnOcpd_Inv "ENM";
BA_ "SignalLongName" SG_ 1081 ODSSecRowLtPstnOcpd_Inv "Serial Data 282 Protected : Occupant Detection Sensor Second Row Left Position Occupied Invalid";
BA_ "SignalType" SG_ 1081 ODSSecRowLtPstnOcpd "ENM";
BA_ "SignalLongName" SG_ 1081 ODSSecRowLtPstnOcpd "Serial Data 282 Protected : Occupant Detection Sensor Second Row Left Position Occupied";
BA_ "SignalType" SG_ 1081 ODSThrdRwCntrPstnOcpd_Inv "ENM";
BA_ "SignalLongName" SG_ 1081 ODSThrdRwCntrPstnOcpd_Inv "Serial Data 282 Protected : Occupant Detection Sensor Third Row Center Position Occupied Invalid";
BA_ "SignalType" SG_ 1081 ODSThrdRwCntrPstnOcpd "ENM";
BA_ "SignalLongName" SG_ 1081 ODSThrdRwCntrPstnOcpd "Serial Data 282 Protected : Occupant Detection Sensor Third Row Center Position Occupied";
BA_ "SignalType" SG_ 1081 ODSThrdRowLtPstnOcpd_Inv "ENM";
BA_ "SignalLongName" SG_ 1081 ODSThrdRowLtPstnOcpd_Inv "Serial Data 282 Protected : Occupant Detection Sensor Third Row Left Position Occupied Invalid";
BA_ "SignalType" SG_ 1081 ODSThrdRowLtPstnOcpd "ENM";
BA_ "SignalLongName" SG_ 1081 ODSThrdRowLtPstnOcpd "Serial Data 282 Protected : Occupant Detection Sensor Third Row Left Position Occupied";
BA_ "SignalType" SG_ 1081 ODSSecRwRtFtwlPstOcpd_Inv "ENM";
BA_ "SignalLongName" SG_ 1081 ODSSecRwRtFtwlPstOcpd_Inv "Serial Data 282 Protected : Occupant Detection Sensor Second Row Right Footwell Position Occupied Invalid";
BA_ "SignalType" SG_ 1081 ODSSecRwRtFtwlPstOcpd "ENM";
BA_ "SignalLongName" SG_ 1081 ODSSecRwRtFtwlPstOcpd "Serial Data 282 Protected : Occupant Detection Sensor Second Row Right Footwell Position Occupied";
BA_ "SignalType" SG_ 1081 ODSSecRwCntFtwlPstOcpd_Inv "ENM";
BA_ "SignalLongName" SG_ 1081 ODSSecRwCntFtwlPstOcpd_Inv "Serial Data 282 Protected : Occupant Detection Sensor Second Row Center Footwell Position Occupied Invalid";
BA_ "SignalType" SG_ 1081 ODSSecRwCntFtwlPstOcpd "ENM";
BA_ "SignalLongName" SG_ 1081 ODSSecRwCntFtwlPstOcpd "Serial Data 282 Protected : Occupant Detection Sensor Second Row Center Footwell Position Occupied";
BA_ "SignalType" SG_ 1081 ODSThrdRwRtFtwlPstOcpd_Inv "ENM";
BA_ "SignalLongName" SG_ 1081 ODSThrdRwRtFtwlPstOcpd_Inv "Serial Data 282 Protected : Occupant Detection Sensor Third Row Right Footwell Position Occupied Invalid";
BA_ "SignalType" SG_ 1081 ODSThrdRwRtFtwlPstOcpd "ENM";
BA_ "SignalLongName" SG_ 1081 ODSThrdRwRtFtwlPstOcpd "Serial Data 282 Protected : Occupant Detection Sensor Third Row Right Footwell Position Occupied";
BA_ "SignalType" SG_ 1081 ODSThrdRwCntFtlPstOcpd_Inv "ENM";
BA_ "SignalLongName" SG_ 1081 ODSThrdRwCntFtlPstOcpd_Inv "Serial Data 282 Protected : Occupant Detection Sensor Third Row Center Footwell Position Occupied Invalid";
BA_ "SignalType" SG_ 1081 ODSThrdRwCntFtlPstOcpd "ENM";
BA_ "SignalLongName" SG_ 1081 ODSThrdRwCntFtlPstOcpd "Serial Data 282 Protected : Occupant Detection Sensor Third Row Center Footwell Position Occupied";
BA_ "SignalType" SG_ 1081 ODSThrdRwLtFtwlPstOcpd_Inv "ENM";
BA_ "SignalLongName" SG_ 1081 ODSThrdRwLtFtwlPstOcpd_Inv "Serial Data 282 Protected : Occupant Detection Sensor Third Row Left Footwell Position Occupied Invalid";
BA_ "SignalType" SG_ 1081 ODSThrdRwLtFtwlPstOcpd "ENM";
BA_ "SignalLongName" SG_ 1081 ODSThrdRwLtFtwlPstOcpd "Serial Data 282 Protected : Occupant Detection Sensor Third Row Left Footwell Position Occupied";
BA_ "SignalType" SG_ 1081 ODSThrdRowRtPstnOcpd_Inv "ENM";
BA_ "SignalLongName" SG_ 1081 ODSThrdRowRtPstnOcpd_Inv "Serial Data 282 Protected : Occupant Detection Sensor Third Row Right Position Occupied Invalid";
BA_ "SignalType" SG_ 1081 ODSThrdRowRtPstnOcpd "ENM";
BA_ "SignalLongName" SG_ 1081 ODSThrdRowRtPstnOcpd "Serial Data 282 Protected : Occupant Detection Sensor Third Row Right Position Occupied";
BA_ "SignalType" SG_ 1081 ODSCrgRtPstnOcpd_Inv "ENM";
BA_ "SignalLongName" SG_ 1081 ODSCrgRtPstnOcpd_Inv "Serial Data 282 Protected : Occupant Detection Sensor Cargo Right Position Occupied Invalid";
BA_ "SignalType" SG_ 1081 ODSCrgRtPstnOcpd "ENM";
BA_ "SignalLongName" SG_ 1081 ODSCrgRtPstnOcpd "Serial Data 282 Protected : Occupant Detection Sensor Cargo Right Position Occupied";
BA_ "SignalType" SG_ 1081 ODSCrgCntrPstnOcpd_Inv "ENM";
BA_ "SignalLongName" SG_ 1081 ODSCrgCntrPstnOcpd_Inv "Serial Data 282 Protected : Occupant Detection Sensor Cargo Center Position Occupied Invalid";
BA_ "SignalType" SG_ 1081 ODSCrgCntrPstnOcpd "ENM";
BA_ "SignalLongName" SG_ 1081 ODSCrgCntrPstnOcpd "Serial Data 282 Protected : Occupant Detection Sensor Cargo Center Position Occupied";
BA_ "SignalType" SG_ 1081 ODSCrgLtPstnOcpd_Inv "ENM";
BA_ "SignalLongName" SG_ 1081 ODSCrgLtPstnOcpd_Inv "Serial Data 282 Protected : Occupant Detection Sensor Cargo Left Position Occupied Invalid";
BA_ "SignalType" SG_ 1081 ODSCrgLtPstnOcpd "ENM";
BA_ "SignalLongName" SG_ 1081 ODSCrgLtPstnOcpd "Serial Data 282 Protected : Occupant Detection Sensor Cargo Left Position Occupied";
BA_ "SignalLongName" SG_ 981 SrlDat322_PCSM "Serial Data 322 Protected Counter Sync Message";
BA_ "SignalLongName" SG_ 549 SD322P_MAC "Serial Data 322 Protected : MAC";
BA_ "SignalLongName" SG_ 549 SD322P_FCnt "Serial Data 322 Protected : Freshness Counter";
BA_ "SignalLongName" SG_ 549 SD322P_Filler "Serial Data 322 Protected : Filler";
BA_ "SignalType" SG_ 549 ChrgStnEngyXferDir "ENM";
BA_ "SignalLongName" SG_ 549 ChrgStnEngyXferDir "Serial Data 322 Protected : Charging Station Energy Transfer Direction";
BA_ "SignalLongName" SG_ 549 SD322P_ARC "Serial Data 322 Protected : Alive Rolling Count";
BA_ "SignalLongName" SG_ 1397 SrlDat34_PCSM "Serial Data 34 Protected Counter Sync Message";
BA_ "SignalLongName" SG_ 881 SD34P_MAC "Serial Data 34 Protected : MAC";
BA_ "SignalLongName" SG_ 881 SD34P_FCnt "Serial Data 34 Protected : Freshness Counter";
BA_ "SignalType" SG_ 881 ASDRP_LnCntrWrnExtdIndReqAuth "ENM";
BA_ "SignalLongName" SG_ 881 ASDRP_LnCntrWrnExtdIndReqAuth "Serial Data 34 Protected : Lane Centering Warning Extended Indication Request Authenticated";
BA_ "SignalType" SG_ 881 ASDRP_LnCntrCtlIndReqAuth "ENM";
BA_ "SignalLongName" SG_ 881 ASDRP_LnCntrCtlIndReqAuth "Serial Data 34 Protected : Lane Centering Control Indication Request Authenticated";
BA_ "SignalType" SG_ 881 ACGIP_SrrndVsnRLSModeCmdAuth "ENM";
BA_ "SignalLongName" SG_ 881 ACGIP_SrrndVsnRLSModeCmdAuth "Serial Data 34 Protected : Surround Vision Redundant Lane Sensing Mode Command Authenticated";
BA_ "SignalType" SG_ 881 ACGIP_LnFllwFltIndcdAtBrkEnAuth "ENM";
BA_ "SignalLongName" SG_ 881 ACGIP_LnFllwFltIndcdAtBrkEnAuth "Serial Data 34 Protected : Lane Following Fault Induced Auto Braking Enabled Authenticated";
BA_ "SignalType" SG_ 881 HMIR1P_LnFllwgLHSChEvntStatAuth "ENM";
BA_ "SignalLongName" SG_ 881 HMIR1P_LnFllwgLHSChEvntStatAuth "Serial Data 34 Protected : Lane Following Left Hand Side Chime Event State Authenticated";
BA_ "SignalType" SG_ 881 HMIR1P_LnFllwgGenChEvntStatAuth "ENM";
BA_ "SignalLongName" SG_ 881 HMIR1P_LnFllwgGenChEvntStatAuth "Serial Data 34 Protected : Lane Following General Chime Event State Authenticated";
BA_ "SignalType" SG_ 881 ASTIP_LnCntrVehStopdAuth "ENM";
BA_ "SignalLongName" SG_ 881 ASTIP_LnCntrVehStopdAuth "Serial Data 34 Protected : Lane Centering Vehicle Stopped Authenticated";
BA_ "SignalType" SG_ 881 ADASXferOfCtlIndReq "ENM";
BA_ "SignalLongName" SG_ 881 ADASXferOfCtlIndReq "Serial Data 34 Protected : Advanced Driver Assist Systems Transfer Of Control Indication Request";
BA_ "SignalLongName" SG_ 881 SD34P_ARC "Serial Data 34 Protected : Alive Rolling Count";
BA_ "SignalType" SG_ 881 HMIR1P_LnFllwgRHSChEvntStatAuth "ENM";
BA_ "SignalLongName" SG_ 881 HMIR1P_LnFllwgRHSChEvntStatAuth "Serial Data 34 Protected : Lane Following Right Hand Side Chime Event State Authenticated";
BA_ "SignalLongName" SG_ 881 SD34P_Filler "Serial Data 34 Protected : Filler";
BA_ "SignalLongName" SG_ 881 ADASAutoRsmPrgsInd "Serial Data 34 Protected : Advanced Driver Assist Systems Auto Resume Progress Indication";
BA_ "SignalLongName" SG_ 898 SrlDat42_PCSM "Serial Data 42 Protected Counter Sync Message";
BA_ "SignalLongName" SG_ 622 SD42P_MAC "Serial Data 42 Protected : MAC";
BA_ "SignalLongName" SG_ 622 SD42P_FCnt "Serial Data 42 Protected : Freshness Counter";
BA_ "SignalType" SG_ 622 RrStrgModeVirtCtlSwReq "ENM";
BA_ "SignalLongName" SG_ 622 RrStrgModeVirtCtlSwReq "Serial Data 42 Protected : Rear Steering Mode Virtual Control Switch Request";
BA_ "SignalLongName" SG_ 622 SD42P_ARC "Serial Data 42 Protected : Alive Rolling Count";
BA_ "SignalType" SG_ 622 HMIGI2P_LnFllwgInterFltDtdAuth "ENM";
BA_ "SignalLongName" SG_ 622 HMIGI2P_LnFllwgInterFltDtdAuth "Serial Data 42 Protected : Lane Following Interface Fault Detected Authenticated";
BA_ "SignalType" SG_ 622 HMIGI2P_IPCFlrIndOnAuth "ENM";
BA_ "SignalLongName" SG_ 622 HMIGI2P_IPCFlrIndOnAuth "Serial Data 42 Protected : Instrument Panel Cluster Failure Indication On Authenticated";
BA_ "SignalType" SG_ 622 HMIGI1P_TrlrBrkDispActvAuth_DuD "ENM";
BA_ "SignalLongName" SG_ 622 HMIGI1P_TrlrBrkDispActvAuth_DuD "Serial Data 42 Protected : Trailer Brake Display Active Authenticated Don't Use Data";
BA_ "SignalType" SG_ 622 HMIGI1P_TrlrBrkDispActvAuth "ENM";
BA_ "SignalLongName" SG_ 622 HMIGI1P_TrlrBrkDispActvAuth "Serial Data 42 Protected : Trailer Brake Display Active Authenticated";
BA_ "SignalType" SG_ 622 HMIGI1P_EnvModPrsntRspdr4Auth "ENM";
BA_ "SignalLongName" SG_ 622 HMIGI1P_EnvModPrsntRspdr4Auth "Serial Data 42 Protected : Environment Module Present Responder #4 Authenticated";
BA_ "SignalLongName" SG_ 622 SD42P_Filler "Serial Data 42 Protected : Filler";
BA_ "SignalLongName" SG_ 1359 SrlDat49_PCSM "Serial Data 49 Protected Counter Sync Message";
BA_ "SignalLongName" SG_ 1319 SD49P_MAC "Serial Data 49 Protected : MAC";
BA_ "SignalLongName" SG_ 1319 SD49P_FCnt "Serial Data 49 Protected : Freshness Counter";
BA_ "SignalType" SG_ 1319 TSGI1P_EnhdServsAllWndRqAuth "ENM";
BA_ "SignalLongName" SG_ 1319 TSGI1P_EnhdServsAllWndRqAuth "Serial Data 49 Protected : Enhanced Services All Window Request Authenticated";
BA_ "SignalType" SG_ 1319 TGI1P_TlmRmtIgnBlkImbCmdAuth "ENM";
BA_ "SignalLongName" SG_ 1319 TGI1P_TlmRmtIgnBlkImbCmdAuth "Serial Data 49 Protected : Telematics Remote Ignition Block Immobilization Command Authenticated";
BA_ "SignalType" SG_ 1319 TGI1P_NewFobXmtrLrndRstAuth "ENM";
BA_ "SignalLongName" SG_ 1319 TGI1P_NewFobXmtrLrndRstAuth "Serial Data 49 Protected : New Fob Transmitter Learned Reset Authenticated";
BA_ "SignalType" SG_ 1319 TGI1P_EnhdServsRmtStrtReqAuth "ENM";
BA_ "SignalLongName" SG_ 1319 TGI1P_EnhdServsRmtStrtReqAuth "Serial Data 49 Protected : Enhanced Services Remote Start Request Authenticated";
BA_ "SignalType" SG_ 1319 TGI1P_EnhdServsLckReqAuth "ENM";
BA_ "SignalLongName" SG_ 1319 TGI1P_EnhdServsLckReqAuth "Serial Data 49 Protected : Enhanced Services Locking Request Authenticated";
BA_ "SignalType" SG_ 1319 GeofncngRstrctdZnSts "ENM";
BA_ "SignalLongName" SG_ 1319 GeofncngRstrctdZnSts "Serial Data 49 Protected : Geofencing Restricted Zone Status";
BA_ "SignalType" SG_ 1319 TVKRP_FobAvlReqAuth "ENM";
BA_ "SignalLongName" SG_ 1319 TVKRP_FobAvlReqAuth "Serial Data 49 Protected : Fob Availability Request Authenticated";
BA_ "SignalType" SG_ 1319 TSGI1P_EnhdServsSnrfRqAuth "ENM";
BA_ "SignalLongName" SG_ 1319 TSGI1P_EnhdServsSnrfRqAuth "Serial Data 49 Protected : Enhanced Services Sunroof Request Authenticated";
BA_ "SignalType" SG_ 1319 TSGI1P_EnhdServsRrClsrLckRqAuth "ENM";
BA_ "SignalLongName" SG_ 1319 TSGI1P_EnhdServsRrClsrLckRqAuth "Serial Data 49 Protected : Enhanced Services Rear Closure Locking Request Authenticated";
BA_ "SignalType" SG_ 1319 EnhdSrvsFrtStrCmptClsrLckRqAuth "ENM";
BA_ "SignalLongName" SG_ 1319 EnhdSrvsFrtStrCmptClsrLckRqAuth "Serial Data 49 Protected : Enhanced Services Front Storage Compartment Closure Locking Request Authenticated";
BA_ "SignalLongName" SG_ 1361 SrlDat5_PCSM "Serial Data 5 Protected Counter Sync Message";
BA_ "SignalLongName" SG_ 1311 SD5P_MAC "Serial Data 5 Protected : MAC";
BA_ "SignalLongName" SG_ 1311 SD5P_FCnt "Serial Data 5 Protected : Freshness Counter";
BA_ "SignalType" SG_ 1311 TDAP_DrvrStMemIdfrAuth "ENM";
BA_ "SignalLongName" SG_ 1311 TDAP_DrvrStMemIdfrAuth "Serial Data 5 Protected : Driver Seat Memory Identifier Authenticated";
BA_ "SignalType" SG_ 1311 TDAP_DrvrIdfrAuth "ENM";
BA_ "SignalLongName" SG_ 1311 TDAP_DrvrIdfrAuth "Serial Data 5 Protected : Driver Identifier Authenticated";
BA_ "SignalType" SG_ 1311 FTPP_TirePresLoIndOnAuth "ENM";
BA_ "SignalLongName" SG_ 1311 FTPP_TirePresLoIndOnAuth "Serial Data 5 Protected : Tire Pressure Low Indication On Authenticated";
BA_ "SignalType" SG_ 1311 FTPP_ServWprSysCtlIndOnAuth "ENM";
BA_ "SignalLongName" SG_ 1311 FTPP_ServWprSysCtlIndOnAuth "Serial Data 5 Protected : Service Wiper System Control Indication On Authenticated";
BA_ "SignalType" SG_ 1311 FTPP_FrtCmptFaildToOpnIndOnAuth "ENM";
BA_ "SignalLongName" SG_ 1311 FTPP_FrtCmptFaildToOpnIndOnAuth "Serial Data 5 Protected : Front Storage Compartment Failed to Open Indication On Authenticated";
BA_ "SignalType" SG_ 1311 FTPP_FrtCmptAjrWrnIndOnAuth "ENM";
BA_ "SignalLongName" SG_ 1311 FTPP_FrtCmptAjrWrnIndOnAuth "Serial Data 5 Protected : Front Compartment Ajar Warning Indication On Authenticated";
BA_ "SignalType" SG_ 1311 SCAOOARFKeyFobReqd "ENM";
BA_ "SignalLongName" SG_ 1311 SCAOOARFKeyFobReqd "Serial Data 5 Protected : Side Closure Access Open On Approach Right Front Key Fob Requested";
BA_ "SignalType" SG_ 1311 SCAOOALFKeyFobReqd "ENM";
BA_ "SignalLongName" SG_ 1311 SCAOOALFKeyFobReqd "Serial Data 5 Protected : Side Closure Access Open On Approach Left Front Key Fob Requested";
BA_ "SignalType" SG_ 1311 GnrcModeSwSts "ENM";
BA_ "SignalLongName" SG_ 1311 GnrcModeSwSts "Serial Data 5 Protected : Generic Mode Switch Status";
BA_ "SignalLongName" SG_ 1311 SD5P_ARC "Serial Data 5 Protected : Alive Rolling Count";
BA_ "SignalLongName" SG_ 1311 SD5P_Filler "Serial Data 5 Protected : Filler";
BA_ "SignalLongName" SG_ 1396 SrlDat6_PCSM "Serial Data 6 Protected Counter Sync Message";
BA_ "SignalLongName" SG_ 1316 SD6P_MAC "Serial Data 6 Protected : MAC";
BA_ "SignalLongName" SG_ 1316 SD6P_FCnt "Serial Data 6 Protected : Freshness Counter";
BA_ "SignalLongName" SG_ 1316 VKI2P_AuthIntrUserIdDevCntAuth "Serial Data 6 Protected : Authenticated Interior User Identification Device Count Authenticated";
BA_ "SignalType" SG_ 1316 TDAP_TeenDrvrActvAuth "ENM";
BA_ "SignalLongName" SG_ 1316 TDAP_TeenDrvrActvAuth "Serial Data 6 Protected : Teen Driver Active Authenticated";
BA_ "SignalType" SG_ 1316 RIP_RmtIgnBlkImbCustClrCmdAuth "ENM";
BA_ "SignalLongName" SG_ 1316 RIP_RmtIgnBlkImbCustClrCmdAuth "Serial Data 6 Protected : Remote Ignition Block Immobilization Customer Clear Command Authenticated";
BA_ "SignalType" SG_ 1316 RIP_NewFobXmtrLrndNtfnAuth "ENM";
BA_ "SignalLongName" SG_ 1316 RIP_NewFobXmtrLrndNtfnAuth "Serial Data 6 Protected : New Fob Transmitter Learned Notification Authenticated";
BA_ "SignalType" SG_ 1316 FTPP_VirtCtlHdPrkLmpsAvalAuth "ENM";
BA_ "SignalLongName" SG_ 1316 FTPP_VirtCtlHdPrkLmpsAvalAuth "Serial Data 6 Protected : Virtual Control Head and Park Lamps Available Authenticated";
BA_ "SignalType" SG_ 1316 FTPP_HdPrkLmpsCurrSeltnValAuth "ENM";
BA_ "SignalLongName" SG_ 1316 FTPP_HdPrkLmpsCurrSeltnValAuth "Serial Data 6 Protected : Head and Park Lamps Current Selection Value Authenticated";
BA_ "SignalType" SG_ 1316 VMMP_VehMtnMvmtStatAuth "ENM";
BA_ "SignalLongName" SG_ 1316 VMMP_VehMtnMvmtStatAuth "Serial Data 6 Protected : Vehicle Motion Movement State Authenticated";
BA_ "SignalType" SG_ 1316 VKI2P_FobAvlStsAuth "ENM";
BA_ "SignalLongName" SG_ 1316 VKI2P_FobAvlStsAuth "Serial Data 6 Protected : Fob Availability Status Authenticated";
BA_ "SignalLongName" SG_ 1316 SD6P_Filler "Serial Data 6 Protected : Filler";
BA_ "SignalType" SG_ 1316 StrgWhlTchSnsDiagFA "ENM";
BA_ "SignalLongName" SG_ 1316 StrgWhlTchSnsDiagFA "Serial Data 6 Protected : Steering Wheel Touch Sense Diagnostic Fault Active";
BA_ "SignalType" SG_ 1316 FleetDrvrActv "ENM";
BA_ "SignalLongName" SG_ 1316 FleetDrvrActv "Serial Data 6 Protected : Fleet Driver Active";
BA_ "SignalType" SG_ 1316 AuthIntrUserIdDevSts "ENM";
BA_ "SignalLongName" SG_ 1316 AuthIntrUserIdDevSts "Serial Data 6 Protected : Authenticated Interior User Identification Device Status";
BA_ "SignalLongName" SG_ 1316 SD6P_ARC "Serial Data 6 Protected : Alive Rolling Count";
BA_ "SignalLongName" SG_ 713 KMORAI_AllwdTm "Serial Data 7 : Key Missing One Restart Allowed Time";
BA_ "SignalType" SG_ 713 RestrtVehIndOn "ENM";
BA_ "SignalLongName" SG_ 713 RestrtVehIndOn "Serial Data 7 : Restart Vehicle Indication On";
BA_ "SignalType" SG_ 713 PrtctdIdlUnvIndOn "ENM";
BA_ "SignalLongName" SG_ 713 PrtctdIdlUnvIndOn "Serial Data 7 : Protected Idle Unavailable Indication On";
BA_ "SignalType" SG_ 713 PrtctdIdlIndOn "ENM";
BA_ "SignalLongName" SG_ 713 PrtctdIdlIndOn "Serial Data 7 : Protected Idle Indication On";
BA_ "SignalType" SG_ 713 NoKeyFndTryAgnIndOn "ENM";
BA_ "SignalLongName" SG_ 713 NoKeyFndTryAgnIndOn "Serial Data 7 : No Key Found Try Again Indication On";
BA_ "SignalType" SG_ 713 NoKeyDtdMechShfDndIndOn "ENM";
BA_ "SignalLongName" SG_ 713 NoKeyDtdMechShfDndIndOn "Serial Data 7 : No Key Detected Mechanical Shift Denied Indication On";
BA_ "SignalType" SG_ 713 KyIdDevNotPrIO "ENM";
BA_ "SignalLongName" SG_ 713 KyIdDevNotPrIO "Serial Data 7 : Key/Identification Device Not Present Indication On";
BA_ "SignalType" SG_ 713 KeyMisgCkForKeyIndOn "ENM";
BA_ "SignalLongName" SG_ 713 KeyMisgCkForKeyIndOn "Serial Data 7 : Key Missing Check for Key Indication On";
BA_ "SignalType" SG_ 713 KMORAI_IndOn "ENM";
BA_ "SignalLongName" SG_ 713 KMORAI_IndOn "Serial Data 7 : Key Missing One Restart Allowed Indication On";
BA_ "SignalLongName" SG_ 713 SSVI_AutoShtdnTmr "Serial Data 7 : Automatic Shutdown Timer";
BA_ "SignalType" SG_ 713 SSVI_AutoShtdnIO "ENM";
BA_ "SignalLongName" SG_ 713 SSVI_AutoShtdnIO "Serial Data 7 : Automatic Shutdown Indication On";
BA_ "SignalType" SG_ 713 SSVI_AutoShtdnDsbldIO "ENM";
BA_ "SignalLongName" SG_ 713 SSVI_AutoShtdnDsbldIO "Serial Data 7 : Automatic Shutdown Disabled Indication On";
BA_ "SignalType" SG_ 713 SSVI_AppPrkBrkIO "ENM";
BA_ "SignalLongName" SG_ 713 SSVI_AppPrkBrkIO "Serial Data 7 : Apply Park Brake Indication On";
BA_ "SignalType" SG_ 713 SSVI_AppClchPedIO "ENM";
BA_ "SignalLongName" SG_ 713 SSVI_AppClchPedIO "Serial Data 7 : Apply Clutch Pedal Indication On";
BA_ "SignalType" SG_ 713 SSVI_AppBrkPedIO "ENM";
BA_ "SignalLongName" SG_ 713 SSVI_AppBrkPedIO "Serial Data 7 : Apply Brake Pedal Indication On";
BA_ "SignalType" SG_ 713 SSVI_KylsStrtUseXmtrPcktIO "ENM";
BA_ "SignalLongName" SG_ 713 SSVI_KylsStrtUseXmtrPcktIO "Serial Data 7 : Keyless Start Use Transmitter Pocket Indication On";
BA_ "SignalType" SG_ 713 SSVI_KeyMvmtRqrdIndOn "ENM";
BA_ "SignalLongName" SG_ 713 SSVI_KeyMvmtRqrdIndOn "Serial Data 7 : Key Movement Required Indication On";
BA_ "SignalType" SG_ 713 SSVI_ClsEngCmptToStrtVehIO "ENM";
BA_ "SignalLongName" SG_ 713 SSVI_ClsEngCmptToStrtVehIO "Serial Data 7 : Close Engine Compartment To Start Vehicle Indication On";
BA_ "SignalType" SG_ 713 SSVI_ShfToNeutPrssStrtAgnIO "ENM";
BA_ "SignalLongName" SG_ 713 SSVI_ShfToNeutPrssStrtAgnIO "Serial Data 7 : Shift to Neutral and Press Start Again Indication On";
BA_ "SignalType" SG_ 713 SSVI_PrssStrtAgnIO "ENM";
BA_ "SignalLongName" SG_ 713 SSVI_PrssStrtAgnIO "Serial Data 7 : Press Start Again Indication On";
BA_ "SignalType" SG_ 713 SSVI_PrssClchPrssStrtAgnIO "ENM";
BA_ "SignalLongName" SG_ 713 SSVI_PrssClchPrssStrtAgnIO "Serial Data 7 : Press Clutch and Press Start Again Indication On";
BA_ "SignalType" SG_ 713 SSVI_PrssClchBrkForStrtIO "ENM";
BA_ "SignalLongName" SG_ 713 SSVI_PrssClchBrkForStrtIO "Serial Data 7 : Press Clutch and Brake For Start Indication On";
BA_ "SignalType" SG_ 713 SSVI_PrssBtnAgnToTrnEngOffIO "ENM";
BA_ "SignalLongName" SG_ 713 SSVI_PrssBtnAgnToTrnEngOffIO "Serial Data 7 : Press Button Again To Turn Engine Off Indicator On";
BA_ "SignalType" SG_ 713 SSVI_NoRmtDtdPrssClchToRestrtIO "ENM";
BA_ "SignalLongName" SG_ 713 SSVI_NoRmtDtdPrssClchToRestrtIO "Serial Data 7 : No Remote Detected Press Clutch to Restart Indicator On";
BA_ "SignalType" SG_ 713 SSVI_NoRmtDtdPrssBrkToRestrtIO "ENM";
BA_ "SignalLongName" SG_ 713 SSVI_NoRmtDtdPrssBrkToRestrtIO "Serial Data 7 : No Remote Detected Press Brake to Restart Indicator On";
BA_ "SignalType" SG_ 713 SSVI_NoRmtDtdIO "ENM";
BA_ "SignalLongName" SG_ 713 SSVI_NoRmtDtdIO "Serial Data 7 : No Remote Detected Indication On";
BA_ "SignalType" SG_ 713 VhOpgStatUIDDtdPrssBrkToStrtIO "ENM";
BA_ "SignalLongName" SG_ 713 VhOpgStatUIDDtdPrssBrkToStrtIO "Serial Data 7 : Vehicle Operating State UID Detected Press Brake To Start Indication On";
BA_ "SignalType" SG_ 713 VhOpgStatClsDrOrPrssBrkToStrtIO "ENM";
BA_ "SignalLongName" SG_ 713 VhOpgStatClsDrOrPrssBrkToStrtIO "Serial Data 7 : Vehicle Operating State Close Door Or Press Brake To Start Indication On";
BA_ "SignalType" SG_ 713 PPMVehOnExtModeActv "ENM";
BA_ "SignalLongName" SG_ 713 PPMVehOnExtModeActv "Serial Data 7 : Passive Power Mode Vehicle On Extend Mode Active";
BA_ "SignalType" SG_ 713 XmtrSecurConfRqrdIO "ENM";
BA_ "SignalLongName" SG_ 713 XmtrSecurConfRqrdIO "Serial Data 7 : Transmitter Security Confirmation Required Indication On";
BA_ "SignalType" SG_ 713 VehLoBatIndOn "ENM";
BA_ "SignalLongName" SG_ 713 VehLoBatIndOn "Serial Data 7 : Vehicle Low Battery Indication On";
BA_ "SignalType" SG_ 713 VehInNeutShfToDrvIndOn "ENM";
BA_ "SignalLongName" SG_ 713 VehInNeutShfToDrvIndOn "Serial Data 7 : Vehicle In Neutral Shift To Drive Indication On";
BA_ "SignalType" SG_ 713 ShfToNeutRestrtVehIndOn "ENM";
BA_ "SignalLongName" SG_ 713 ShfToNeutRestrtVehIndOn "Serial Data 7 : Shift To Neutral Restart Vehicle Indication On";
BA_ "SignalType" SG_ 713 SSVI_ShfToPrkIO "ENM";
BA_ "SignalLongName" SG_ 713 SSVI_ShfToPrkIO "Serial Data 7 : Shift to Park Indication On";
BA_ "SignalLongName" SG_ 713 SD7_CS "Serial Data 7 : Checksum";
BA_ "SignalType" SG_ 713 PPMExtModeActvEnsBatChrgLvlIO "ENM";
BA_ "SignalLongName" SG_ 713 PPMExtModeActvEnsBatChrgLvlIO "Serial Data 7 : Passive Power Mode Extend Mode Active Ensure Battery Charge Level Indication On";
BA_ "SignalLongName" SG_ 713 SD7_ARC "Serial Data 7 : Alive Rolling Count";
BA_ "SignalType" SG_ 1171 RrStrgModeDispIndReq "ENM";
BA_ "SignalLongName" SG_ 1171 RrStrgModeDispIndReq "Serial Data 80 : Rear Steering Mode Display Indication Request";
BA_ "SignalType" SG_ 1171 RrStrgFlrIndOn "ENM";
BA_ "SignalLongName" SG_ 1171 RrStrgFlrIndOn "Serial Data 80 : Rear Steering Failure Indication On";
BA_ "SignalLongName" SG_ 1171 SD80_CS "Serial Data 80 : Checksum";
BA_ "SignalLongName" SG_ 1171 SD80_ARC "Serial Data 80 : Alive Rolling Count";
BA_ "SignalLongName" SG_ 1336 SrlDat86_PCSM "Serial Data 86 Protected Counter Sync Message";
BA_ "SignalLongName" SG_ 1284 SD86P_MAC "Serial Data 86 Protected : MAC";
BA_ "SignalLongName" SG_ 1284 SD86P_FCnt "Serial Data 86 Protected : Freshness Counter";
BA_ "SignalType" SG_ 1284 DrLckRRStsAuth "ENM";
BA_ "SignalLongName" SG_ 1284 DrLckRRStsAuth "Serial Data 86 Protected : Door Lock Right Rear Status Authenticated";
BA_ "SignalType" SG_ 1284 DrLckRFStsAuth "ENM";
BA_ "SignalLongName" SG_ 1284 DrLckRFStsAuth "Serial Data 86 Protected : Door Lock Right Front Status Authenticated";
BA_ "SignalType" SG_ 1284 DrLckLRStsAuth "ENM";
BA_ "SignalLongName" SG_ 1284 DrLckLRStsAuth "Serial Data 86 Protected : Door Lock Left Rear Status Authenticated";
BA_ "SignalType" SG_ 1284 DrLckLFStsAuth "ENM";
BA_ "SignalLongName" SG_ 1284 DrLckLFStsAuth "Serial Data 86 Protected : Door Lock Left Front Status Authenticated";
BA_ "SignalLongName" SG_ 1284 SD86P_ARC "Serial Data 86 Protected : Alive Rolling Count";
BA_ "SignalLongName" SG_ 1335 SrlDat87_PCSM "Serial Data 87 Protected Counter Sync Message";
BA_ "SignalLongName" SG_ 1283 SD87P_MAC "Serial Data 87 Protected : MAC";
BA_ "SignalLongName" SG_ 1283 SD87P_FCnt "Serial Data 87 Protected : Freshness Counter";
BA_ "SignalLongName" SG_ 1283 PnCActnReqCertfctNumAuth "Serial Data 87 Protected : Plug And Charge Action Request Certificate Number Authenticated";
BA_ "SignalType" SG_ 1283 PnCActnReqCertfctTypAuth "ENM";
BA_ "SignalLongName" SG_ 1283 PnCActnReqCertfctTypAuth "Serial Data 87 Protected : Plug And Charge Action Request Certificate Type Authenticated";
BA_ "SignalType" SG_ 1283 PnCActnReqCertfctOpAuth "ENM";
BA_ "SignalLongName" SG_ 1283 PnCActnReqCertfctOpAuth "Serial Data 87 Protected : Plug And Charge Action Request Certificate Operation Authenticated";
BA_ "SignalLongName" SG_ 1283 SD87P_ARC "Serial Data 87 Protected : Alive Rolling Count";
BA_ "SignalType" SG_ 1283 PnCEnblReqAuth "ENM";
BA_ "SignalLongName" SG_ 1283 PnCEnblReqAuth "Serial Data 87 Protected : Plug And Charge Enable Request Authenticated";
BA_ "SignalLongName" SG_ 640 SrlDat92_PCSM "Serial Data 92 Protected Counter Sync Message";
BA_ "SignalLongName" SG_ 597 SD92P_MAC "Serial Data 92 Protected : MAC";
BA_ "SignalLongName" SG_ 597 SD92P_FCnt "Serial Data 92 Protected : Freshness Counter";
BA_ "SignalLongName" SG_ 597 VirtKeyMblDevDgtlKeyIdxAuth "Serial Data 92 Protected : Virtual Key Mobile Device Digital Key Index Authenticated";
BA_ "SignalType" SG_ 597 SuprRmtPrkVirtKeyPrkCmdAuth "ENM";
BA_ "SignalLongName" SG_ 597 SuprRmtPrkVirtKeyPrkCmdAuth "Serial Data 92 Protected : Supervised Remote Parking Virtual Key Parking Command Authenticated";
BA_ "SignalType" SG_ 597 SuprRmtPrkVirtKeyEntlmtStsAuth "ENM";
BA_ "SignalLongName" SG_ 597 SuprRmtPrkVirtKeyEntlmtStsAuth "Serial Data 92 Protected : Supervised Remote Parking Virtual Key Entitlement Status Authenticated";
BA_ "SignalLongName" SG_ 597 VirtKeyMblDevLocDirAuth "Serial Data 92 Protected : Virtual Key Mobile Device Location Direction Authenticated";
BA_ "SignalLongName" SG_ 597 VirtKeyMblDevLocDistAuth "Serial Data 92 Protected : Virtual Key Mobile Device Location Distance Authenticated";
BA_ "SignalLongName" SG_ 597 SD92P_ARC "Serial Data 92 Protected : Alive Rolling Count";
BA_ "SignalType" SG_ 597 VirtKeyMblDevLocZnAuth "ENM";
BA_ "SignalLongName" SG_ 597 VirtKeyMblDevLocZnAuth "Serial Data 92 Protected : Virtual Key Mobile Device Location Zone Authenticated";
BA_ "SignalLongName" SG_ 1403 SysPwrMode_PCSM "System Power Mode Protected Counter Sync Message";
BA_ "SignalLongName" SG_ 878 SPMP_MAC "System Power Mode Protected : MAC";
BA_ "SignalLongName" SG_ 878 SPMP_FCnt "System Power Mode Protected : Freshness Counter";
BA_ "SignalLongName" SG_ 878 RIP_RmtVehStrtBkupTmAuth "System Power Mode Protected : Remote Vehicle Start Backup Time Authenticated";
BA_ "SignalType" SG_ 878 RIP_PreRelAllwdAuth "ENM";
BA_ "SignalLongName" SG_ 878 RIP_PreRelAllwdAuth "System Power Mode Protected : Pre-Release Allowed Authenticated";
BA_ "SignalType" SG_ 878 RIP_ElecStrgColUnlckAllwdAuth "ENM";
BA_ "SignalLongName" SG_ 878 RIP_ElecStrgColUnlckAllwdAuth "System Power Mode Protected : Electric Steering Column Unlock Allowed Authenticated";
BA_ "SignalType" SG_ 878 BGI1P_RmtVehStrtReqAuth "ENM";
BA_ "SignalLongName" SG_ 878 BGI1P_RmtVehStrtReqAuth "System Power Mode Protected : Remote Vehicle Start Request Authenticated";
BA_ "SignalType" SG_ 878 BGI1P_RmtStrtStsAuth "ENM";
BA_ "SignalLongName" SG_ 878 BGI1P_RmtStrtStsAuth "System Power Mode Protected : Remote Vehicle Start Status Authenticated";
BA_ "SignalType" SG_ 878 SPMP_PriRunCrnkCmdActvAuth "ENM";
BA_ "SignalLongName" SG_ 878 SPMP_PriRunCrnkCmdActvAuth "System Power Mode Protected : Primary Run Crank Command Active Authenticated";
BA_ "SignalLongName" SG_ 878 SPMP_PV "System Power Mode Protected : Protection Value";
BA_ "SignalType" SG_ 878 RIP_StrtStopIgnSwPrssdAuth "ENM";
BA_ "SignalLongName" SG_ 878 RIP_StrtStopIgnSwPrssdAuth "System Power Mode Protected : Start/Stop Ignition Switch Pressed Authenticated";
BA_ "SignalType" SG_ 878 RIP_StrtStopIgnSwPrssdAuth_Inv "ENM";
BA_ "SignalLongName" SG_ 878 RIP_StrtStopIgnSwPrssdAuth_Inv "System Power Mode Protected : Start/Stop Ignition Switch Pressed Authenticated Invalid";
BA_ "SignalLongName" SG_ 878 SPMP_ARC "System Power Mode Protected : Alive Rolling Count";
BA_ "SignalType" SG_ 878 SPMP_SysPwrModeAuth_Inv "ENM";
BA_ "SignalLongName" SG_ 878 SPMP_SysPwrModeAuth_Inv "System Power Mode Protected : System Power Mode Authenticated Invalid";
BA_ "SignalType" SG_ 878 SPMP_SysPwrModeAuth "ENM";
BA_ "SignalLongName" SG_ 878 SPMP_SysPwrModeAuth "System Power Mode Protected : System Power Mode Authenticated";
BA_ "SignalType" SG_ 878 SPMP_PriRunCrnkCmdActvAuth_Inv "ENM";
BA_ "SignalLongName" SG_ 878 SPMP_PriRunCrnkCmdActvAuth_Inv "System Power Mode Protected : Primary Run Crank Command Active Authenticated Invalid";
BA_ "SignalLongName" SG_ 878 SPMP_Filler "System Power Mode Protected : Filler";
BA_ "SignalLongName" SG_ 1358 TlmGPSDateSrc_PCSM "Telematics GPS Date Source Protected Counter Sync Message";
BA_ "SignalLongName" SG_ 1299 TGPSDSP_MAC "Telematics GPS Date Source Protected : MAC";
BA_ "SignalLongName" SG_ 1299 TGPSDSP_FCnt "Telematics GPS Date Source Protected : Freshness Counter";
BA_ "SignalType" SG_ 1299 TGPSDSP_UTCMonthAuth "ENM";
BA_ "SignalLongName" SG_ 1299 TGPSDSP_UTCMonthAuth "Telematics GPS Date Source Protected : UTC Month Authenticated";
BA_ "SignalType" SG_ 1299 TGPSDSP_UTCDyAuth_Inv "ENM";
BA_ "SignalLongName" SG_ 1299 TGPSDSP_UTCDyAuth_Inv "Telematics GPS Date Source Protected : UTC Day Authenticated Invalid";
BA_ "SignalLongName" SG_ 1299 TGPSDSP_UTCDyAuth "Telematics GPS Date Source Protected : UTC Day Authenticated";
BA_ "SignalLongName" SG_ 1299 TGPSDSP_UTCYrAuth "Telematics GPS Date Source Protected : UTC Year Authenticated";
BA_ "SignalType" SG_ 1299 TGPSDSP_UTCMonthAuth_Inv "ENM";
BA_ "SignalLongName" SG_ 1299 TGPSDSP_UTCMonthAuth_Inv "Telematics GPS Date Source Protected : UTC Month Authenticated Invalid";
BA_ "SignalType" SG_ 1299 TGPSDSP_DateSrcAuth "ENM";
BA_ "SignalLongName" SG_ 1299 TGPSDSP_DateSrcAuth "Telematics GPS Date Source Protected : Date Source Authenticated";
BA_ "SignalLongName" SG_ 1299 TGPSDSP_ARC "Telematics GPS Date Source Protected : Alive Rolling Count";
BA_ "SignalType" SG_ 1299 TGPSDSP_UTCYrAuth_Inv "ENM";
BA_ "SignalLongName" SG_ 1299 TGPSDSP_UTCYrAuth_Inv "Telematics GPS Date Source Protected : UTC Year Authenticated Invalid";
BA_ "SignalType" SG_ 1299 TGPSDSP_DateSrcAuth_Inv "ENM";
BA_ "SignalLongName" SG_ 1299 TGPSDSP_DateSrcAuth_Inv "Telematics GPS Date Source Protected : Date Source Authenticated Invalid";
BA_ "SignalLongName" SG_ 1357 TlmGPSTmSrc_PCSM "Telematics GPS Time Source Protected Counter Sync Message";
BA_ "SignalLongName" SG_ 865 TGPSTSP_MAC "Telematics GPS Time Source Protected : MAC";
BA_ "SignalLongName" SG_ 865 TGPSTSP_FCnt "Telematics GPS Time Source Protected : Freshness Counter";
BA_ "SignalLongName" SG_ 865 TGPSTSP_UTCHrsAuth "Telematics GPS Time Source Protected : UTC Hours Authenticated";
BA_ "SignalType" SG_ 865 TGPSTSP_TmSrcAuth_Inv "ENM";
BA_ "SignalLongName" SG_ 865 TGPSTSP_TmSrcAuth_Inv "Telematics GPS Time Source Protected : Time Source Authenticated Invalid";
BA_ "SignalType" SG_ 865 TGPSTSP_TmSrcAuth "ENM";
BA_ "SignalLongName" SG_ 865 TGPSTSP_TmSrcAuth "Telematics GPS Time Source Protected : Time Source Authenticated";
BA_ "SignalLongName" SG_ 865 TGPSTSP_UTCMinsAuth "Telematics GPS Time Source Protected : UTC Minutes Authenticated";
BA_ "SignalType" SG_ 865 TGPSTSP_UTCHrsAuth_Inv "ENM";
BA_ "SignalLongName" SG_ 865 TGPSTSP_UTCHrsAuth_Inv "Telematics GPS Time Source Protected : UTC Hours Authenticated Invalid";
BA_ "SignalType" SG_ 865 TGPSTSP_UTCSecsAuth_Inv "ENM";
BA_ "SignalLongName" SG_ 865 TGPSTSP_UTCSecsAuth_Inv "Telematics GPS Time Source Protected : UTC Seconds Authenticated Invalid";
BA_ "SignalLongName" SG_ 865 TGPSTSP_UTCSecsAuth "Telematics GPS Time Source Protected : UTC Seconds Authenticated";
BA_ "SignalType" SG_ 865 TGPSTSP_UTCMinsAuth_Inv "ENM";
BA_ "SignalLongName" SG_ 865 TGPSTSP_UTCMinsAuth_Inv "Telematics GPS Time Source Protected : UTC Minutes Authenticated Invalid";
BA_ "SignalLongName" SG_ 865 TGPSTSP_ARC "Telematics GPS Time Source Protected : Alive Rolling Count";
BA_ "SignalLongName" SG_ 601 SD72P_MAC "Serial Data 72 Protected : MAC";
BA_ "SignalLongName" SG_ 601 SD72P_FCnt "Serial Data 72 Protected : Freshness Counter";
BA_ "SignalLongName" SG_ 601 DgtlKeyReqIdfrAuth "Serial Data 72 Protected : Digital Key Request Identifier Authenticated";
BA_ "SignalType" SG_ 601 DgtlKeyMgmtReqAuth "ENM";
BA_ "SignalLongName" SG_ 601 DgtlKeyMgmtReqAuth "Serial Data 72 Protected : Digital Key Management Request Authenticated";
BA_ "SignalLongName" SG_ 592 SD73P_MAC "Serial Data 73 Protected : MAC";
BA_ "SignalLongName" SG_ 592 SD73P_FCnt "Serial Data 73 Protected : Freshness Counter";
BA_ "SignalLongName" SG_ 592 DgtlKeyRespIdfrAuth "Serial Data 73 Protected : Digital Key Response Identifier Authenticated";
BA_ "SignalType" SG_ 592 DgtlKeyMgmtRespAuth "ENM";
BA_ "SignalLongName" SG_ 592 DgtlKeyMgmtRespAuth "Serial Data 73 Protected : Digital Key Management Response Authenticated";
BA_ "SignalLongName" SG_ 599 SD74P_MAC "Serial Data 74 Protected : MAC";
BA_ "SignalLongName" SG_ 599 SD74P_FCnt "Serial Data 74 Protected : Freshness Counter";
BA_ "SignalLongName" SG_ 599 DgtlKeyPwVrfrAuth "Serial Data 74 Protected : Digital Key Password Verifier Authenticated";
BA_ "SignalLongName" SG_ 1909 IPC_LCMFileDat "IPC_LCMFileData";
BA_ "SignalLongName" SG_ 42 MFC_LCMFileDat "Multi Function Controller - License Compliance Material File Data";
BA_ "SignalLongName" SG_ 1971 PLCM_LCMFileDat "Power Line Communication Module - License Compliance Material File Data";
BA_ "SignalLongName" SG_ 1920 SD136P_MAC "Serial Data 136 Protected : MAC";
BA_ "SignalLongName" SG_ 1920 SD136P_FCnt "Serial Data 136 Protected : Freshness Counter";
BA_ "SignalLongName" SG_ 1920 VirtKeyCldUserAuthInfo "Serial Data 136 Protected : Virtual Key Cloud User Authentication Information";
BA_ "SignalLongName" SG_ 1922 SD137P_MAC "Serial Data 137 Protected : MAC";
BA_ "SignalLongName" SG_ 1922 SD137P_FCnt "Serial Data 137 Protected : Freshness Counter";
BA_ "SignalLongName" SG_ 1922 VirtKeyCldUserIdDat1 "Serial Data 137 Protected : Virtual Key Cloud User Identification Data 1";
BA_ "SignalLongName" SG_ 1922 VirtKeyCldUserIdDat2 "Serial Data 137 Protected : Virtual Key Cloud User Identification Data 2";
BA_ "SignalLongName" SG_ 1922 VirtKeyCldUserIdDat3 "Serial Data 137 Protected : Virtual Key Cloud User Identification Data 3";
BA_ "SignalLongName" SG_ 1922 VirtKeyCldUserIdDat4 "Serial Data 137 Protected : Virtual Key Cloud User Identification Data 4";
BA_ "SignalLongName" SG_ 1922 VirtKeyCldUserIdDat5 "Serial Data 137 Protected : Virtual Key Cloud User Identification Data 5";
BA_ "SignalLongName" SG_ 1922 VirtKeyCldUserIdDat6 "Serial Data 137 Protected : Virtual Key Cloud User Identification Data 6";
BA_ "SignalLongName" SG_ 1922 VirtKeyCldUserIdDat7 "Serial Data 137 Protected : Virtual Key Cloud User Identification Data 7";
BA_ "SignalLongName" SG_ 1922 VirtKeyCldUserIdDat8 "Serial Data 137 Protected : Virtual Key Cloud User Identification Data 8";
BA_ "SignalLongName" SG_ 1922 VirtKeyUserInfo1 "Serial Data 137 Protected : Virtual Key User Information 1";
BA_ "SignalLongName" SG_ 1922 VirtKeyUserInfo2 "Serial Data 137 Protected : Virtual Key User Information 2";
BA_ "SignalLongName" SG_ 1922 VirtKeyUserInfo3 "Serial Data 137 Protected : Virtual Key User Information 3";
BA_ "SignalLongName" SG_ 1922 VirtKeyUserInfo4 "Serial Data 137 Protected : Virtual Key User Information 4";
BA_ "SignalLongName" SG_ 1922 VirtKeyUserInfo5 "Serial Data 137 Protected : Virtual Key User Information 5";
BA_ "SignalLongName" SG_ 1922 VirtKeyUserInfo6 "Serial Data 137 Protected : Virtual Key User Information 6";
BA_ "SignalLongName" SG_ 1922 VirtKeyUserInfo7 "Serial Data 137 Protected : Virtual Key User Information 7";
BA_ "SignalLongName" SG_ 1928 SD275P_MAC "Serial Data 275 Protected : MAC";
BA_ "SignalLongName" SG_ 1928 SD275P_FCnt "Serial Data 275 Protected : Freshness Counter";
BA_ "SignalLongName" SG_ 1928 ChrgCommCtlrMACAddr "Serial Data 275 Protected : Charging Communication Controller MAC Address";
BA_ "SignalType" SG_ 1928 ChrgCommCtlrMACAddr_DuD "ENM";
BA_ "SignalLongName" SG_ 1928 ChrgCommCtlrMACAddr_DuD "Serial Data 275 Protected : Charging Communication Controller MAC Address Don't Use Data";
BA_ "SignalLongName" SG_ 125 SD321P_MAC "Serial Data 321 Protected : MAC";
BA_ "SignalLongName" SG_ 125 SD321P_FCnt "Serial Data 321 Protected : Freshness Counter";
BA_ "SignalLongName" SG_ 125 FlxblChrgBrdgItrsnDtnSysNtfn "Serial Data 321 Protected : Flexible Charge Bridge Intrusion Detection System Notification";
BA_ "SignalLongName" SG_ 948 TCP_LCMFileDat "Telematics - License Compliance Material File Data";
BA_ "SignalLongName" SG_ 717 VirtKeyLngTrmKeyAtstn "Virtual Key - Long Term Key Attestation";
BA_ "SignalLongName" SG_ 715 VirtKeyLngTrmKey "Virtual Key - Long Term Key";
BA_ "SignalLongName" SG_ 950 WCM_LCMFileDat "Wireless Charger Module - License Compliance Material File Data";
BA_ "SignalLongName" SG_ 1254 UnlckKeyStorCrptoDat1 "Unlock Key Store Cryptographic Data 1";
BA_ "SignalLongName" SG_ 1812 UnlckKeyStorCrptoDat2 "Unlock Key Store Cryptographic Data 2";
BA_ "SignalLongName" SG_ 1179 VehIdNmDig10_17 "Vehicle Identification Number Digits 10-17";
BA_ "SignalLongName" SG_ 1887 VehIdNmDig2_9 "Vehicle Identification Number Digits 2-9";
BA_ "SignalLongName" SG_ 890 VehIntgrtnCtlModInfo1_PCSM "Vehicle Integration Control Module Information 1 Protected Counter Sync Message";
BA_ "SignalLongName" SG_ 621 VICMI1P_MAC "Vehicle Integration Control Module Information 1 Protected : MAC";
BA_ "SignalLongName" SG_ 621 VICMI1P_FCnt "Vehicle Integration Control Module Information 1 Protected : Freshness Counter";
BA_ "SignalType" SG_ 621 VICMI1P_AutoDrvShfSysStsPriAuth "ENM";
BA_ "SignalLongName" SG_ 621 VICMI1P_AutoDrvShfSysStsPriAuth "Vehicle Integration Control Module Information 1 Protected : Autonomous Driving Shift System Status Primary Authenticated";
BA_ "SignalType" SG_ 621 HiVltgChrgCommEnblReq "ENM";
BA_ "SignalLongName" SG_ 621 HiVltgChrgCommEnblReq "Vehicle Integration Control Module Information 1 Protected : High Voltage Charging Communication Enable Request";
BA_ "SignalType" SG_ 621 VICMI1P_ADShfSysHlthStsPriAuth "ENM";
BA_ "SignalLongName" SG_ 621 VICMI1P_ADShfSysHlthStsPriAuth "Vehicle Integration Control Module Information 1 Protected : Autonomous Driving Shift System Health Status Primary Authenticated";
BA_ "SignalLongName" SG_ 621 VICMI1P_Filler "Vehicle Integration Control Module Information 1 Protected : Filler";
BA_ "SignalLongName" SG_ 621 VICMI1P_ARC "Vehicle Integration Control Module Information 1 Protected : Alive Rolling Count";
BA_ "SignalType" SG_ 621 VICMI1P_AuxPwrModStsAuth "ENM";
BA_ "SignalLongName" SG_ 621 VICMI1P_AuxPwrModStsAuth "Vehicle Integration Control Module Information 1 Protected : Auxiliary Power Module Status Authenticated";
BA_ "SignalLongName" SG_ 1370 VehOdoDispVal_PCSM "Vehicle Odometer Display Value Protected Counter Sync Message";
BA_ "SignalLongName" SG_ 1298 VODVP_MAC "Vehicle Odometer Display Value Protected : MAC";
BA_ "SignalLongName" SG_ 1298 VODVP_FCnt "Vehicle Odometer Display Value Protected : Freshness Counter";
BA_ "SignalLongName" SG_ 1298 VODVP_VehOdoDispValAuth "Vehicle Odometer Display Value Protected : Vehicle Odometer Display Value Authenticated";
BA_ "SignalLongName" SG_ 1298 VODVP_Filler "Vehicle Odometer Display Value Protected : Filler";
BA_ "SignalType" SG_ 1298 UpftrRmtVehStrtReqd "ENM";
BA_ "SignalLongName" SG_ 1298 UpftrRmtVehStrtReqd "Vehicle Odometer Display Value Protected : Upfitter Remote Vehicle Start Requested";
BA_ "SignalType" SG_ 1298 UpftrSnwPlwLoBmDsblReqd "ENM";
BA_ "SignalLongName" SG_ 1298 UpftrSnwPlwLoBmDsblReqd "Vehicle Odometer Display Value Protected : Upfitter Snow Plow Low Beam Disable Requested";
BA_ "SignalType" SG_ 1298 VODVP_VehOdoDispValAuth_Inv "ENM";
BA_ "SignalLongName" SG_ 1298 VODVP_VehOdoDispValAuth_Inv "Vehicle Odometer Display Value Protected : Vehicle Odometer Display Value Authenticated Invalid";
BA_ "SignalLongName" SG_ 1356 VehOdoStrdDispVal_PCSM "Vehicle Odometer Stored Display Value Protected Counter Sync Message";
BA_ "SignalLongName" SG_ 1297 VOSDVP_MAC "Vehicle Odometer Stored Display Value Protected : MAC";
BA_ "SignalLongName" SG_ 1297 VOSDVP_FCnt "Vehicle Odometer Stored Display Value Protected : Freshness Counter";
BA_ "SignalLongName" SG_ 1297 VOSDVP_VehOdoStrdDispValAuth "Vehicle Odometer Stored Display Value Protected : Vehicle Odometer Stored Display Value Authenticated";
BA_ "SignalLongName" SG_ 1297 VOSDVP_Filler "Vehicle Odometer Stored Display Value Protected : Filler";
BA_ "SignalType" SG_ 1297 VOSDVP_VehOdoStrdDspValAuth_Inv "ENM";
BA_ "SignalLongName" SG_ 1297 VOSDVP_VehOdoStrdDspValAuth_Inv "Vehicle Odometer Stored Display Value Protected : Vehicle Odometer Stored Display Value Authenticated Invalid";
BA_ "SignalLongName" SG_ 1402 VehSpdAvgDrvn_PCSM "Vehicle Speed Average Driven Protected Counter Sync Message";
BA_ "SignalLongName" SG_ 614 VSADP_MAC "Vehicle Speed Average Driven Protected : MAC";
BA_ "SignalLongName" SG_ 614 VSADP_FCnt "Vehicle Speed Average Driven Protected : Freshness Counter";
BA_ "SignalLongName" SG_ 614 VSADP_VehSpdAvgDrvnAuth "Vehicle Speed Average Driven Protected : Vehicle Speed Average Driven Authenticated";
BA_ "SignalType" SG_ 614 VSADP_RdcdPwrIndOnAuth "ENM";
BA_ "SignalLongName" SG_ 614 VSADP_RdcdPwrIndOnAuth "Vehicle Speed Average Driven Protected : Reduced Power Indication On Authenticated";
BA_ "SignalType" SG_ 614 VSADP_FuelModeStsAuth "ENM";
BA_ "SignalLongName" SG_ 614 VSADP_FuelModeStsAuth "Vehicle Speed Average Driven Protected : Fuel Mode Status Authenticated";
BA_ "SignalType" SG_ 614 EngEmsRltMlfIndRq "ENM";
BA_ "SignalLongName" SG_ 614 EngEmsRltMlfIndRq "Vehicle Speed Average Driven Protected : Engine Emissions Related Malfunction Indication Request";
BA_ "SignalLongName" SG_ 614 VSADP_ARC "Vehicle Speed Average Driven Protected : Alive Rolling Count";
BA_ "SignalType" SG_ 614 VSADP_VehSpdAvgDrvnSrcAuth "ENM";
BA_ "SignalLongName" SG_ 614 VSADP_VehSpdAvgDrvnSrcAuth "Vehicle Speed Average Driven Protected : Vehicle Speed Average Driven Source Authenticated";
BA_ "SignalType" SG_ 614 VSADP_VehSpdAvgDrvnAuth_Inv "ENM";
BA_ "SignalLongName" SG_ 614 VSADP_VehSpdAvgDrvnAuth_Inv "Vehicle Speed Average Driven Protected : Vehicle Speed Average Driven Authenticated Invalid";
BA_ "SignalLongName" SG_ 614 VSADP_Filler "Vehicle Speed Average Driven Protected : Filler";
BA_ "SignalLongName" SG_ 1303 VPMGI1P_MAC "Video Processing Module General Information 1 Protected : MAC";
BA_ "SignalLongName" SG_ 1303 VPMGI1P_FCnt "Video Processing Module General Information 1 Protected : Freshness Counter";
BA_ "SignalLongName" SG_ 1303 VPMGI1P_Filler "Video Processing Module General Information 1 Protected : Filler";
BA_ "SignalLongName" SG_ 1303 VPMGI1P_ARC "Video Processing Module General Information 1 Protected : Alive Rolling Count";
BA_ "SignalType" SG_ 1303 VPMGI1P_ITAux2CamConctStsAuth "ENM";
BA_ "SignalLongName" SG_ 1303 VPMGI1P_ITAux2CamConctStsAuth "Video Processing Module General Information 1 Protected : Invisible Trailer Aux2 Camera Connection Status Authenticated";
BA_ "SignalType" SG_ 1303 VPMGI1P_ITAux1CamConctStsAuth "ENM";
BA_ "SignalLongName" SG_ 1303 VPMGI1P_ITAux1CamConctStsAuth "Video Processing Module General Information 1 Protected : Invisible Trailer Aux1 Camera Connection Status Authenticated";
VAL_ 1095 VSEMOpModeCurrSetVal 0 "Time" 1 "State of Charge" ;
VAL_ 1095 VSEMActv 0 "FALSE" 1 "TRUE" ;
VAL_ 1094 VSEMNormShtdnWrnIndOn 0 "FALSE" 1 "TRUE" ;
VAL_ 1094 VSEMFltdShtdnWrnIndOn 0 "FALSE" 1 "TRUE" ;
VAL_ 1094 CbnCondngSftyTVSEMAlrtIndOn 0 "FALSE" 1 "TRUE" ;
VAL_ 1094 CbnCondngFlrIndOn 0 "FALSE" 1 "TRUE" ;
VAL_ 1093 VSEMOpVirtCtlReq 0 "No Request" 1 "Initiate SOC Extension" 2 "Initiate Time Extension" 3 "End Extension" 4 "Request to Update Extension" 5 "Request to Update Extension Cancelled" ;
VAL_ 1093 ChrgPortDrClsrVirtCtlReq 0 "No Action" 1 "Open" 2 "Close" ;
VAL_ 1093 ChrgCommGtwayChrgAuthSts 0 "Unknown" 1 "Pending" 2 "Enable" 3 "Disable" ;
VAL_ 1093 ChrgCommGtwayCommPrtclTyp 0 "Unknown" 1 "None" 2 "DIN" 3 "ISO15118" ;
VAL_ 1093 VSEMVehAlrtDsmssed 0 "FALSE" 1 "TRUE" ;
VAL_ 1093 VSEMClmCtlsUnlckReqd 0 "FALSE" 1 "TRUE" ;
VAL_ 756 OccptLtBehindeCallReqd 0 "Unknown" 1 "Level 1 Request" 2 "Level 2 Request" 3 "Data Not Available" ;
VAL_ 1990 ODSSecFncSts_Inv 0 "FALSE" 1 "TRUE" ;
VAL_ 1990 ODSSecFncSts 0 "Unavailable" 1 "Functional" 2 "Failed" 3 "Degraded Performance" 4 "External Fault" 5 "Blocked" 6 "Exceeded Operational Limits" 7 "Interference Detected" ;
VAL_ 1990 ODSPriFncSts_Inv 0 "FALSE" 1 "TRUE" ;
VAL_ 1990 ODSPriFncSts 0 "Unavailable" 1 "Functional" 2 "Failed" 3 "Degraded Performance" 4 "External Fault" 5 "Blocked" 6 "Exceeded Operational Limits" 7 "Interference Detected" ;
VAL_ 1990 ODSFrtLtFtwlPstnOcpd_Inv 0 "FALSE" 1 "TRUE" ;
VAL_ 1990 ODSFrtLtFtwlPstnOcpd 0 "FALSE" 1 "TRUE" ;
VAL_ 1990 ODSFrtRtPstnOcpd_Inv 0 "FALSE" 1 "TRUE" ;
VAL_ 1990 ODSFrtRtPstnOcpd 0 "FALSE" 1 "TRUE" ;
VAL_ 1990 ODSFrtCntrPstnOcpd_Inv 0 "FALSE" 1 "TRUE" ;
VAL_ 1990 ODSFrtCntrPstnOcpd 0 "FALSE" 1 "TRUE" ;
VAL_ 1990 ODSFrtLtPstnOcpd_Inv 0 "FALSE" 1 "TRUE" ;
VAL_ 1990 ODSFrtLtPstnOcpd 0 "FALSE" 1 "TRUE" ;
VAL_ 1990 ODSFrtRtFtwlPstnOcpd_Inv 0 "FALSE" 1 "TRUE" ;
VAL_ 1990 ODSFrtRtFtwlPstnOcpd 0 "FALSE" 1 "TRUE" ;
VAL_ 1990 ODSFrtCntFtwlPstnOcpd_Inv 0 "FALSE" 1 "TRUE" ;
VAL_ 1990 ODSFrtCntFtwlPstnOcpd 0 "FALSE" 1 "TRUE" ;
VAL_ 1081 ODSSecRwLtFtwlPstOcpd_Inv 0 "FALSE" 1 "TRUE" ;
VAL_ 1081 ODSSecRwLtFtwlPstOcpd 0 "FALSE" 1 "TRUE" ;
VAL_ 1081 ODSSecRowRtPstnOcpd_Inv 0 "FALSE" 1 "TRUE" ;
VAL_ 1081 ODSSecRowRtPstnOcpd 0 "FALSE" 1 "TRUE" ;
VAL_ 1081 ODSSecRowCntPstnOcpd_Inv 0 "FALSE" 1 "TRUE" ;
VAL_ 1081 ODSSecRowCntPstnOcpd 0 "FALSE" 1 "TRUE" ;
VAL_ 1081 ODSSecRowLtPstnOcpd_Inv 0 "FALSE" 1 "TRUE" ;
VAL_ 1081 ODSSecRowLtPstnOcpd 0 "FALSE" 1 "TRUE" ;
VAL_ 1081 ODSThrdRwCntrPstnOcpd_Inv 0 "FALSE" 1 "TRUE" ;
VAL_ 1081 ODSThrdRwCntrPstnOcpd 0 "FALSE" 1 "TRUE" ;
VAL_ 1081 ODSThrdRowLtPstnOcpd_Inv 0 "FALSE" 1 "TRUE" ;
VAL_ 1081 ODSThrdRowLtPstnOcpd 0 "FALSE" 1 "TRUE" ;
VAL_ 1081 ODSSecRwRtFtwlPstOcpd_Inv 0 "FALSE" 1 "TRUE" ;
VAL_ 1081 ODSSecRwRtFtwlPstOcpd 0 "FALSE" 1 "TRUE" ;
VAL_ 1081 ODSSecRwCntFtwlPstOcpd_Inv 0 "FALSE" 1 "TRUE" ;
VAL_ 1081 ODSSecRwCntFtwlPstOcpd 0 "FALSE" 1 "TRUE" ;
VAL_ 1081 ODSThrdRwRtFtwlPstOcpd_Inv 0 "FALSE" 1 "TRUE" ;
VAL_ 1081 ODSThrdRwRtFtwlPstOcpd 0 "FALSE" 1 "TRUE" ;
VAL_ 1081 ODSThrdRwCntFtlPstOcpd_Inv 0 "FALSE" 1 "TRUE" ;
VAL_ 1081 ODSThrdRwCntFtlPstOcpd 0 "FALSE" 1 "TRUE" ;
VAL_ 1081 ODSThrdRwLtFtwlPstOcpd_Inv 0 "FALSE" 1 "TRUE" ;
VAL_ 1081 ODSThrdRwLtFtwlPstOcpd 0 "FALSE" 1 "TRUE" ;
VAL_ 1081 ODSThrdRowRtPstnOcpd_Inv 0 "FALSE" 1 "TRUE" ;
VAL_ 1081 ODSThrdRowRtPstnOcpd 0 "FALSE" 1 "TRUE" ;
VAL_ 1081 ODSCrgRtPstnOcpd_Inv 0 "FALSE" 1 "TRUE" ;
VAL_ 1081 ODSCrgRtPstnOcpd 0 "FALSE" 1 "TRUE" ;
VAL_ 1081 ODSCrgCntrPstnOcpd_Inv 0 "FALSE" 1 "TRUE" ;
VAL_ 1081 ODSCrgCntrPstnOcpd 0 "FALSE" 1 "TRUE" ;
VAL_ 1081 ODSCrgLtPstnOcpd_Inv 0 "FALSE" 1 "TRUE" ;
VAL_ 1081 ODSCrgLtPstnOcpd 0 "FALSE" 1 "TRUE" ;
VAL_ 549 ChrgStnEngyXferDir 0 "Charging" 1 "Discharging" ;
VAL_ 881 ASDRP_LnCntrWrnExtdIndReqAuth 0 "No Indication" 1 "Can Not See Lanes" 2 "Tight Curve" 3 "Freeway Ends" 4 "Construction" 5 "Excessive Speed" 6 "Vehicles Proximity" 7 "Unavailable" 8 "Attention Unknown" 9 "Due to Weather" 10 "Take Steering" 11 "Take Vehicle Control" 12 "Service Driver Assist System" 13 "Lane Following Locked Out" 14 "Reserved 1" 15 "Lane Ending" 16 "Exit Lane" 17 "GM Authority" 18 "Vehicle Setting" 19 "Adaptive Cruise" 20 "Controlled Access" 21 "Driver Attention Off Road" 22 "GPS Unavailable" 23 "Driver Action" 24 "Vehicle Center" 25 "Sensor Impaired" 26 "Opening Left" 27 "Opening Right" 28 "Changing Left" 29 "Changing Right" 30 "Complete Left" 31 "Complete Right" 32 "Unable Left" 33 "Unable Right" 34 "Cancelled Left" 35 "Cancelled Right" 36 "Timed Out Left" 37 "Timed Out Right" 38 "Trailer Narrow Lane" 39 "Trailer Dimensions" 40 "Trailer Braking" 41 "Trailer Overloaded" 42 "Trailer Stability" 43 "Subscription Required" 44 "Roundabout" 45 "Dirt Road" 46 "Parking Lot" 47 "Refer to Ultra Cruise App" 48 "GM Backoffice Disabled" 49 "APA Active" 50 "Seatbelt Not Fastened" 51 "Teen Driver Active" 52 "Toll Booth Ahead" 53 "End of Route" 54 "End of Route Approaching" 55 "Toll Booth Approaching" 56 "Ride Height Out of Range" 57 "Snow Mode" 58 "Road Geometry Not Supported" 59 "No Lead Vehicle" 60 "Approaching Speed Threshold" 61 "Driver Follow Route Escalation" 62 "Change Lane Route Right" 63 "Change Lane Route Left" ;
VAL_ 881 ASDRP_LnCntrCtlIndReqAuth 0 "Indication Off" 1 "White Indicator" 2 "Green Indicator" 3 "Yellow Indicator" 4 "Red Indicator" 5 "Blue Indicator" ;
VAL_ 881 ACGIP_SrrndVsnRLSModeCmdAuth 0 "Not Reporting Lane Data" 1 "Reporting Lane Data" ;
VAL_ 881 ACGIP_LnFllwFltIndcdAtBrkEnAuth 0 "FALSE" 1 "TRUE" ;
VAL_ 881 HMIR1P_LnFllwgLHSChEvntStatAuth 0 "No Action" 1 "Active" 2 "Cancel Chime" ;
VAL_ 881 HMIR1P_LnFllwgGenChEvntStatAuth 0 "No Action" 1 "Active" 2 "Cancel Chime" ;
VAL_ 881 ASTIP_LnCntrVehStopdAuth 0 "FALSE" 1 "TRUE" ;
VAL_ 881 ADASXferOfCtlIndReq 0 "No Indication" 1 "Long Auto Resume" 2 "Driver Initiated Motion Required" 3 "Driver Initiated Steering Required" 4 "Non-Urgent" 5 "Urgent" 6 "Non-Responsive Driver" 7 "Non-Urgent Follow Route" ;
VAL_ 881 HMIR1P_LnFllwgRHSChEvntStatAuth 0 "No Action" 1 "Active" 2 "Cancel Chime" ;
VAL_ 622 RrStrgModeVirtCtlSwReq 0 "FALSE" 1 "TRUE" ;
VAL_ 622 HMIGI2P_LnFllwgInterFltDtdAuth 0 "FALSE" 1 "TRUE" ;
VAL_ 622 HMIGI2P_IPCFlrIndOnAuth 0 "FALSE" 1 "TRUE" ;
VAL_ 622 HMIGI1P_TrlrBrkDispActvAuth_DuD 0 "FALSE" 1 "TRUE" ;
VAL_ 622 HMIGI1P_TrlrBrkDispActvAuth 0 "FALSE" 1 "TRUE" ;
VAL_ 622 HMIGI1P_EnvModPrsntRspdr4Auth 0 "FALSE" 1 "TRUE" ;
VAL_ 1319 TSGI1P_EnhdServsAllWndRqAuth 0 "No Request" 1 "Fully Open" 2 "Open Vent" 3 "Fully Closed" ;
VAL_ 1319 TGI1P_TlmRmtIgnBlkImbCmdAuth 0 "FALSE" 1 "TRUE" ;
VAL_ 1319 TGI1P_NewFobXmtrLrndRstAuth 0 "FALSE" 1 "TRUE" ;
VAL_ 1319 TGI1P_EnhdServsRmtStrtReqAuth 0 "No Activation" 1 "Engine Requested Off" 2 "Engine Requested On" ;
VAL_ 1319 TGI1P_EnhdServsLckReqAuth 0 "Lock All" 1 "Unlock All" 2 "No Action" ;
VAL_ 1319 GeofncngRstrctdZnSts 0 "Unknown" 1 "Restricted" 2 "Unrestricted" ;
VAL_ 1319 TVKRP_FobAvlReqAuth 0 "No Action" 1 "Disable" 2 "Enable" 3 "Return Results" ;
VAL_ 1319 TSGI1P_EnhdServsSnrfRqAuth 0 "No Request" 1 "Fully Open" 2 "Open Vent" 3 "Fully Closed" ;
VAL_ 1319 TSGI1P_EnhdServsRrClsrLckRqAuth 0 "No Request" 1 "Unlock" 2 "Lock" ;
VAL_ 1319 EnhdSrvsFrtStrCmptClsrLckRqAuth 0 "No Request" 1 "Unlock" 2 "Lock" ;
VAL_ 1311 TDAP_DrvrStMemIdfrAuth 0 "Memory 1" 1 "Memory 2" 2 "Memory 3" 3 "Memory 4" 4 "Memory 5" 5 "Memory 6" 6 "Memory 7" 7 "Unknown" ;
VAL_ 1311 TDAP_DrvrIdfrAuth 0 "Driver 1" 1 "Driver 2" 2 "Driver 3" 3 "Driver 4" 4 "Driver 5" 5 "Driver 6" 6 "Driver 7" 7 "Unknown" ;
VAL_ 1311 FTPP_TirePresLoIndOnAuth 0 "FALSE" 1 "TRUE" ;
VAL_ 1311 FTPP_ServWprSysCtlIndOnAuth 0 "FALSE" 1 "TRUE" ;
VAL_ 1311 FTPP_FrtCmptFaildToOpnIndOnAuth 0 "FALSE" 1 "TRUE" ;
VAL_ 1311 FTPP_FrtCmptAjrWrnIndOnAuth 0 "FALSE" 1 "TRUE" ;
VAL_ 1311 SCAOOARFKeyFobReqd 0 "FALSE" 1 "TRUE" ;
VAL_ 1311 SCAOOALFKeyFobReqd 0 "FALSE" 1 "TRUE" ;
VAL_ 1311 GnrcModeSwSts 0 "Unknown" 1 "Not Pressed" 2 "Pressed" 3 "Failed" ;
VAL_ 1316 TDAP_TeenDrvrActvAuth 0 "FALSE" 1 "TRUE" ;
VAL_ 1316 RIP_RmtIgnBlkImbCustClrCmdAuth 0 "FALSE" 1 "TRUE" ;
VAL_ 1316 RIP_NewFobXmtrLrndNtfnAuth 0 "FALSE" 1 "TRUE" ;
VAL_ 1316 FTPP_VirtCtlHdPrkLmpsAvalAuth 0 "Not Available" 1 "Available" ;
VAL_ 1316 FTPP_HdPrkLmpsCurrSeltnValAuth 0 "Unknown" 1 "Off" 2 "Auto" 3 "Parking" 4 "On" ;
VAL_ 1316 VMMP_VehMtnMvmtStatAuth 0 "Parked" 1 "Neutral" 2 "Forward" 3 "Reverse" 4 "Invalid" ;
VAL_ 1316 VKI2P_FobAvlStsAuth 0 "No Action" 1 "Disabled" 2 "Enabled" 3 "Fail" ;
VAL_ 1316 StrgWhlTchSnsDiagFA 0 "FALSE" 1 "TRUE" ;
VAL_ 1316 FleetDrvrActv 0 "FALSE" 1 "TRUE" ;
VAL_ 1316 AuthIntrUserIdDevSts 0 "Idle" 1 "Auth In Process" 2 "Auth In Process_Single Authenticated" 3 "Auth Complete_Not Authenticated" 4 "Auth Complete_Authenticated" 5 "Auth Complete_Undetermined" ;
VAL_ 713 RestrtVehIndOn 0 "FALSE" 1 "TRUE" ;
VAL_ 713 PrtctdIdlUnvIndOn 0 "FALSE" 1 "TRUE" ;
VAL_ 713 PrtctdIdlIndOn 0 "FALSE" 1 "TRUE" ;
VAL_ 713 NoKeyFndTryAgnIndOn 0 "FALSE" 1 "TRUE" ;
VAL_ 713 NoKeyDtdMechShfDndIndOn 0 "FALSE" 1 "TRUE" ;
VAL_ 713 KyIdDevNotPrIO 0 "FALSE" 1 "TRUE" ;
VAL_ 713 KeyMisgCkForKeyIndOn 0 "FALSE" 1 "TRUE" ;
VAL_ 713 KMORAI_IndOn 0 "FALSE" 1 "TRUE" ;
VAL_ 713 SSVI_AutoShtdnIO 0 "FALSE" 1 "TRUE" ;
VAL_ 713 SSVI_AutoShtdnDsbldIO 0 "FALSE" 1 "TRUE" ;
VAL_ 713 SSVI_AppPrkBrkIO 0 "FALSE" 1 "TRUE" ;
VAL_ 713 SSVI_AppClchPedIO 0 "FALSE" 1 "TRUE" ;
VAL_ 713 SSVI_AppBrkPedIO 0 "FALSE" 1 "TRUE" ;
VAL_ 713 SSVI_KylsStrtUseXmtrPcktIO 0 "FALSE" 1 "TRUE" ;
VAL_ 713 SSVI_KeyMvmtRqrdIndOn 0 "FALSE" 1 "TRUE" ;
VAL_ 713 SSVI_ClsEngCmptToStrtVehIO 0 "FALSE" 1 "TRUE" ;
VAL_ 713 SSVI_ShfToNeutPrssStrtAgnIO 0 "FALSE" 1 "TRUE" ;
VAL_ 713 SSVI_PrssStrtAgnIO 0 "FALSE" 1 "TRUE" ;
VAL_ 713 SSVI_PrssClchPrssStrtAgnIO 0 "FALSE" 1 "TRUE" ;
VAL_ 713 SSVI_PrssClchBrkForStrtIO 0 "FALSE" 1 "TRUE" ;
VAL_ 713 SSVI_PrssBtnAgnToTrnEngOffIO 0 "FALSE" 1 "TRUE" ;
VAL_ 713 SSVI_NoRmtDtdPrssClchToRestrtIO 0 "FALSE" 1 "TRUE" ;
VAL_ 713 SSVI_NoRmtDtdPrssBrkToRestrtIO 0 "FALSE" 1 "TRUE" ;
VAL_ 713 SSVI_NoRmtDtdIO 0 "FALSE" 1 "TRUE" ;
VAL_ 713 VhOpgStatUIDDtdPrssBrkToStrtIO 0 "FALSE" 1 "TRUE" ;
VAL_ 713 VhOpgStatClsDrOrPrssBrkToStrtIO 0 "FALSE" 1 "TRUE" ;
VAL_ 713 PPMVehOnExtModeActv 0 "FALSE" 1 "TRUE" ;
VAL_ 713 XmtrSecurConfRqrdIO 0 "FALSE" 1 "TRUE" ;
VAL_ 713 VehLoBatIndOn 0 "FALSE" 1 "TRUE" ;
VAL_ 713 VehInNeutShfToDrvIndOn 0 "FALSE" 1 "TRUE" ;
VAL_ 713 ShfToNeutRestrtVehIndOn 0 "FALSE" 1 "TRUE" ;
VAL_ 713 SSVI_ShfToPrkIO 0 "FALSE" 1 "TRUE" ;
VAL_ 713 PPMExtModeActvEnsBatChrgLvlIO 0 "FALSE" 1 "TRUE" ;
VAL_ 1171 RrStrgModeDispIndReq 0 "None" 1 "Automatic" 2 "Fixed" 3 "Crab" 4 "Crab Pending" 5 "Crab Ready" ;
VAL_ 1171 RrStrgFlrIndOn 0 "FALSE" 1 "TRUE" ;
VAL_ 1284 DrLckRRStsAuth 0 "Unknown" 1 "Locked" 2 "Unlocked" ;
VAL_ 1284 DrLckRFStsAuth 0 "Unknown" 1 "Locked" 2 "Unlocked" ;
VAL_ 1284 DrLckLRStsAuth 0 "Unknown" 1 "Locked" 2 "Unlocked" ;
VAL_ 1284 DrLckLFStsAuth 0 "Unknown" 1 "Locked" 2 "Unlocked" ;
VAL_ 1283 PnCActnReqCertfctTypAuth 0 "None" 1 "GM Provisioning Certificate" 2 "Contract Certificate" 3 "V2G Root Certificate" 4 "OCSP Certificate" 5 "Private Operator Root Certificate" 6 "Reserved1" 7 "Reserved2" 8 "Reserved3" 9 "Reserved4" 10 "Reserved5" 11 "Reserved6" 12 "Reserved7" 13 "Reserved8" 14 "All Contract And Private Operator Root Certificates" ;
VAL_ 1283 PnCActnReqCertfctOpAuth 0 "No Action" 1 "Disable Certificate" 2 "Enable Certificate" 3 "Erase Certificate" 4 "Install Certificate" ;
VAL_ 1283 PnCEnblReqAuth 0 "Unknown" 1 "No Action" 2 "Enable" 3 "Disable" ;
VAL_ 597 SuprRmtPrkVirtKeyPrkCmdAuth 0 "No Action" 1 "Initiate Parking" 2 "Pause Parking" 3 "Continue Parking" 4 "Power Off" 5 "Exit Maneuver" 6 "Forward Move" 7 "Backward Move" ;
VAL_ 597 SuprRmtPrkVirtKeyEntlmtStsAuth 0 "Not Granted" 1 "Granted" ;
VAL_ 597 VirtKeyMblDevLocZnAuth 0 "No Action" 1 "Inside Vehicle" 2 "Outside and Within Localization Area" 3 "Outside of Localization Area" 4 "Invalid" ;
VAL_ 878 RIP_PreRelAllwdAuth 0 "FALSE" 1 "TRUE" ;
VAL_ 878 RIP_ElecStrgColUnlckAllwdAuth 0 "FALSE" 1 "TRUE" ;
VAL_ 878 BGI1P_RmtVehStrtReqAuth 0 "FALSE" 1 "TRUE" ;
VAL_ 878 BGI1P_RmtStrtStsAuth 0 "Inactive" 1 "Active" ;
VAL_ 878 SPMP_PriRunCrnkCmdActvAuth 0 "FALSE" 1 "TRUE" ;
VAL_ 878 RIP_StrtStopIgnSwPrssdAuth 0 "FALSE" 1 "TRUE" ;
VAL_ 878 RIP_StrtStopIgnSwPrssdAuth_Inv 0 "FALSE" 1 "TRUE" ;
VAL_ 878 SPMP_SysPwrModeAuth_Inv 0 "FALSE" 1 "TRUE" ;
VAL_ 878 SPMP_SysPwrModeAuth 0 "Off" 1 "Accessory" 2 "Run" 3 "Start Request" 4 "Propulsion" ;
VAL_ 878 SPMP_PriRunCrnkCmdActvAuth_Inv 0 "FALSE" 1 "TRUE" ;
VAL_ 1299 TGPSDSP_UTCMonthAuth 0 "Unknown" 1 "January" 2 "February" 3 "March" 4 "April" 5 "May" 6 "June" 7 "July" 8 "August" 9 "September" 10 "October" 11 "November" 12 "December" ;
VAL_ 1299 TGPSDSP_UTCDyAuth_Inv 0 "FALSE" 1 "TRUE" ;
VAL_ 1299 TGPSDSP_UTCMonthAuth_Inv 0 "FALSE" 1 "TRUE" ;
VAL_ 1299 TGPSDSP_DateSrcAuth 0 "Signal_Unavailable" 1 "Synchronized_RTC_Used_And_GPS_Unavailable" 2 "GPS" 3 "Cellular" ;
VAL_ 1299 TGPSDSP_UTCYrAuth_Inv 0 "FALSE" 1 "TRUE" ;
VAL_ 1299 TGPSDSP_DateSrcAuth_Inv 0 "FALSE" 1 "TRUE" ;
VAL_ 865 TGPSTSP_TmSrcAuth_Inv 0 "FALSE" 1 "TRUE" ;
VAL_ 865 TGPSTSP_TmSrcAuth 0 "Signal_Unavailable" 1 "Synchronized_RTC_Used_And_GPS_Unavailable" 2 "GPS" 3 "Cellular" ;
VAL_ 865 TGPSTSP_UTCHrsAuth_Inv 0 "FALSE" 1 "TRUE" ;
VAL_ 865 TGPSTSP_UTCSecsAuth_Inv 0 "FALSE" 1 "TRUE" ;
VAL_ 865 TGPSTSP_UTCMinsAuth_Inv 0 "FALSE" 1 "TRUE" ;
VAL_ 601 DgtlKeyMgmtReqAuth 0 "No Request" 1 "Terminate Digital Key" 2 "Terminate All Keys" 3 "Suspend Digital Key" 4 "Suspend All Keys" 5 "Resume Digital Key" 6 "Resume All Keys" ;
VAL_ 592 DgtlKeyMgmtRespAuth 0 "No Action" 1 "Digital Key Terminated" 2 "All Keys Terminated" 3 "Digital Key Suspended" 4 "All Keys Suspended" 5 "Digital Key Resumed" 6 "All Keys Resumed" 7 "Key Does Not Exist" 8 "Digital Key Expired" 9 "Digital Key Authenticated" ;
VAL_ 1928 ChrgCommCtlrMACAddr_DuD 0 "FALSE" 1 "TRUE" ;
VAL_ 621 VICMI1P_AutoDrvShfSysStsPriAuth 0 "Unknown" 1 "Shift In Progress" 2 "Control Override" 3 "Error" 4 "Standby" ;
VAL_ 621 HiVltgChrgCommEnblReq 0 "Unknown" 1 "Communication Requested" 2 "Communication Not Requested" ;
VAL_ 621 VICMI1P_ADShfSysHlthStsPriAuth 0 "Unknown" 1 "Normal" 2 "Degraded Functional" 3 "Failed in Range Functional" 4 "Failed Defaulted" ;
VAL_ 621 VICMI1P_AuxPwrModStsAuth 0 "NormConvNormTempLo" 1 "NormConvNormTempHi" 2 "Derated" 3 "HighTempNearDerated" 4 "Dsbld" 5 "HiTempDsbldDerated" 6 "Indeterminate" 7 "CommandedOff" 8 "OverTempConvDerated" 9 "NormLoad" 10 "NearDerated" ;
VAL_ 1298 UpftrRmtVehStrtReqd 0 "FALSE" 1 "TRUE" ;
VAL_ 1298 UpftrSnwPlwLoBmDsblReqd 0 "FALSE" 1 "TRUE" ;
VAL_ 1298 VODVP_VehOdoDispValAuth_Inv 0 "FALSE" 1 "TRUE" ;
VAL_ 1297 VOSDVP_VehOdoStrdDspValAuth_Inv 0 "FALSE" 1 "TRUE" ;
VAL_ 614 VSADP_RdcdPwrIndOnAuth 0 "FALSE" 1 "TRUE" ;
VAL_ 614 VSADP_FuelModeStsAuth 0 "Unknown" 1 "Gasoline Mode" 2 "Natural Gas Mode" 3 "Liquified Petroleum Gas Mode" 4 "Alternative Fuel Cut-off Active" ;
VAL_ 614 EngEmsRltMlfIndRq 0 "Continuous Indication" 1 "No Indication" 2 "Flashing 1 Hertz Indication" 3 "Flashing 2 Hertz Indication" 4 "Flashing 0.5 Hertz Indication" ;
VAL_ 614 VSADP_VehSpdAvgDrvnSrcAuth 0 "Transmission Output Speed" 1 "Wheel Speed" ;
VAL_ 614 VSADP_VehSpdAvgDrvnAuth_Inv 0 "FALSE" 1 "TRUE" ;
VAL_ 1303 VPMGI1P_ITAux2CamConctStsAuth 0 "Unknown" 1 "Not Connected" 2 "Connected" ;
VAL_ 1303 VPMGI1P_ITAux1CamConctStsAuth 0 "Unknown" 1 "Not Connected" 2 "Connected" ;
